VERSION ""

NS_ :

BS_:

BU_: MCU IPU MCU_B BMS ECC VCU EVCC MCU_F HDCU LBMS VCU5_0 VCU_BMS GW EOP Tester IDC

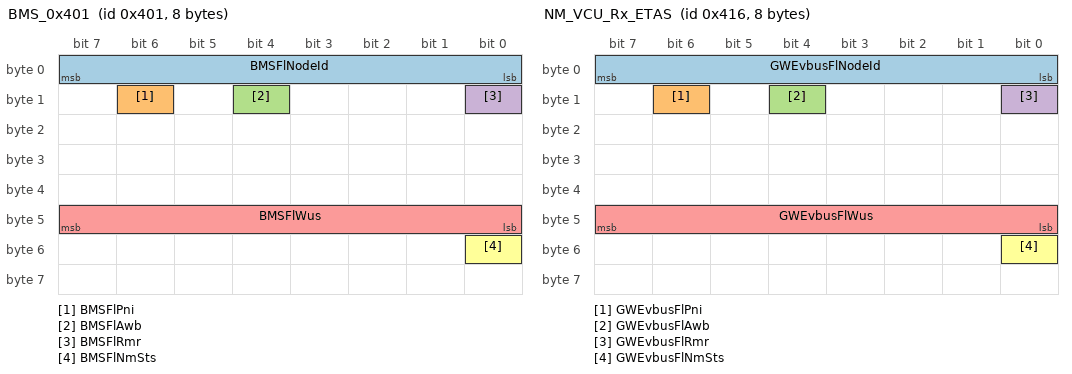
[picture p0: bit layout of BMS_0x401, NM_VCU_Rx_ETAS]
BO_ 1025 BMS_0x401: 8 BMS
 SG_ BMSFlNodeId : 7|8@0+ (1,0) [0|127] ""  IPU,MCU_B,ECC,VCU,EVCC,MCU_F,HDCU,LBMS,VCU5_0,GW,MCU
 SG_ BMSFlPni : 14|1@0+ (1,0) [0|1] ""  IPU,MCU_B,ECC,VCU,EVCC,MCU_F,HDCU,LBMS,VCU5_0,GW,MCU
 SG_ BMSFlAwb : 12|1@0+ (1,0) [0|1] ""  IPU,MCU_B,ECC,VCU,EVCC,MCU_F,HDCU,LBMS,VCU5_0,GW,MCU
 SG_ BMSFlRmr : 8|1@0+ (1,0) [0|1] ""  IPU,MCU_B,ECC,VCU,EVCC,MCU_F,HDCU,LBMS,VCU5_0,GW,MCU
 SG_ BMSFlWus : 47|8@0+ (1,0) [0|255] ""  IPU,MCU_B,ECC,VCU,EVCC,MCU_F,HDCU,LBMS,VCU5_0,GW,MCU
 SG_ BMSFlNmSts : 48|1@0+ (1,0) [0|1] ""  IPU,MCU_B,ECC,VCU,EVCC,MCU_F,HDCU,LBMS,VCU5_0,GW,MCU

BO_ 1046 NM_VCU_Rx_ETAS: 8 GW
 SG_ GWEvbusFlNodeId : 7|8@0+ (1,0) [0|127] ""  IPU,MCU_B,BMS,ECC,VCU,EVCC,MCU_F,HDCU,LBMS,VCU5_0,VCU_BMS,MCU
 SG_ GWEvbusFlPni : 14|1@0+ (1,0) [0|1] ""  IPU,MCU_B,BMS,ECC,VCU,EVCC,MCU_F,HDCU,LBMS,VCU5_0,VCU_BMS,MCU
 SG_ GWEvbusFlAwb : 12|1@0+ (1,0) [0|1] ""  IPU,MCU_B,BMS,ECC,VCU,EVCC,MCU_F,HDCU,LBMS,VCU5_0,VCU_BMS,MCU
 SG_ GWEvbusFlRmr : 8|1@0+ (1,0) [0|1] ""  IPU,MCU_B,BMS,ECC,VCU,EVCC,MCU_F,HDCU,LBMS,VCU5_0,VCU_BMS,MCU
 SG_ GWEvbusFlWus : 47|8@0+ (1,0) [0|255] ""  IPU,MCU_B,BMS,ECC,VCU,EVCC,MCU_F,HDCU,LBMS,VCU5_0,VCU_BMS,MCU
 SG_ GWEvbusFlNmSts : 48|1@0+ (1,0) [0|1] ""  IPU,MCU_B,BMS,ECC,VCU,EVCC,MCU_F,HDCU,LBMS,VCU5_0,VCU_BMS,MCU

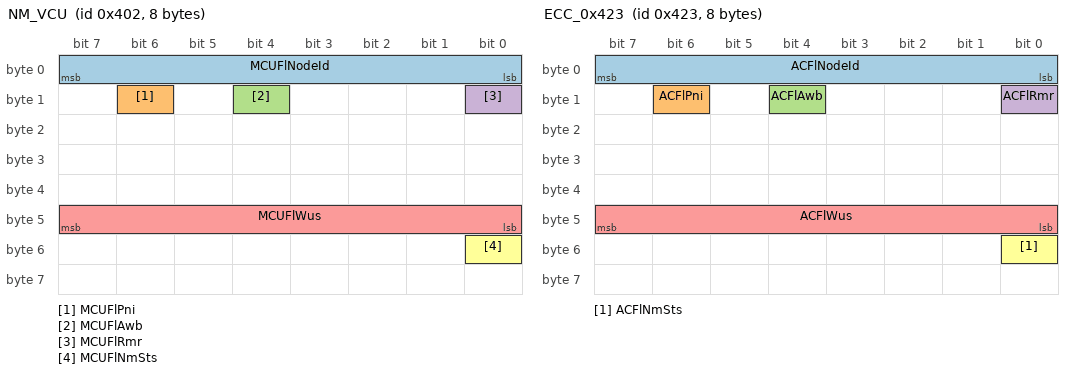
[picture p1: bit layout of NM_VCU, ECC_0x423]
BO_ 1026 NM_VCU: 8 MCU
 SG_ MCUFlNodeId : 7|8@0+ (1,0) [0|127] ""  IPU,BMS,ECC,VCU,EVCC,HDCU,LBMS,VCU5_0,VCU_BMS,GW
 SG_ MCUFlPni : 14|1@0+ (1,0) [0|1] ""  IPU,BMS,ECC,VCU,EVCC,HDCU,LBMS,VCU5_0,VCU_BMS,GW
 SG_ MCUFlAwb : 12|1@0+ (1,0) [0|1] ""  IPU,BMS,ECC,VCU,EVCC,HDCU,LBMS,VCU5_0,VCU_BMS,GW
 SG_ MCUFlRmr : 8|1@0+ (1,0) [0|1] ""  IPU,BMS,ECC,VCU,EVCC,HDCU,LBMS,VCU5_0,VCU_BMS,GW
 SG_ MCUFlWus : 47|8@0+ (1,0) [0|255] ""  IPU,BMS,ECC,VCU,EVCC,HDCU,LBMS,VCU5_0,VCU_BMS,GW
 SG_ MCUFlNmSts : 48|1@0+ (1,0) [0|1] ""  IPU,BMS,ECC,VCU,EVCC,HDCU,LBMS,VCU5_0,VCU_BMS,GW

BO_ 1059 ECC_0x423: 8 ECC
 SG_ ACFlNodeId : 7|8@0+ (1,0) [0|127] ""  IPU,MCU_B,BMS,VCU,LBMS,VCU_BMS,GW,MCU
 SG_ ACFlPni : 14|1@0+ (1,0) [0|1] ""  IPU,MCU_B,BMS,VCU,LBMS,VCU_BMS,GW,MCU
 SG_ ACFlAwb : 12|1@0+ (1,0) [0|1] ""  IPU,MCU_B,BMS,VCU,LBMS,VCU_BMS,GW,MCU
 SG_ ACFlRmr : 8|1@0+ (1,0) [0|1] ""  IPU,MCU_B,BMS,VCU,LBMS,VCU_BMS,GW,MCU
 SG_ ACFlWus : 47|8@0+ (1,0) [0|255] ""  IPU,MCU_B,BMS,VCU,LBMS,VCU_BMS,GW,MCU
 SG_ ACFlNmSts : 48|1@0+ (1,0) [0|1] ""  IPU,MCU_B,BMS,VCU,LBMS,VCU_BMS,GW,MCU

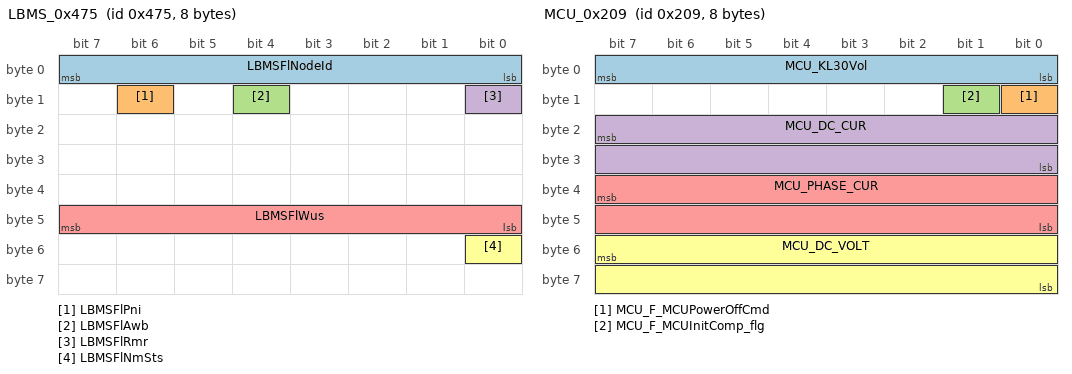
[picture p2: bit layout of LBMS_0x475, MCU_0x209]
BO_ 1141 LBMS_0x475: 8 LBMS
 SG_ LBMSFlNodeId : 7|8@0+ (1,0) [0|127] ""  IPU,MCU_B,BMS,ECC,VCU,EVCC,MCU_F,HDCU,VCU5_0,VCU_BMS,GW,MCU
 SG_ LBMSFlPni : 14|1@0+ (1,0) [0|1] ""  IPU,MCU_B,BMS,ECC,VCU,EVCC,MCU_F,HDCU,VCU5_0,VCU_BMS,GW,MCU
 SG_ LBMSFlAwb : 12|1@0+ (1,0) [0|1] ""  IPU,MCU_B,BMS,ECC,VCU,EVCC,MCU_F,HDCU,VCU5_0,VCU_BMS,GW,MCU
 SG_ LBMSFlRmr : 8|1@0+ (1,0) [0|1] ""  IPU,MCU_B,BMS,ECC,VCU,EVCC,MCU_F,HDCU,VCU5_0,VCU_BMS,GW,MCU
 SG_ LBMSFlWus : 47|8@0+ (1,0) [0|255] ""  IPU,MCU_B,BMS,ECC,VCU,EVCC,MCU_F,HDCU,VCU5_0,VCU_BMS,GW,MCU
 SG_ LBMSFlNmSts : 48|1@0+ (1,0) [0|1] ""  IPU,MCU_B,BMS,ECC,VCU,EVCC,MCU_F,HDCU,VCU5_0,VCU_BMS,GW,MCU

BO_ 521 MCU_0x209: 8 MCU_B
 SG_ MCU_KL30Vol : 7|8@0+ (0.1,0) [0|25.5] ""  GW
 SG_ MCU_F_MCUPowerOffCmd : 8|1@0+ (1,0) [0|1] ""  GW
 SG_ MCU_F_MCUInitComp_flg : 9|1@0+ (1,0) [0|1] ""  GW
 SG_ MCU_DC_CUR : 23|16@0+ (0.1,-3276.8) [-3276.8|3276.7] "A"  BMS,VCU,VCU5_0,VCU_BMS,GW
 SG_ MCU_PHASE_CUR : 39|16@0+ (0.1,-3276.8) [-3276.8|3276.7] "A"  VCU,VCU5_0,VCU_BMS,GW
 SG_ MCU_DC_VOLT : 55|16@0+ (0.02,0) [0|1310.68] "V"  BMS,VCU,VCU5_0,VCU_BMS,GW

BO_ 296 MCU_0x128: 24 MCU
 SG_ dmc_dTcsDbgSignal1_M1 : 7|8@0+ (1,0) [0|255] ""  GW
 SG_ dmc_TcsDbgSiqnal2_M1 : 14|15@0+ (1,0) [0|32767] ""  GW
 SG_ dmc_dTcsDbgSignal3_M1 : 30|15@0+ (1,0) [0|32767] "rpm"  GW
 SG_ dmc_dTcsDbgSignal4_M1 : 47|8@0+ (1,0) [0|255] ""  GW
 SG_ dmc_dTcsDbgSignal5_M1 : 55|8@0+ (1,0) [0|255] ""  GW
 SG_ DmcFrtDTCSOperaMode : 58|3@0+ (1,0) [0|7] ""  GW
 SG_ dmc_dTcsDbgSignal6_M1 : 71|16@0+ (1,-32767) [-32767|32767] "N.m"  GW
 SG_ dmc_dTcsDbgSignal7_M1 : 87|16@0+ (1,-32767) [-32767|32767] "N.m"  GW
 SG_ dmc_dTcsDbgSignal8_M1 : 103|16@0+ (1,-32767) [-32767|32767] "N.m"  GW
 SG_ dmc_dTcsDbgSignal9_M1 : 119|16@0+ (1,-32767) [-32767|32767] "N.m"  GW
 SG_ dmc_drcsDbgSignal10_M1 : 134|15@0+ (1,0) [0|32767] ""  GW
 SG_ dmc_drcsDbgSignal11_M1 : 151|16@0+ (1,-32767) [-32767|32767] "N.m"  GW
 SG_ dmc_drcsDbgSignal12_M1 : 167|16@0+ (1,-32767) [-32767|32767] "N.m"  GW
 SG_ DmcFrtDTCSTargTorq : 183|16@0+ (1,-32767) [-32767|32767] "N.m"  GW

BO_ 1152 OBC_0x480: 16 IPU
 SG_ IPUCPAmp : 23|8@0+ (0.1,0) [0|25.5] "V"  HDCU,VCU5_0,GW
 SG_ OBC_DCCrt : 31|16@0+ (0.02,0) [0|1310.68] "A"  BMS,VCU,HDCU,VCU5_0,VCU_BMS,GW
 SG_ OBC_DCVolt : 47|16@0+ (0.02,0) [0|1310.68] "V"  BMS,VCU,HDCU,VCU5_0,VCU_BMS,GW
 SG_ IPUCPDutyRat : 63|8@0+ (1,0) [0|100] "%"  HDCU,VCU5_0,GW
 SG_ IPUWakupsou : 87|8@0+ (1,0) [0|255] ""  HDCU,VCU5_0,GW
 SG_ IPUCPDir : 89|2@0+ (1,0) [0|3] ""  HDCU,VCU5_0,GW
 SG_ IPUHeatReqFlg : 91|2@0+ (1,0) [0|3] ""  BMS,ECC,VCU,VCU5_0,VCU_BMS,GW
 SG_ IPUCCR : 103|16@0+ (1,0) [0|4095] "Ω"  HDCU,VCU5_0,GW
 SG_ IPUCPFrq : 119|16@0+ (1,0) [0|2000] "Hz"  HDCU,VCU5_0,GW

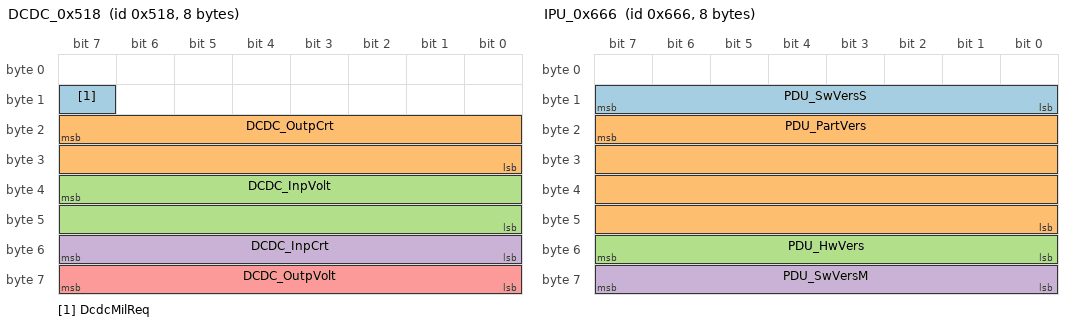
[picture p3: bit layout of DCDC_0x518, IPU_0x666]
BO_ 1304 DCDC_0x518: 8 IPU
 SG_ DcdcMilReq : 15|1@0+ (1,0) [0|1] ""  HDCU,GW
 SG_ DCDC_OutpCrt : 23|16@0+ (0.01,0) [0|300] "A"  VCU,HDCU,LBMS,VCU5_0,VCU_BMS,GW
 SG_ DCDC_InpVolt : 39|16@0+ (0.02,0) [0|1310.68] "V"  BMS,VCU,HDCU,VCU5_0,VCU_BMS,GW
 SG_ DCDC_InpCrt : 55|8@0+ (0.1,0) [0|25.4] "A"  BMS,VCU,HDCU,VCU5_0,VCU_BMS,GW
 SG_ DCDC_OutpVolt : 63|8@0+ (0.1,0) [0|25.5] "V"  VCU,HDCU,LBMS,VCU5_0,VCU_BMS,GW

BO_ 1313 DCDC_0x521: 8 IPU
 SG_ DCDC_InpOverVoltSwFlt : 16|1@0+ (1,0) [0|1] ""  VCU,HDCU,VCU5_0,VCU_BMS,GW
 SG_ DCDC_InpUnderVoltFlt : 17|1@0+ (1,0) [0|1] ""  VCU,HDCU,VCU5_0,VCU_BMS,GW
 SG_ DCDC_LVOutpOverVoltFlt : 18|1@0+ (1,0) [0|1] ""  VCU,HDCU,VCU5_0,VCU_BMS,GW
 SG_ DCDC_LVOutpUnderVoltFlt : 19|1@0+ (1,0) [0|1] ""  VCU,HDCU,VCU5_0,VCU_BMS,GW
 SG_ PDU_BusoffFlt : 20|1@0+ (1,0) [0|1] ""  VCU,HDCU,VCU5_0,VCU_BMS,GW
 SG_ DCDC_OverTTurnDwnLoadFlt : 21|1@0+ (1,0) [0|1] ""  VCU,HDCU,VCU5_0,VCU_BMS,GW
 SG_ IPU_ComCheckErr : 22|1@0+ (1,0) [0|1] ""  VCU,HDCU,VCU5_0,VCU_BMS,GW
 SG_ DCDC_InpCurOverSwFlt : 23|1@0+ (1,0) [0|1] ""  VCU,HDCU,VCU5_0,VCU_BMS,GW
 SG_ DCDC_OverTShutDwnFlt : 24|1@0+ (1,0) [0|1] ""  VCU,HDCU,VCU5_0,VCU_BMS,GW
 SG_ DCDC_StsAlrmFlt : 25|1@0+ (1,0) [0|1] ""  VCU,HDCU,VCU5_0,VCU_BMS,GW
 SG_ DCDC_CrtStsGB : 27|2@0+ (1,0) [0|2] ""  HDCU,GW
 SG_ DCDC_LVOutpOverCurrFlt : 28|1@0+ (1,0) [0|1] ""  VCU,HDCU,VCU5_0,VCU_BMS,GW
 SG_ IPU_KL30Vol : 39|8@0+ (0.1,0) [0|25.5] "V"  VCU,HDCU,VCU5_0,VCU_BMS,GW
 SG_ DCDC_St_TMP : 47|8@0+ (1,-48) [-48|206] "℃"  VCU,HDCU,VCU5_0,VCU_BMS,GW
 SG_ DCDC_INPUT_VOLT_CHECK_FLT : 48|1@0+ (1,0) [0|1] ""  VCU,HDCU,VCU5_0,VCU_BMS,GW
 SG_ DCDC_OUTPUT_VOLT_CHECK_FLT : 49|1@0+ (1,0) [0|1] ""  VCU,HDCU,VCU5_0,VCU_BMS,GW
 SG_ DCDC_IntFlt : 50|1@0+ (1,0) [0|1] ""  VCU,HDCU,VCU5_0,VCU_BMS,GW
 SG_ DCDC_ComLostFlt_PDCU : 51|1@0+ (1,0) [0|1] ""  VCU,HDCU,VCU5_0,VCU_BMS,GW
 SG_ DCDC_OutpShoCircFlt : 52|1@0+ (1,0) [0|1] ""  VCU,HDCU,VCU5_0,VCU_BMS,GW
 SG_ DCDC_CrtSts : 54|2@0+ (1,0) [0|3] ""  BMS,ECC,VCU,HDCU,LBMS,VCU5_0,VCU_BMS,GW
 SG_ BoostCurOverFlt : 55|1@0+ (1,0) [0|1] ""  VCU,HDCU,VCU5_0,VCU_BMS,GW
 SG_ DCDC_T : 63|8@0+ (1,-40) [-40|215] "℃"  BMS,VCU,HDCU,VCU5_0,VCU_BMS,GW

BO_ 1638 IPU_0x666: 8 IPU
 SG_ PDU_SwVersS : 15|8@0+ (1,0) [0|255] ""  VCU,HDCU,VCU5_0,VCU_BMS,GW
 SG_ PDU_PartVers : 23|32@0+ (1,0) [0|4294967295] ""  VCU,HDCU,VCU5_0,VCU_BMS,GW
 SG_ PDU_HwVers : 55|8@0+ (1,0) [0|255] ""  VCU,HDCU,VCU5_0,VCU_BMS,GW
 SG_ PDU_SwVersM : 63|8@0+ (1,0) [0|255] ""  VCU,HDCU,VCU5_0,VCU_BMS,GW

BO_ 1746 OBC_0x6D2: 8 IPU
 SG_ OBC_HVDCOutpOverCrtHwFlt : 16|1@0+ (1,0) [0|1] ""  VCU,HDCU,VCU5_0,VCU_BMS,GW
 SG_ OBC_HVDCOutpShortFlt : 17|1@0+ (1,0) [0|1] ""  VCU,HDCU,VCU5_0,VCU_BMS,GW
 SG_ PFC_PowFreMOSOverTFlt : 18|1@0+ (1,0) [0|1] ""  VCU,HDCU,VCU5_0,VCU_BMS,GW
 SG_ OBC_ACVoltOverVoltFlt : 19|1@0+ (1,0) [0|1] ""  VCU,HDCU,VCU5_0,VCU_BMS,GW
 SG_ OBC_ACVoltUnderVoltFlt : 20|1@0+ (1,0) [0|1] ""  VCU,HDCU,VCU5_0,VCU_BMS,GW
 SG_ OBC_HVDCOutpOverVoltSwFlt : 21|1@0+ (1,0) [0|1] ""  VCU,HDCU,VCU5_0,VCU_BMS,GW
 SG_ OBC_HVDCOutpUnderVoltFlt : 22|1@0+ (1,0) [0|1] ""  VCU,HDCU,VCU5_0,VCU_BMS,GW
 SG_ OBC_InpCrtOverCrtHwSwFlt : 23|1@0+ (1,0) [0|1] ""  VCU,HDCU,VCU5_0,VCU_BMS,GW
 SG_ PFC_MOSOverTFlt : 24|1@0+ (1,0) [0|1] ""  VCU,HDCU,VCU5_0,VCU_BMS,GW
 SG_ LLC_OriSideMOSOverTFlt : 25|1@0+ (1,0) [0|1] ""  VCU,HDCU,VCU5_0,VCU_BMS,GW
 SG_ OBC_ACPoweroff : 26|1@0+ (1,0) [0|1] ""  GW
 SG_ DiscCPSIGErr : 27|1@0+ (1,0) [0|1] ""  HDCU,GW
 SG_ OBC_LVOutpOverVoltFlt : 28|1@0+ (1,0) [0|1] ""  VCU,HDCU,VCU5_0,VCU_BMS,GW
 SG_ OBC_LiquidOverTShutDwnFlt : 29|1@0+ (1,0) [0|1] ""  VCU,HDCU,VCU5_0,VCU_BMS,GW
 SG_ OBC_LiquidOverTDwnPwrFlt : 30|1@0+ (1,0) [0|1] ""  VCU,HDCU,VCU5_0,VCU_BMS,GW
 SG_ LLC_SenSideMOSOverTFlt : 31|1@0+ (1,0) [0|1] ""  VCU,HDCU,VCU5_0,VCU_BMS,GW
 SG_ OBC_HVDCOutpOverVoltHwFlt : 32|1@0+ (1,0) [0|1] ""  HDCU,GW
 SG_ OBC_INVOutpShortFlt : 33|1@0+ (1,0) [0|1] ""  HDCU,GW
 SG_ OBC_INVOutpOverLoadFlt : 34|1@0+ (1,0) [0|1] ""  HDCU,GW
 SG_ OBC_PfcCllcSciLost : 35|1@0+ (1,0) [0|1] ""  HDCU,GW
 SG_ OBC_IntOverTFlt : 36|1@0+ (1,0) [0|1] ""  VCU,HDCU,VCU5_0,VCU_BMS,GW
 SG_ OBC_IntFlt : 37|1@0+ (1,0) [0|1] ""  VCU,HDCU,VCU5_0,VCU_BMS,GW
 SG_ BOBC_OverTFlt : 38|1@0+ (1,0) [0|1] ""  VCU,HDCU,VCU5_0,VCU_BMS,GW
 SG_ PFCBusOverVoltFlt : 39|1@0+ (1,0) [0|1] ""  VCU,HDCU,VCU5_0,VCU_BMS,GW
 SG_ OBC_HVDCOutpOverCrtSwFlt : 40|1@0+ (1,0) [0|1] ""  VCU,HDCU,VCU5_0,VCU_BMS,GW
 SG_ OBC_ACCrtChkCircFlt : 41|1@0+ (1,0) [0|1] ""  VCU,HDCU,VCU5_0,VCU_BMS,GW
 SG_ PFCBusUnderVoltFlt : 42|1@0+ (1,0) [0|1] ""  VCU,HDCU,VCU5_0,VCU_BMS,GW
 SG_ OBC_INVOutpOverVoltFlt : 43|1@0+ (1,0) [0|1] ""  VCU,HDCU,VCU5_0,VCU_BMS,GW
 SG_ OBC_INVOutpUnderVoltFlt : 44|1@0+ (1,0) [0|1] ""  VCU,HDCU,VCU5_0,VCU_BMS,GW
 SG_ OBC_INVInpOverVoltFlt : 45|1@0+ (1,0) [0|1] ""  VCU,HDCU,VCU5_0,VCU_BMS,GW
 SG_ OBC_INVInpUnderVoltFlt : 46|1@0+ (1,0) [0|1] ""  VCU,HDCU,VCU5_0,VCU_BMS,GW
 SG_ OBC_INVOutpOverCurrSlowFlt : 47|1@0+ (1,0) [0|1] ""  VCU,HDCU,VCU5_0,VCU_BMS,GW
 SG_ ACInputPhaTypeFlt : 48|1@0+ (1,0) [0|1] ""  VCU,HDCU,VCU5_0,VCU_BMS,GW
 SG_ CLLCChaStsInpUnderVoltFlt : 49|1@0+ (1,0) [0|1] ""  VCU,HDCU,VCU5_0,VCU_BMS,GW
 SG_ BOBC_CCSIG_ERR : 50|1@0+ (1,0) [0|1] ""  VCU,HDCU,VCU5_0,VCU_BMS,GW
 SG_ BOBC_CPSIG_ERR : 51|1@0+ (1,0) [0|1] ""  VCU,HDCU,VCU5_0,VCU_BMS,GW
 SG_ OBC_LVOutpUnderVoltFlt : 52|1@0+ (1,0) [0|1] ""  VCU,HDCU,VCU5_0,VCU_BMS,GW
 SG_ BOBC_PowOverVoltHwFlt : 53|1@0+ (1,0) [0|1] ""  VCU,HDCU,VCU5_0,VCU_BMS,GW
 SG_ ACFreLowFlt : 54|1@0+ (1,0) [0|1] ""  VCU,HDCU,VCU5_0,VCU_BMS,GW
 SG_ ACFreHighFlt : 55|1@0+ (1,0) [0|1] ""  VCU,HDCU,VCU5_0,VCU_BMS,GW
 SG_ BOBC_BatOverCurrHwFlt : 56|1@0+ (1,0) [0|1] ""  VCU,HDCU,VCU5_0,VCU_BMS,GW
 SG_ OBC_InpCrtOverCrtHwFlt : 57|1@0+ (1,0) [0|1] ""  VCU,HDCU,VCU5_0,VCU_BMS,GW
 SG_ OBC_ACVoltFreqFlt : 58|1@0+ (1,0) [0|1] ""  VCU,HDCU,VCU5_0,VCU_BMS,GW
 SG_ BUSMidVoltFlt : 59|1@0+ (1,0) [0|1] ""  VCU,HDCU,VCU5_0,VCU_BMS,GW
 SG_ OBC_ACSCIntlkSigChkCircFlt : 60|1@0+ (1,0) [0|1] ""  VCU,HDCU,VCU5_0,VCU_BMS,GW
 SG_ OBC_PTCIntlkSigChkCircFlt : 61|1@0+ (1,0) [0|1] ""  VCU,HDCU,VCU5_0,VCU_BMS,GW
 SG_ OBC_PwrBattIntlkSigChkCircFlt : 62|1@0+ (1,0) [0|1] ""  VCU,HDCU,VCU5_0,VCU_BMS,GW
 SG_ OBC_INVCllcBusOverVoltFlt : 63|1@0+ (1,0) [0|1] ""  VCU,HDCU,VCU5_0,VCU_BMS,GW

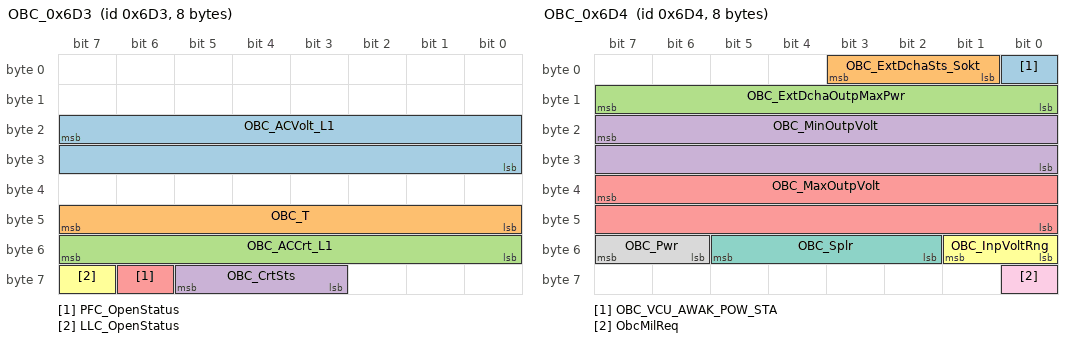
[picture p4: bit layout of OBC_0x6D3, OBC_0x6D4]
BO_ 1747 OBC_0x6D3: 8 IPU
 SG_ OBC_ACVolt_L1 : 23|16@0+ (0.02,0) [0|1310.68] "V"  BMS,VCU,EVCC,HDCU,VCU5_0,VCU_BMS,GW
 SG_ OBC_T : 47|8@0+ (1,-48) [-48|206] "℃"  ECC,VCU,HDCU,VCU5_0,VCU_BMS,GW
 SG_ OBC_ACCrt_L1 : 55|8@0+ (0.5,0) [0|127] "A"  BMS,VCU,EVCC,HDCU,VCU5_0,VCU_BMS,GW
 SG_ OBC_CrtSts : 61|3@0+ (1,0) [0|7] ""  BMS,ECC,VCU,HDCU,VCU5_0,VCU_BMS,GW
 SG_ PFC_OpenStatus : 62|1@0+ (1,0) [0|1] ""  VCU,HDCU,VCU5_0,VCU_BMS,GW
 SG_ LLC_OpenStatus : 63|1@0+ (1,0) [0|1] ""  VCU,HDCU,VCU5_0,VCU_BMS,GW

BO_ 1748 OBC_0x6D4: 8 IPU
 SG_ OBC_VCU_AWAK_POW_STA : 0|1@0+ (1,0) [0|1] ""  BMS,VCU,HDCU,VCU5_0,VCU_BMS,GW
 SG_ OBC_ExtDchaSts_Sokt : 3|3@0+ (1,0) [0|7] ""  VCU,HDCU,VCU5_0,VCU_BMS,GW
 SG_ OBC_ExtDchaOutpMaxPwr : 15|8@0+ (0.1,0) [0|25.5] "kW"  VCU,HDCU,VCU5_0,VCU_BMS,GW
 SG_ OBC_MinOutpVolt : 23|16@0+ (0.02,0) [0|1310.68] "V"  VCU,HDCU,VCU5_0,VCU_BMS,GW
 SG_ OBC_MaxOutpVolt : 39|16@0+ (0.02,0) [0|1310.68] "V"  VCU,HDCU,VCU5_0,VCU_BMS,GW
 SG_ OBC_InpVoltRng : 49|2@0+ (1,0) [0|3] ""  VCU,HDCU,VCU5_0,VCU_BMS,GW
 SG_ OBC_Splr : 53|4@0+ (1,0) [0|15] ""  VCU,HDCU,VCU5_0,VCU_BMS,GW
 SG_ OBC_Pwr : 55|2@0+ (1,0) [0|3] ""  BMS,VCU,HDCU,VCU5_0,VCU_BMS,GW
 SG_ ObcMilReq : 56|1@0+ (1,0) [0|1] ""  HDCU,GW

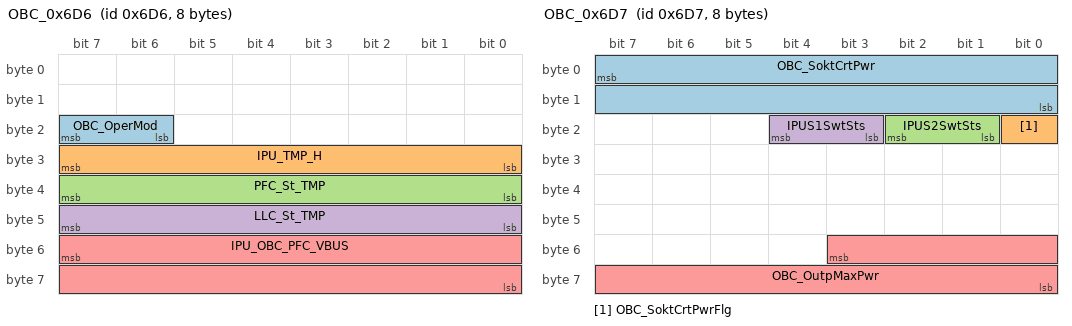
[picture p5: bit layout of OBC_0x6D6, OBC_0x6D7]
BO_ 1750 OBC_0x6D6: 8 IPU
 SG_ OBC_OperMod : 23|2@0+ (1,0) [0|3] ""  BMS,VCU,HDCU,VCU5_0,VCU_BMS,GW
 SG_ IPU_TMP_H : 31|8@0+ (1,-48) [-48|206] "℃"  BMS,VCU,HDCU,VCU5_0,VCU_BMS,GW
 SG_ PFC_St_TMP : 39|8@0+ (1,-48) [-48|206] "℃"  BMS,VCU,HDCU,VCU5_0,VCU_BMS,GW
 SG_ LLC_St_TMP : 47|8@0+ (1,-48) [-48|206] "℃"  BMS,VCU,HDCU,VCU5_0,VCU_BMS,GW
 SG_ IPU_OBC_PFC_VBUS : 55|16@0+ (0.02,0) [0|1310.68] "V"  BMS,VCU,HDCU,VCU5_0,VCU_BMS,GW

BO_ 1751 OBC_0x6D7: 8 IPU
 SG_ OBC_SoktCrtPwr : 7|16@0+ (0.1,0) [0|6553.5] "W"  VCU,HDCU,VCU5_0,VCU_BMS,GW
 SG_ OBC_SoktCrtPwrFlg : 16|1@0+ (1,0) [0|1] ""  VCU,HDCU,VCU5_0,VCU_BMS,GW
 SG_ IPUS2SwtSts : 18|2@0+ (1,0) [0|3] ""  HDCU,VCU5_0,GW
 SG_ IPUS1SwtSts : 20|2@0+ (1,0) [0|3] ""  HDCU,VCU5_0,GW
 SG_ OBC_OutpMaxPwr : 51|12@0+ (0.01,0) [0|20] "kW"  BMS,VCU,HDCU,VCU5_0,VCU_BMS,GW

BO_ 1324 ECC_VCU_0x52C: 64 ECC
 SG_ EWP_FD_Sts : 31|2@0+ (1,0) [0|3] ""  MCU_B,VCU,VCU_BMS,GW,MCU

BO_ 1010 ECC_AAC_VCU_0x3F2: 8 ECC
 SG_ OutdT : 23|8@0+ (0.5,-40) [-40|85] "deg. C"  IPU,BMS,VCU,MCU_F,HDCU,LBMS,VCU_BMS,MCU
 SG_ OutdTVld : 50|3@0+ (1,0) [0|7] ""  IPU,BMS,VCU,HDCU,LBMS,VCU_BMS,MCU

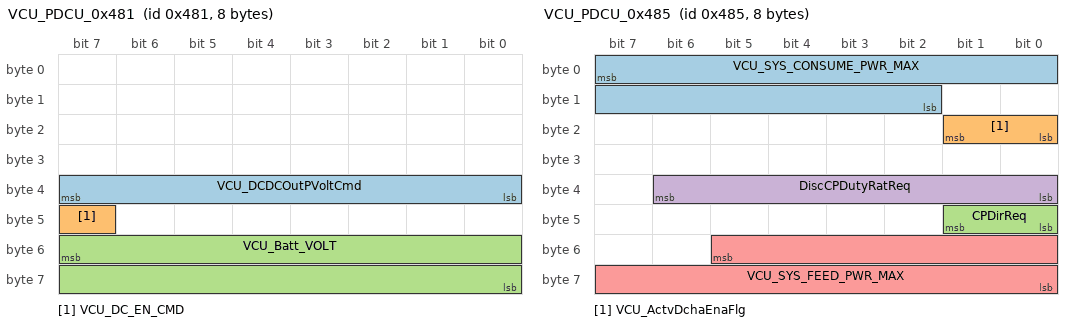
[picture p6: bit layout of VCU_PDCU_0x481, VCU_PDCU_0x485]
BO_ 1153 VCU_PDCU_0x481: 8 VCU
 SG_ VCU_DCDCOutPVoltCmd : 39|8@0+ (0.1,0) [0|25.5] "v"  IPU,GW,MCU
 SG_ VCU_DC_EN_CMD : 47|1@0+ (1,0) [0|1] ""  IPU,GW,MCU
 SG_ VCU_Batt_VOLT : 55|16@0+ (0.001,0) [0|65.535] ""  MCU_B,GW,MCU

BO_ 1156 VCU_PDCU_0x484: 16 VCU
 SG_ VCU_SOCKET_PERM_POW_MAX : 39|8@0+ (0.1,0) [0|25.5] "kW"  IPU,GW,MCU
 SG_ VCU_OBC_CHG_POW_MAX : 47|8@0+ (0.1,0) [0|25.5] "kW"  IPU,GW,MCU
 SG_ VCU_SOCKET_ENA_CMD : 53|1@0+ (1,0) [0|1] ""  IPU,BMS,GW,MCU

BO_ 1157 VCU_PDCU_0x485: 8 VCU
 SG_ VCU_SYS_CONSUME_PWR_MAX : 7|14@0+ (0.1,0) [0|1310.7] "kW"  MCU_B,GW,MCU
 SG_ VCU_ActvDchaEnaFlg : 17|2@0+ (1,0) [0|3] ""  MCU_B,ECC,MCU_F,GW,MCU
 SG_ CPDirReq : 41|2@0+ (1,0) [0|3] ""  IPU,GW,MCU
 SG_ DiscCPDutyRatReq : 38|7@0+ (1,0) [0|100] ""  IPU,GW,MCU
 SG_ VCU_SYS_FEED_PWR_MAX : 53|14@0+ (0.1,0) [0|1310.7] "kW"  MCU_B,GW,MCU

BO_ 1161 MCU_0x489: 16 MCU_B
 SG_ MCU_F_DrvrMot1CrtSts : 2|3@0+ (1,0) [0|7] ""  GW
 SG_ FroMcuWorkSta : 7|5@0+ (1,0) [0|31] ""  GW
 SG_ MCU_F_UIGBTTemp0 : 15|8@0+ (1,-48) [-48|207] ""  GW
 SG_ MCU_EEPROM_STS : 23|8@0+ (1,0) [0|255] ""  GW
 SG_ MCU_F_UIGBTTemp1 : 31|8@0+ (1,-48) [-48|207] ""  GW
 SG_ MCU_F_VIGBTTemp0 : 39|8@0+ (1,-48) [-48|207] ""  GW
 SG_ MCU_F_VIGBTTemp1 : 47|8@0+ (1,-48) [-48|207] ""  GW
 SG_ MCU_F_WIGBTTemp0 : 55|8@0+ (1,-48) [-48|207] ""  GW
 SG_ MCU_F_WIGBTTemp1 : 63|8@0+ (1,-48) [-48|207] ""  GW
 SG_ MCU_I2TEnable : 126|1@0+ (1,0) [0|1] ""  GW

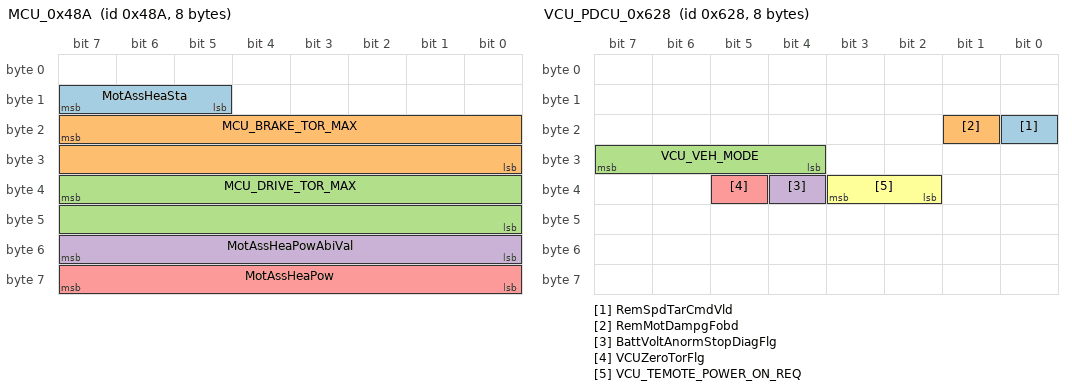
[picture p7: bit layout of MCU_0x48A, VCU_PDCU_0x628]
BO_ 1162 MCU_0x48A: 8 MCU_B
 SG_ MotAssHeaSta : 15|3@0+ (1,0) [0|7] ""  BMS,VCU,VCU5_0,VCU_BMS,GW
 SG_ MCU_BRAKE_TOR_MAX : 23|16@0+ (0.1,-3276.8) [-3276.8|3276.7] "Nm"  VCU,VCU5_0,VCU_BMS,GW
 SG_ MCU_DRIVE_TOR_MAX : 39|16@0+ (0.02,0) [0|1310.7] "Nm"  VCU,VCU5_0,VCU_BMS,GW
 SG_ MotAssHeaPowAbiVal : 55|8@0+ (0.1,0) [0|25.5] "Kw"  VCU,VCU5_0,VCU_BMS,GW
 SG_ MotAssHeaPow : 63|8@0+ (0.1,0) [0|25.5] "Kw"  ECC,VCU,VCU5_0,VCU_BMS,GW

BO_ 1163 VCU_PDCU_0x48B: 8 VCU
 SG_ VCU_BRAKE_ENGERY_RECOV_STA : 16|1@0+ (1,0) [0|1] ""  MCU_B,GW,MCU

BO_ 1297 VCU_PDCU_0x511: 8 VCU
 SG_ VCU_VehRemRefrshModReq : 62|2@0+ (1,0) [0|3] ""  IPU,MCU_B,BMS,ECC,GW,MCU

BO_ 1397 VCU_PDCU_0x575: 8 VCU
 SG_ VCU_ExhibitionMode : 41|2@0+ (1,0) [0|3] ""  MCU_B,GW,MCU

BO_ 1558 VCU_PDCU_0x616: 8 VCU
 SG_ VCU_DRIVE_RANGE : 55|16@0+ (0.1,0) [0|6553.5] "km"  MCU_B,BMS,GW,MCU

BO_ 1559 VCU_PDCU_0x617: 8 VCU
 SG_ VCU_VEH_SPD : 23|16@0+ (0.01,0) [0|655.35] "km/h"  MCU_B,BMS,GW,MCU

BO_ 1574 VCU_PDCU_0x626: 8 VCU
 SG_ VCU_ComLostFlt_ESP : 35|1@0+ (1,0) [0|1] ""  MCU_B,GW,MCU

BO_ 1576 VCU_PDCU_0x628: 8 VCU
 SG_ RemSpdTarCmdVld : 16|1@0+ (1,0) [0|1] ""  MCU_B,GW,MCU
 SG_ RemMotDampgFobd : 17|1@0+ (1,0) [0|1] ""  MCU_B,GW,MCU
 SG_ VCU_VEH_MODE : 31|4@0+ (1,0) [0|13] ""  MCU_B,BMS,GW,MCU
 SG_ BattVoltAnormStopDiagFlg : 36|1@0+ (1,0) [0|1] ""  MCU_B,GW,MCU
 SG_ VCUZeroTorFlg : 37|1@0+ (1,0) [0|1] ""  MCU_B,GW,MCU
 SG_ VCU_TEMOTE_POWER_ON_REQ : 35|2@0+ (1,0) [0|3] ""  MCU_B,GW,MCU

BO_ 1585 VCU_PDCU_0x631: 8 VCU
 SG_ VCU_Socket_SWH_REQ_CMD : 47|2@0+ (1,0) [0|3] ""  IPU,BMS,GW,MCU

BO_ 1588 VCU_PDCU_0x634: 8 VCU
 SG_ VCU_ACChrgCrtUpprLmt : 30|7@0+ (1,0) [0|100] ""  IPU,GW,MCU

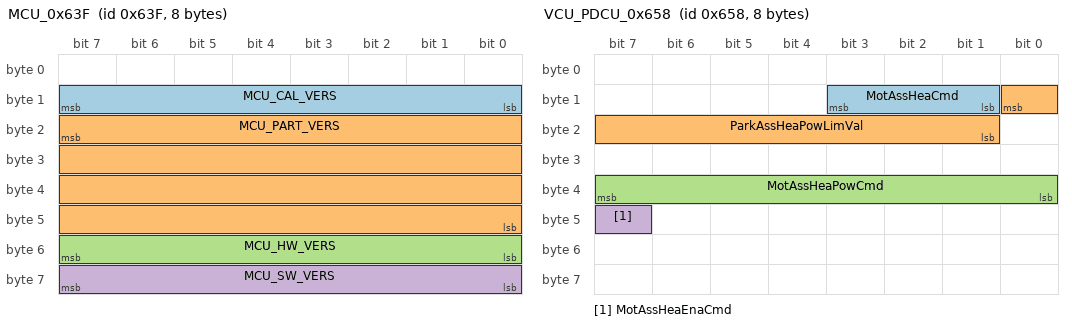
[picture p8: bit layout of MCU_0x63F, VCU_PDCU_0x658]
BO_ 1599 MCU_0x63F: 8 MCU_B
 SG_ MCU_CAL_VERS : 15|8@0+ (1,0) [0|255] ""  VCU,VCU5_0,VCU_BMS,GW
 SG_ MCU_PART_VERS : 23|32@0+ (1,0) [0|4294967295] ""  VCU,VCU5_0,VCU_BMS,GW
 SG_ MCU_HW_VERS : 55|8@0+ (1,0) [0|255] ""  VCU,VCU5_0,VCU_BMS,GW
 SG_ MCU_SW_VERS : 63|8@0+ (1,0) [0|255] ""  VCU,VCU5_0,VCU_BMS,GW

BO_ 1614 VCU_PDCU_0x64E: 8 VCU
 SG_ VCU_COLL_SIG_STA : 19|1@0+ (1,0) [0|1] ""  IPU,ECC,GW,MCU

BO_ 1624 VCU_PDCU_0x658: 8 VCU
 SG_ MotAssHeaCmd : 11|3@0+ (1,0) [0|7] ""  MCU_B,GW,MCU
 SG_ ParkAssHeaPowLimVal : 8|8@0+ (0.1,0) [0|25.5] "Kw"  MCU_B,GW,MCU
 SG_ MotAssHeaPowCmd : 39|8@0+ (0.1,0) [0|25.5] "Kw"  MCU_B,GW,MCU
 SG_ MotAssHeaEnaCmd : 47|1@0+ (1,0) [0|1] ""  MCU_B,GW,MCU

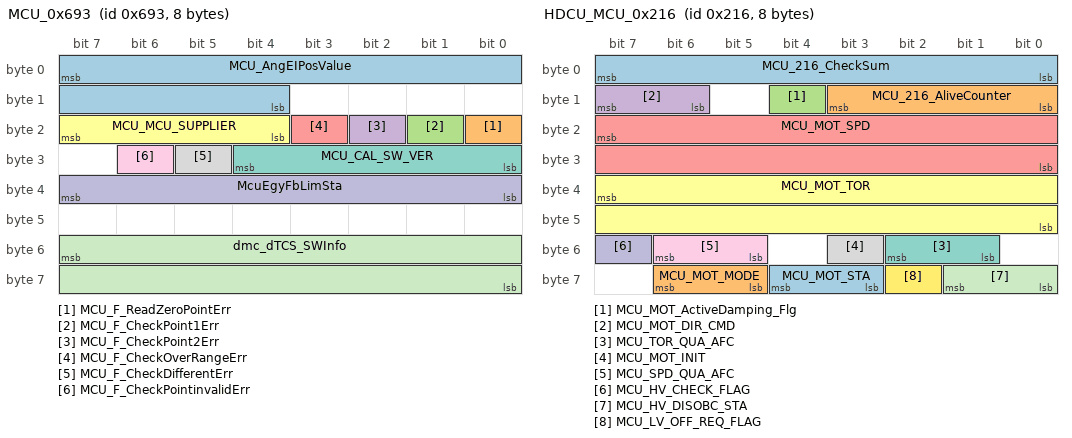
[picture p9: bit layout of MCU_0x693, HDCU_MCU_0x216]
BO_ 1683 MCU_0x693: 8 MCU_B
 SG_ MCU_AngEIPosValue : 7|12@0+ (1,0) [0|4095] ""  GW
 SG_ MCU_F_ReadZeroPointErr : 16|1@0+ (1,0) [0|1] ""  GW
 SG_ MCU_F_CheckPoint1Err : 17|1@0+ (1,0) [0|1] ""  GW
 SG_ MCU_F_CheckPoint2Err : 18|1@0+ (1,0) [0|1] ""  GW
 SG_ MCU_F_CheckOverRangeErr : 19|1@0+ (1,0) [0|1] ""  GW
 SG_ MCU_MCU_SUPPLIER : 23|4@0+ (1,0) [0|15] ""  BMS,VCU,VCU5_0,VCU_BMS,GW
 SG_ MCU_CAL_SW_VER : 28|5@0+ (1,0) [0|31] ""  VCU,VCU5_0,VCU_BMS,GW
 SG_ MCU_F_CheckDifferentErr : 29|1@0+ (1,0) [0|1] ""  GW
 SG_ MCU_F_CheckPointinvalidErr : 30|1@0+ (1,0) [0|1] ""  GW
 SG_ McuEgyFbLimSta : 39|8@0+ (1,0) [0|255] ""  GW
 SG_ dmc_dTCS_SWInfo : 55|16@0+ (1,0) [0|65535] ""  GW

BO_ 1728 VCU_PDCU_0x6C0: 16 VCU
 SG_ VCU_READY_LAMP : 31|1@0+ (1,0) [0|1] ""  MCU_B,BMS,MCU_F,GW,MCU
 SG_ VCU_MEN_CHGR_MILG_THD : 47|8@0+ (1,0) [0|255] "Km"  MCU_B,GW,MCU

BO_ 1739 MCU_MCUF_0x6CB: 16 MCU_B
 SG_ MCU_Motor_SUM : 7|8@0+ (1,0) [0|255] ""  VCU,VCU5_0,VCU_BMS,GW
 SG_ McuMotorNum : 15|8@0+ (1,0) [1|253] ""  GW
 SG_ MCU_MCU_F_SUM : 23|8@0+ (1,0) [0|252] ""  VCU,VCU5_0,VCU_BMS,GW
 SG_ McuIgbtTemp : 31|8@0+ (1,-40) [-40|210] "℃"  GW
 SG_ McuMotSpd : 39|16@0+ (1,-20000) [-20000|45531] "rpm"  BMS,GW
 SG_ McuMotTemp : 55|8@0+ (1,-40) [-40|210] "℃"  GW
 SG_ MCU_F_DrvrMot1CrtSts_GB : 58|3@0+ (1,0) [1|4] ""  GW
 SG_ MCU_F_MCUTempAlarmLv1 : 59|1@0+ (1,0) [0|1] ""  GW
 SG_ MCU_F_MCUTempAlarmLv2 : 60|1@0+ (1,0) [0|1] ""  GW
 SG_ MCU_F_MotTempAlarmLv1 : 61|1@0+ (1,0) [0|1] ""  GW
 SG_ MCU_F_MotTempAlarmLv2 : 62|1@0+ (1,0) [0|1] ""  GW
 SG_ MCU_F_OverSpdAlarmLv1 : 63|1@0+ (1,0) [0|1] ""  GW
 SG_ MCU_F_OverSpdAlarmLv2 : 64|1@0+ (1,0) [0|1] ""  GW
 SG_ MCU_F_OverCurAlarmLv1 : 65|1@0+ (1,0) [0|1] ""  GW
 SG_ MCU_F_OverCurAlarmLv2 : 66|1@0+ (1,0) [0|1] ""  GW
 SG_ MCU_F_OverCurAlarmLv3 : 67|1@0+ (1,0) [0|1] ""  GW
 SG_ McuMotTor : 79|16@0+ (0.1,-2000) [-2000|4553.1] "Nm"  GW
 SG_ McuDcCur : 95|16@0+ (0.1,-1000) [-1000|1000] "A"  BMS,GW
 SG_ McuDcVolt : 111|16@0+ (0.1,0) [0|6000] "V"  BMS,GW

BO_ 1740 MCU_0x6CC: 8 MCU_B
 SG_ MCU_MotCode1 : 7|64@0+ (1,0) [0|16777215] ""  VCU,VCU5_0,VCU_BMS,GW

BO_ 1741 MCU_0x6CD: 8 MCU_B
 SG_ MCU_MotCode2 : 7|64@0+ (1,0) [0|16777215] ""  VCU,VCU5_0,VCU_BMS,GW

BO_ 1742 MCU_0x6CE: 8 MCU_B
 SG_ MCU_MotCode3 : 7|64@0+ (1,0) [0|16777215] ""  VCU,VCU5_0,VCU_BMS,GW

BO_ 1743 MCU_0x6CF: 8 MCU_B
 SG_ MCU_MotCode4 : 7|64@0+ (1,0) [0|16777215] ""  VCU,VCU5_0,VCU_BMS,GW

BO_ 512 VCU_0x200: 8 VCU
 SG_ VCUSpeedLimTypRq : 21|4@0+ (1,0) [0|15] ""  MCU_B,GW,MCU

BO_ 534 HDCU_MCU_0x216: 8 MCU_B
 SG_ MCU_216_CheckSum : 7|8@0+ (1,0) [0|255] ""  GW
 SG_ MCU_216_AliveCounter : 11|4@0+ (1,0) [0|14] ""  GW
 SG_ MCU_MOT_ActiveDamping_Flg : 12|1@0+ (1,0) [0|1] ""  VCU,VCU5_0,VCU_BMS,GW
 SG_ MCU_MOT_DIR_CMD : 15|2@0+ (1,0) [0|3] ""  VCU,VCU5_0,VCU_BMS,GW
 SG_ MCU_MOT_SPD : 23|16@0+ (1,-32768) [-32768|32767] "rpm"  BMS,VCU,VCU5_0,VCU_BMS,GW
 SG_ MCU_MOT_TOR : 39|16@0+ (0.1,-3276.8) [-3276.8|3276.7] "Nm"  BMS,VCU,VCU5_0,VCU_BMS,GW
 SG_ MCU_TOR_QUA_AFC : 50|2@0+ (1,0) [0|3] ""  VCU,VCU5_0,VCU_BMS,GW
 SG_ MCU_MOT_INIT : 51|1@0+ (1,0) [0|1] ""  BMS,VCU,VCU5_0,VCU_BMS,GW
 SG_ MCU_SPD_QUA_AFC : 54|2@0+ (1,0) [0|3] ""  BMS,VCU,VCU5_0,VCU_BMS,GW
 SG_ MCU_HV_CHECK_FLAG : 55|1@0+ (1,0) [0|1] ""  BMS,VCU,VCU5_0,VCU_BMS,GW
 SG_ MCU_HV_DISOBC_STA : 57|2@0+ (1,0) [0|3] ""  VCU,VCU5_0,VCU_BMS,GW
 SG_ MCU_LV_OFF_REQ_FLAG : 58|1@0+ (1,0) [0|1] ""  BMS,VCU,VCU5_0,VCU_BMS,GW
 SG_ MCU_MOT_STA : 60|2@0+ (1,0) [0|3] ""  BMS,VCU,VCU5_0,VCU_BMS,GW
 SG_ MCU_MOT_MODE : 62|2@0+ (1,0) [0|3] ""  VCU,VCU5_0,VCU_BMS,GW

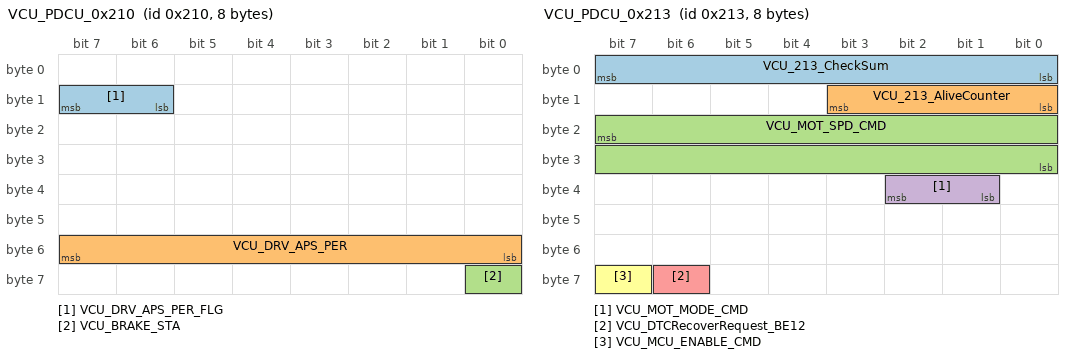
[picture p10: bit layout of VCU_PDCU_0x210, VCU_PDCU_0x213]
BO_ 528 VCU_PDCU_0x210: 8 VCU
 SG_ VCU_DRV_APS_PER_FLG : 15|2@0+ (1,0) [0|3] ""  GW,MCU
 SG_ VCU_DRV_APS_PER : 55|8@0+ (0.4,0) [0|100] "%"  GW,MCU
 SG_ VCU_BRAKE_STA : 56|1@0+ (1,0) [0|1] ""  MCU_B,BMS,LBMS,GW,MCU

BO_ 531 VCU_PDCU_0x213: 8 VCU
 SG_ VCU_213_CheckSum : 7|8@0+ (1,0) [0|255] ""  MCU_B,GW,MCU
 SG_ VCU_213_AliveCounter : 11|4@0+ (1,0) [0|14] ""  MCU_B,GW,MCU
 SG_ VCU_MOT_SPD_CMD : 23|16@0+ (1,-32768) [-32768|32767] "rpm"  MCU_B,GW,MCU
 SG_ VCU_MOT_MODE_CMD : 34|2@0+ (1,0) [0|3] ""  MCU_B,GW,MCU
 SG_ VCU_DTCRecoverRequest_BE12 : 62|1@0+ (1,0) [0|1] ""  MCU_B,BMS,GW,MCU
 SG_ VCU_MCU_ENABLE_CMD : 63|1@0+ (1,0) [0|1] ""  MCU_B,GW,MCU

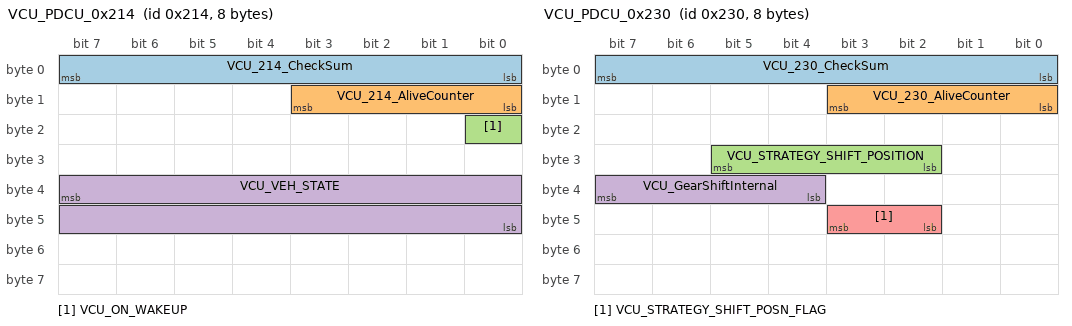
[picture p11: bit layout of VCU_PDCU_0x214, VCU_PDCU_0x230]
BO_ 532 VCU_PDCU_0x214: 8 VCU
 SG_ VCU_214_CheckSum : 7|8@0+ (1,0) [0|255] ""  MCU_B,GW,MCU
 SG_ VCU_214_AliveCounter : 11|4@0+ (1,0) [0|14] ""  MCU_B,GW,MCU
 SG_ VCU_ON_WAKEUP : 16|1@0+ (1,0) [0|1] ""  MCU_B,BMS,GW,MCU
 SG_ VCU_VEH_STATE : 39|16@0+ (1,0) [0|65535] ""  IPU,MCU_B,BMS,ECC,MCU_F,GW,MCU

BO_ 560 VCU_PDCU_0x230: 8 VCU
 SG_ VCU_230_CheckSum : 7|8@0+ (1,0) [0|255] ""  MCU_B,GW,MCU
 SG_ VCU_230_AliveCounter : 11|4@0+ (1,0) [0|14] ""  MCU_B,GW,MCU
 SG_ VCU_STRATEGY_SHIFT_POSITION : 29|4@0+ (1,0) [0|15] ""  MCU_B,BMS,GW,MCU
 SG_ VCU_GearShiftInternal : 39|4@0+ (1,0) [0|15] ""  MCU_B,GW,MCU
 SG_ VCU_STRATEGY_SHIFT_POSN_FLAG : 43|2@0+ (1,0) [0|3] ""  MCU_B,GW,MCU

BO_ 566 VCU_PDCU_0x236: 8 VCU
 SG_ VCU_ChrgDchaGunCnctnSts : 20|3@0+ (1,0) [0|7] ""  IPU,BMS,EVCC,GW,MCU
 SG_ VCU_S2SwtSts : 63|2@0+ (1,0) [0|3] ""  IPU,BMS,GW,MCU

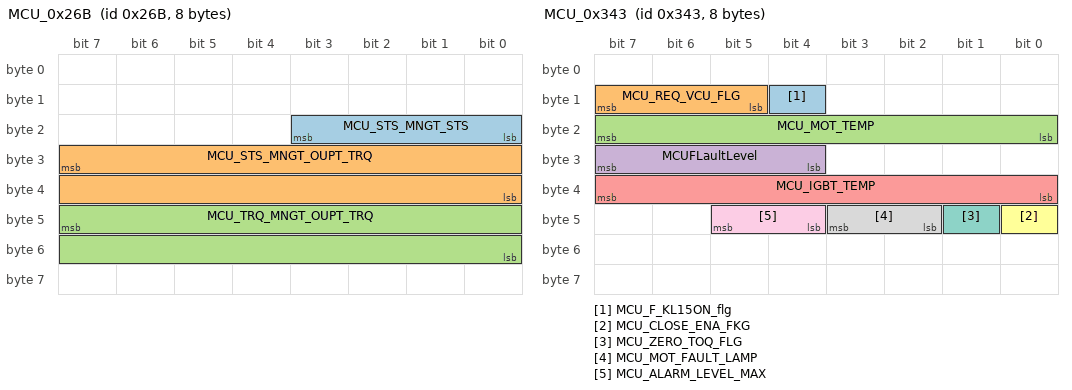
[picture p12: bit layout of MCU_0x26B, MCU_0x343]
BO_ 619 MCU_0x26B: 8 MCU_B
 SG_ MCU_STS_MNGT_STS : 19|4@0+ (1,0) [0|15] ""  VCU,VCU5_0,VCU_BMS,GW
 SG_ MCU_STS_MNGT_OUPT_TRQ : 31|16@0+ (0.1,-3276.8) [-3276.8|3276.7] "Nm"  VCU,VCU5_0,VCU_BMS,GW
 SG_ MCU_TRQ_MNGT_OUPT_TRQ : 47|16@0+ (0.1,-3276.8) [-3276.8|3276.7] "Nm"  VCU,VCU5_0,VCU_BMS,GW

BO_ 834 VCU_0x342: 8 VCU
 SG_ VCU_ADA_SLIDE_REQ_FLG : 14|1@0+ (1,0) [0|1] ""  GW,MCU
 SG_ VCU_ENERY_CONSUM_AVE : 55|16@0+ (0.0001,0) [0|6.5535] ""  GW,MCU

BO_ 835 MCU_0x343: 8 MCU_B
 SG_ MCU_F_KL15ON_flg : 12|1@0+ (1,0) [0|1] ""  GW
 SG_ MCU_REQ_VCU_FLG : 15|3@0+ (1,0) [0|7] ""  VCU,VCU5_0,VCU_BMS,GW
 SG_ MCU_MOT_TEMP : 23|8@0+ (1,-48) [-48|206] "℃"  ECC,VCU,VCU5_0,VCU_BMS,GW
 SG_ MCUFLaultLevel : 31|4@0+ (1,0) [0|15] ""  VCU,VCU5_0,VCU_BMS,GW
 SG_ MCU_IGBT_TEMP : 39|8@0+ (1,-48) [-48|206] "℃"  ECC,VCU,VCU5_0,VCU_BMS,GW
 SG_ MCU_CLOSE_ENA_FKG : 40|1@0+ (1,0) [0|1] ""  VCU,VCU5_0,VCU_BMS,GW
 SG_ MCU_ZERO_TOQ_FLG : 41|1@0+ (1,0) [0|1] ""  VCU,VCU5_0,VCU_BMS,GW
 SG_ MCU_MOT_FAULT_LAMP : 43|2@0+ (1,0) [0|3] ""  VCU,VCU5_0,VCU_BMS,GW
 SG_ MCU_ALARM_LEVEL_MAX : 45|2@0+ (1,0) [0|3] ""  VCU,VCU5_0,VCU_BMS,GW

BO_ 837 MCU_0x345: 8 MCU_B
 SG_ MCU_DC_SEN_DRIFT : 18|1@0+ (1,0) [0|1] ""  VCU,VCU5_0,VCU_BMS,GW
 SG_ MCU_CUR_SAMP_CIR_U : 19|1@0+ (1,0) [0|1] ""  VCU,VCU5_0,VCU_BMS,GW
 SG_ MCU_CUR_SAMP_CIR_V : 20|1@0+ (1,0) [0|1] ""  VCU,VCU5_0,VCU_BMS,GW
 SG_ MCU_CUR_SAMP_CIR_W : 21|1@0+ (1,0) [0|1] ""  VCU,VCU5_0,VCU_BMS,GW
 SG_ MCU_DC_SAMP_CUR : 22|1@0+ (1,0) [0|1] ""  VCU,VCU5_0,VCU_BMS,GW
 SG_ MCU_3PHASE_CUR_CHE_FAULT : 23|1@0+ (1,0) [0|1] ""  VCU,VCU5_0,VCU_BMS,GW
 SG_ MCU_BUSBAR_VOLT_LOW : 24|1@0+ (1,0) [0|1] ""  VCU,VCU5_0,VCU_BMS,GW
 SG_ MCU_BUSBAR_VOLT_HIGH : 25|1@0+ (1,0) [0|1] ""  VCU,VCU5_0,VCU_BMS,GW
 SG_ MCU_BUS_VOLIT_SAMP_FAULT : 27|1@0+ (1,0) [0|1] ""  VCU,VCU5_0,VCU_BMS,GW
 SG_ MCU_OVER_SPD_FAULT : 28|1@0+ (1,0) [0|1] ""  BMS,VCU,VCU5_0,VCU_BMS,GW
 SG_ MCU_IGBT_TEMP_OVER_U : 29|1@0+ (1,0) [0|1] ""  BMS,VCU,VCU5_0,VCU_BMS,GW
 SG_ MCU_IGBT_TEMP_OVER_V : 30|1@0+ (1,0) [0|1] ""  BMS,VCU,VCU5_0,VCU_BMS,GW
 SG_ MCU_IGBT_TEMP_OVER_W : 31|1@0+ (1,0) [0|1] ""  BMS,VCU,VCU5_0,VCU_BMS,GW
 SG_ MCU_IGBT_TEMP_CHECK_CUR_U : 32|1@0+ (1,0) [0|1] ""  VCU,VCU5_0,VCU_BMS,GW
 SG_ MCU_IGBT_TEMP_CHECK_CUR_V : 33|1@0+ (1,0) [0|1] ""  VCU,VCU5_0,VCU_BMS,GW
 SG_ MCU_IGBT_TEMP_CHECK_CUR_W : 34|1@0+ (1,0) [0|1] ""  VCU,VCU5_0,VCU_BMS,GW
 SG_ MCU_MOTOR_TEMP_OVER : 35|1@0+ (1,0) [0|1] ""  BMS,VCU,VCU5_0,VCU_BMS,GW
 SG_ MCU_MOT_TEMP_CHECK_CUR : 36|1@0+ (1,0) [0|1] ""  VCU,VCU5_0,VCU_BMS,GW
 SG_ MCU_MCU_TEMP_OVER : 37|1@0+ (1,0) [0|1] ""  BMS,VCU,VCU5_0,VCU_BMS,GW
 SG_ MCUPowOnIniFlt : 38|1@0+ (1,0) [0|1] ""  VCU,VCU5_0,VCU_BMS,GW
 SG_ MCU_BATT_VOLT_LOW : 39|1@0+ (1,0) [0|1] ""  VCU,VCU5_0,VCU_BMS,GW
 SG_ MCU_BATT_VOLT_HIGH : 40|1@0+ (1,0) [0|1] ""  VCU,VCU5_0,VCU_BMS,GW
 SG_ MCU_F_PosZeroErr : 41|1@0+ (1,0) [0|1] ""  GW
 SG_ MCU_HW_CUR_HIGH_W : 44|1@0+ (1,0) [0|1] ""  VCU,VCU5_0,VCU_BMS,GW
 SG_ MCU_FEED_TOR_ORDER_CHE_FAULT : 46|1@0+ (1,0) [0|1] ""  VCU,VCU5_0,VCU_BMS,GW
 SG_ MCU_HL_VOLT_INTERLOCK_FAULT : 50|1@0+ (1,0) [0|1] ""  VCU,VCU5_0,VCU_BMS,GW
 SG_ MCU_SW_CUR_HIGH : 51|1@0+ (1,0) [0|1] ""  VCU,VCU5_0,VCU_BMS,GW
 SG_ MCU_HW_CUR_HIGH_U : 53|1@0+ (1,0) [0|1] ""  VCU,VCU5_0,VCU_BMS,GW
 SG_ MCU_HW_CUR_HIGH_V : 55|1@0+ (1,0) [0|1] ""  VCU,VCU5_0,VCU_BMS,GW
 SG_ MCU_EAS_HL_INTERLOCK_FAULT : 56|1@0+ (1,0) [0|1] ""  VCU,VCU5_0,VCU_BMS,GW
 SG_ MCU_PTC_HL_INTERLOCK_FAULT : 57|1@0+ (1,0) [0|1] ""  VCU,VCU5_0,VCU_BMS,GW
 SG_ MCU_BATT_HL_INTERLOCK_FAULT : 58|1@0+ (1,0) [0|1] ""  VCU,VCU5_0,VCU_BMS,GW
 SG_ MCU_MC_HL_INTERLOCK_FAULT : 59|1@0+ (1,0) [0|1] ""  VCU,VCU5_0,VCU_BMS,GW
 SG_ MCU_QC_HL_INTERLOCK_FAULT : 60|1@0+ (1,0) [0|1] ""  VCU,VCU5_0,VCU_BMS,GW

BO_ 838 MCU_0x346: 8 MCU_B
 SG_ MCU_COM_VCU_LOSE : 4|1@0+ (1,0) [0|1] ""  VCU,VCU5_0,VCU_BMS,GW
 SG_ McuActDchFlt : 7|1@0+ (1,0) [0|1] ""  VCU,VCU5_0,VCU_BMS,GW
 SG_ McuSafStaCheFlt : 8|1@0+ (1,0) [0|1] ""  VCU,VCU5_0,VCU_BMS,GW
 SG_ McuDcCurHighFlt : 9|1@0+ (1,0) [0|1] ""  VCU,VCU5_0,VCU_BMS,GW
 SG_ Mot3PhaLoseFlt : 10|1@0+ (1,0) [0|1] ""  VCU,VCU5_0,VCU_BMS,GW
 SG_ McuMstChipFlt : 11|1@0+ (1,0) [0|1] ""  VCU,VCU5_0,VCU_BMS,GW
 SG_ IGBT3PhaseTChecFlt : 12|1@0+ (1,0) [0|1] ""  VCU,VCU5_0,VCU_BMS,GW
 SG_ McuIntComFlt : 13|1@0+ (1,0) [0|1] ""  VCU,VCU5_0,VCU_BMS,GW
 SG_ IntTorChecFlt : 14|1@0+ (1,0) [0|1] ""  VCU,VCU5_0,VCU_BMS,GW
 SG_ RunModFlt : 15|1@0+ (1,0) [0|1] ""  VCU,VCU5_0,VCU_BMS,GW
 SG_ MCU_IGBI_UPPR_BRDG_FLT_U : 16|1@0+ (1,0) [0|1] ""  VCU,VCU5_0,VCU_BMS,GW
 SG_ MCU_IGBI_LOWR_BRDG_FLT_U : 17|1@0+ (1,0) [0|1] ""  VCU,VCU5_0,VCU_BMS,GW
 SG_ MCU_IGBI_UPPR_BRDG_FLT_V : 18|1@0+ (1,0) [0|1] ""  VCU,VCU5_0,VCU_BMS,GW
 SG_ MCU_IGBI_LOWR_BRDG_FLT_V : 19|1@0+ (1,0) [0|1] ""  VCU,VCU5_0,VCU_BMS,GW
 SG_ MCU_IGBI_UPPR_BRDG_FLT_W : 20|1@0+ (1,0) [0|1] ""  VCU,VCU5_0,VCU_BMS,GW
 SG_ MCU_IGBI_LOWR_BRDG_FLT_W : 21|1@0+ (1,0) [0|1] ""  VCU,VCU5_0,VCU_BMS,GW
 SG_ MCU_WAKE_SIG_FLT : 23|1@0+ (1,0) [0|1] ""  VCU,VCU5_0,VCU_BMS,GW
 SG_ McuSwCurHighU : 27|1@0+ (1,0) [0|1] ""  VCU,VCU5_0,VCU_BMS,GW
 SG_ McuSwCurHighV : 28|1@0+ (1,0) [0|1] ""  VCU,VCU5_0,VCU_BMS,GW
 SG_ McuSwCurHighW : 29|1@0+ (1,0) [0|1] ""  VCU,VCU5_0,VCU_BMS,GW
 SG_ McuBattModFlt : 30|1@0+ (1,0) [0|1] ""  VCU,VCU5_0,VCU_BMS,GW
 SG_ McuConTempCheckCurFlt : 31|1@0+ (1,0) [0|1] ""  VCU,VCU5_0,VCU_BMS,GW
 SG_ McuPosCheckCurFlt : 32|1@0+ (1,0) [0|1] ""  VCU,VCU5_0,VCU_BMS,GW
 SG_ MCU_E2E_ERR : 45|1@0+ (1,0) [0|1] ""  VCU,VCU5_0,VCU_BMS,GW

BO_ 855 VCU_PDCU_0x357: 8 VCU
 SG_ VCU_OTAClsChrgCmd : 15|1@0+ (1,0) [0|1] ""  MCU_B,BMS,GW,MCU

BO_ 295 VCU_PDCU_0x127: 64 VCU
 SG_ McuApsPer : 31|8@0+ (0.4,0) [0|100] "%"  MCU_B,GW,MCU
 SG_ McuApsPerFlag : 47|2@0+ (1,0) [0|3] ""  MCU_B,GW,MCU
 SG_ McuMotDampgFobdFlg : 41|1@0+ (1,0) [0|1] ""  MCU_B,GW,MCU
 SG_ McuMotTorCmd : 40|17@0+ (0.02,-1310.7) [-1310.7|1310.7] "Nm"  MCU_B,GW,MCU
 SG_ DrvTorReq : 87|20@0+ (0.02,-10000) [-10000|10000] "Nm"  MCU_B,GW,MCU
 SG_ DrvTorReqFlg : 97|2@0+ (1,0) [0|3] ""  MCU_B,GW,MCU

BO_ 1387 BMS_0x56B: 64 BMS
 SG_ BMS_CELL_TEMP_MIN : 87|8@0+ (1,-48) [-48|207] "℃"  MCU_B,ECC,VCU,HDCU,VCU5_0,GW,MCU

BO_ 513 BMS_0x201: 64 BMS
 SG_ BMS_OBC_VOLT_OUT_CMD : 23|16@0+ (0.02,0) [0|1310.7] "V"  IPU,VCU,HDCU,VCU5_0,GW,MCU
 SG_ BMS_OBC_CUR_RQ : 39|16@0+ (0.02,0) [0|1310.7] "A"  IPU,VCU,HDCU,VCU5_0,GW,MCU
 SG_ BMS_OBC_CMD : 117|3@0+ (1,0) [0|7] ""  IPU,VCU,EVCC,HDCU,VCU5_0,GW,MCU
 SG_ BMS_S2_SW_CMD : 119|2@0+ (1,0) [0|3] ""  IPU,VCU,HDCU,VCU5_0,GW,MCU
 SG_ BMS_S1_SWT_CMD : 211|2@0+ (1,0) [0|3] ""  IPU,VCU,HDCU,VCU5_0,GW,MCU
 SG_ BMS_VEH_MODE : 223|3@0+ (1,0) [0|7] ""  IPU,VCU,EVCC,HDCU,VCU5_0,GW,MCU

BO_ 535 BMS_0x217: 64 BMS
 SG_ BMS_DISOBC_MAX_PWR : 39|16@0+ (0.01,0) [0|655.35] "kW"  IPU,VCU,MCU_F,HDCU,VCU5_0,GW,MCU
 SG_ BMS_BATT_SOC : 55|7@0+ (1,0) [0|100] "%"  MCU_B,VCU,MCU_F,HDCU,VCU5_0,GW,MCU
 SG_ BMS_SELF_CHECK_COUNTER : 63|2@0+ (1,0) [0|3] ""  MCU_B,VCU,HDCU,VCU5_0,GW,MCU
 SG_ BMS_BATTSocReal : 71|14@0+ (0.01,0) [0|100] "%"  MCU_B,VCU,MCU_F,HDCU,VCU5_0,GW,MCU
 SG_ BMS_PwrBattRmngCpSOCHiAccuracy : 183|16@0+ (0.01,0) [0|100] "%"  MCU_B,ECC,VCU,MCU_F,HDCU,VCU5_0,GW,MCU

BO_ 536 BMS_0x218: 32 BMS
 SG_ BMS_BATT_CUR : 87|16@0+ (0.04,-1000) [-1000|1621.4] "A"  MCU_B,ECC,VCU,HDCU,VCU5_0,GW,MCU

BO_ 276 VCU_0x114: 32 VCU
 SG_ VCUVehFaultLevel : 11|4@0+ (1,0) [0|15] ""  MCU_B,BMS,GW,MCU
 SG_ AccelModCoeDex : 30|7@0+ (1,0) [0|100] ""  MCU_B,GW,MCU
 SG_ WheelPreTor : 23|9@0+ (1,-200) [-200|200] "Nm"  MCU_B,GW,MCU
 SG_ BrakTorDex : 39|14@0+ (0.1,0) [0|1000] ""  MCU_B,GW,MCU
 SG_ WormEnaFlg : 56|1@0+ (1,0) [0|1] ""  MCU_B,GW,MCU
 SG_ DrivSysActFlg : 57|1@0+ (1,0) [0|1] ""  MCU_B,GW,MCU
 SG_ ABSActFlg : 58|1@0+ (1,0) [0|1] ""  MCU_B,GW,MCU
 SG_ CRBSActFlg : 59|1@0+ (1,0) [0|1] ""  MCU_B,GW,MCU
 SG_ WormTorDex : 41|14@0+ (0.1,0) [0|1000] ""  MCU_B,GW,MCU
 SG_ TorFilSta : 84|5@0+ (1,0) [0|30] ""  MCU_B,GW,MCU
 SG_ ACCActFlg : 85|1@0+ (1,0) [0|1] ""  MCU_B,GW,MCU
 SG_ TorEnaFlg : 86|1@0+ (1,0) [0|1] ""  MCU_B,GW,MCU
 SG_ BmsEngRecForbFlg : 87|1@0+ (1,0) [0|1] ""  MCU_B,GW,MCU
 SG_ WheelHubMod : 88|1@0+ (1,0) [0|1] ""  MCU_B,GW,MCU
 SG_ EneRecGraDex : 95|7@0+ (1,0) [0|100] ""  MCU_B,GW,MCU
 SG_ FronWheTorRq : 103|16@0+ (1,-32768) [-32768|32767] ""  MCU_B,GW,MCU
 SG_ TransRat : 119|15@0+ (0.001,0) [0|20] ""  MCU_B,GW,MCU
 SG_ TransEffic : 151|11@0+ (0.001,0) [0|2] ""  MCU_B,GW,MCU
 SG_ BrakPedTra : 167|15@0+ (0.01,-20) [-20|200] "mm"  MCU_B,GW,MCU
 SG_ SpeedLimFlg : 179|4@0+ (1,0) [0|10] ""  MCU_B,GW,MCU
 SG_ DrivAntiSliSwt : 186|1@0+ (1,0) [0|1] ""  MCU_B,GW,MCU
 SG_ RecAntiSliSwt : 187|1@0+ (1,0) [0|1] ""  MCU_B,GW,MCU
 SG_ AbsArbSwt : 188|1@0+ (1,0) [0|1] ""  MCU_B,GW,MCU
 SG_ TcsArbSwt : 189|1@0+ (1,0) [0|1] ""  MCU_B,GW,MCU
 SG_ DtcArbSwt : 190|1@0+ (1,0) [0|1] ""  MCU_B,GW,MCU

BO_ 277 MCU_PDCU_0x115: 16 MCU_B
 SG_ FroMotTorRisGrad : 23|17@0+ (1,-50000) [-50000|50000] ""  VCU,VCU5_0,VCU_BMS,GW
 SG_ McuAlrmLampFS : 49|1@0+ (1,0) [0|1] ""  GW
 SG_ McuMotArbTor : 38|17@0+ (0.02,-1310.7) [-1310.7|1310.7] ""  GW
 SG_ FrOnEspTorArbSta : 63|4@0+ (1,0) [0|10] ""  VCU,VCU5_0,VCU_BMS,GW
 SG_ McuMotWheelTor : 111|14@0+ (1,-6000) [-6000|10000] ""  GW
 SG_ McuMotWheelTorValid : 113|2@0+ (1,0) [0|3] ""  GW
 SG_ RatRedDex : 123|4@0+ (0.1,0) [0|1] ""  GW

BO_ 533 MCU_0x215: 16 MCU_B
 SG_ MCU_F_DCurrent_Cmd : 7|16@0+ (0.1,-3276.8) [-3276.8|3276.7] ""  GW
 SG_ MCU_F_DCurrent_Fb : 23|16@0+ (0.1,-3276.8) [-3276.8|3276.7] ""  GW
 SG_ MCU_F_QCurrent_Cmd : 39|16@0+ (0.1,-3276.8) [-3276.8|3276.7] ""  GW
 SG_ MCU_F_QCurrent_Fb : 55|16@0+ (0.1,-3276.8) [-3276.8|3276.7] ""  GW
 SG_ MCU_F_Volt_Percent : 79|10@0+ (0.01,0) [0|10] ""  GW
 SG_ MCU_F_Ang_Delta : 84|13@0+ (1,-4095) [-4095|4095] ""  GW
 SG_ MCU_F_MotSpdFilteredLow : 103|16@0+ (1,-20000) [-20000|20000] ""  GW
 SG_ MCU_F_F_CrtTq_act : 119|16@0+ (0.1,-3276.8) [-3276.8|3276.7] ""  GW

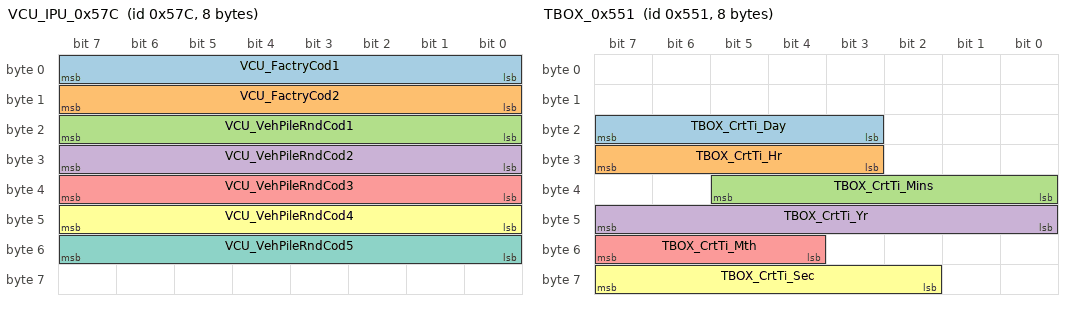
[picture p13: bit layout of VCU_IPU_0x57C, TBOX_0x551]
BO_ 1404 VCU_IPU_0x57C: 8 IPU
 SG_ VCU_FactryCod1 : 7|8@0+ (1,0) [0|255] ""  HDCU,GW
 SG_ VCU_FactryCod2 : 15|8@0+ (1,0) [0|255] ""  HDCU,GW
 SG_ VCU_VehPileRndCod1 : 23|8@0+ (1,0) [0|255] ""  HDCU,GW
 SG_ VCU_VehPileRndCod2 : 31|8@0+ (1,0) [0|255] ""  HDCU,GW
 SG_ VCU_VehPileRndCod3 : 39|8@0+ (1,0) [0|255] ""  HDCU,GW
 SG_ VCU_VehPileRndCod4 : 47|8@0+ (1,0) [0|255] ""  HDCU,GW
 SG_ VCU_VehPileRndCod5 : 55|8@0+ (1,0) [0|255] ""  HDCU,GW

BO_ 1268 TBOX_0x4F4: 32 GW
 SG_ OTAHVPwrMod : 92|3@0+ (1,0) [0|7] ""  IPU,MCU_B,BMS,VCU,MCU_F,HDCU,VCU5_0,VCU_BMS,MCU

BO_ 753 BCM_0x2F1: 64 GW
 SG_ TrOpenStsSwt : 14|3@0+ (1,0) [0|7] ""  MCU_B,BMS,ECC,VCU,HDCU,VCU5_0,VCU_BMS,MCU
 SG_ DrvrDoorOpenStsSwt : 35|2@0+ (1,0) [0|3] ""  MCU_B,BMS,ECC,VCU,HDCU,VCU5_0,VCU_BMS,MCU
 SG_ PassDoorOpenStsSwt : 37|2@0+ (1,0) [0|3] ""  MCU_B,BMS,ECC,VCU,HDCU,VCU5_0,VCU_BMS,MCU
 SG_ ReLeDoorOpenStsSwt : 39|2@0+ (1,0) [0|3] ""  MCU_B,BMS,ECC,VCU,HDCU,VCU5_0,VCU_BMS,MCU
 SG_ ReRiDoorOpenStsSwt : 41|2@0+ (1,0) [0|3] ""  MCU_B,BMS,ECC,VCU,HDCU,VCU5_0,VCU_BMS,MCU
 SG_ HoodLidOpenStsSwt : 43|2@0+ (1,0) [0|3] ""  MCU_B,BMS,VCU,HDCU,VCU5_0,VCU_BMS,MCU
 SG_ BdcVehMod : 362|3@0+ (1,0) [0|7] ""  MCU_B,ECC,VCU,HDCU,VCU5_0,VCU_BMS,MCU

BO_ 1361 TBOX_0x551: 8 GW
 SG_ TBOX_CrtTi_Day : 23|5@0+ (1,1) [1|31] "day"  IPU,MCU_B,BMS,ECC,VCU,EVCC,MCU_F,HDCU,LBMS,VCU5_0,VCU_BMS,MCU
 SG_ TBOX_CrtTi_Hr : 31|5@0+ (1,0) [0|23] "hour"  IPU,MCU_B,BMS,ECC,VCU,EVCC,MCU_F,HDCU,LBMS,VCU5_0,VCU_BMS,MCU
 SG_ TBOX_CrtTi_Mins : 37|6@0+ (1,0) [0|59] "mintue"  IPU,MCU_B,BMS,ECC,VCU,EVCC,MCU_F,HDCU,LBMS,VCU5_0,VCU_BMS,MCU
 SG_ TBOX_CrtTi_Yr : 47|8@0+ (1,2015) [2015|2270] "year"  IPU,MCU_B,BMS,ECC,VCU,EVCC,MCU_F,HDCU,LBMS,VCU5_0,VCU_BMS,MCU
 SG_ TBOX_CrtTi_Mth : 55|4@0+ (1,1) [1|12] "month"  IPU,MCU_B,BMS,ECC,VCU,EVCC,MCU_F,HDCU,LBMS,VCU5_0,VCU_BMS,MCU
 SG_ TBOX_CrtTi_Sec : 63|6@0+ (1,0) [0|59] "second"  IPU,MCU_B,BMS,ECC,VCU,EVCC,MCU_F,HDCU,LBMS,VCU5_0,VCU_BMS,MCU

BO_ 389 PBM_0x185: 48 GW
 SG_ FrntRiWhlSpd : 22|15@0+ (0.0625,0) [0|300] "km/h"  MCU_F,HDCU,MCU
 SG_ FrntRiWhlSpdVld : 33|2@0+ (1,0) [0|3] ""  MCU_F,HDCU,MCU
 SG_ FrntLeWhlSpd : 46|15@0+ (0.0625,0) [0|300] "km/h"  MCU_F,HDCU,MCU
 SG_ FrntLeWhlSpdVld : 57|2@0+ (1,0) [0|3] ""  MCU_F,HDCU,MCU
 SG_ ReRiWhlSpd : 86|15@0+ (0.0625,0) [0|300] "km/h"  MCU_F,HDCU,MCU
 SG_ ReRiWhlSpdVld : 97|2@0+ (1,0) [0|3] ""  MCU_F,HDCU,MCU
 SG_ ReLeWhlSpd : 110|15@0+ (0.0625,0) [0|300] "km/h"  MCU_F,HDCU,MCU
 SG_ ReLeWhlSpdVld : 121|2@0+ (1,0) [0|3] ""  MCU_F,HDCU,MCU
 SG_ VehStop : 213|2@0+ (1,0) [0|3] ""  ECC,MCU_F,VCU5_0,MCU
 SG_ VehSpdVld : 215|2@0+ (1,0) [0|3] ""  IPU,MCU_B,BMS,ECC,MCU_F,HDCU,LBMS,VCU5_0,VCU_BMS,MCU
 SG_ VehSpd : 223|16@0+ (0.1,0) [0|300] "km/h"  IPU,MCU_B,BMS,ECC,VCU,MCU_F,HDCU,LBMS,VCU5_0,VCU_BMS,MCU

BO_ 433 PEPS_0x1B1: 64 GW
 SG_ PwrMod : 81|2@0+ (1,0) [0|3] ""  MCU_B,ECC,VCU,MCU_F,HDCU,LBMS,VCU5_0,VCU_BMS,MCU
 SG_ PwrModVld : 83|2@0+ (1,0) [0|3] ""  MCU_B,ECC,MCU_F,HDCU,LBMS,VCU5_0,MCU

BO_ 281 EGSM_0x119: 8 GW
 SG_ EGSMFltSts : 39|4@0+ (1,0) [0|15] ""  MCU_B,VCU,HDCU,VCU5_0,VCU_BMS,MCU
 SG_ EGSMGearLvrCrtPosnInfo : 50|3@0+ (1,0) [0|7] ""  MCU_B,VCU,HDCU,VCU5_0,VCU_BMS,MCU

BO_ 304 EMS_0x130: 48 HDCU
 SG_ ActTqVld : 25|2@0+ (1,0) [0|3] ""  IPU,BMS,MCU_F,MCU
 SG_ EmsCalcdLoadVal : 119|8@0+ (0.39215686,0) [0|99.9999993] "%"  IPU,BMS,MCU_F,MCU
 SG_ ActEngSpdUnfil : 151|16@0+ (1,0) [0|7000] "rpm"  IPU,BMS,MCU_F,MCU
 SG_ EmsAbsltAccrPedlPosn : 271|8@0+ (0.39215686,0) [0|99.9999993] "%"  IPU,MCU

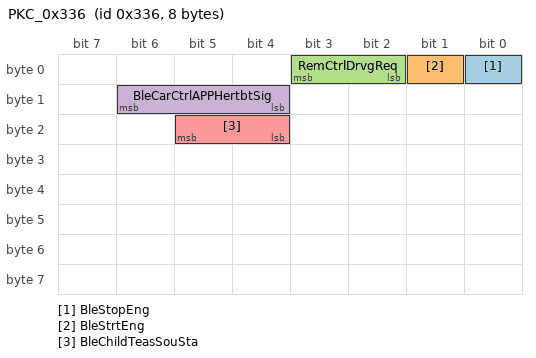
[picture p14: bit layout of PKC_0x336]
BO_ 822 PKC_0x336: 8 GW
 SG_ BleStopEng : 0|1@0+ (1,0) [0|1] ""  MCU_B,VCU,MCU_F,HDCU,VCU5_0,VCU_BMS,MCU
 SG_ BleStrtEng : 1|1@0+ (1,0) [0|1] ""  MCU_B,VCU,MCU_F,HDCU,VCU5_0,VCU_BMS,MCU
 SG_ RemCtrlDrvgReq : 3|2@0+ (1,0) [0|3] ""  MCU_B,VCU,HDCU,VCU5_0,VCU_BMS,MCU
 SG_ BleCarCtrlAPPHertbtSig : 14|3@0+ (1,0) [0|7] ""  MCU_B,VCU,HDCU,VCU5_0,VCU_BMS,MCU
 SG_ BleChildTeasSouSta : 21|2@0+ (1,0) [0|3] ""  MCU_B,VCU,HDCU,VCU5_0,VCU_BMS,MCU

BO_ 305 EMS_0x131: 24 HDCU
 SG_ EmsEngWrmUpAch : 84|1@0+ (1,0) [0|1] ""  IPU,BMS,MCU_F,MCU
 SG_ EmsCooltT : 151|8@0+ (1,-40) [-40|215] "deg.C"  IPU,MCU_F,MCU

BO_ 998 EMS_0x3E6: 48 HDCU
 SG_ EmsDrvgCyc : 140|1@0+ (1,0) [0|1] ""  IPU,BMS,MCU_F,MCU

CM_ BO_ 1025 "NMsignal";
CM_ SG_ 1025 BMSFlNodeId "Node Id=01";
CM_ SG_ 1025 BMSFlPni "Partial Network Information Bit";
CM_ SG_ 1025 BMSFlAwb "Active Wakeup Bit";
CM_ SG_ 1025 BMSFlRmr "Repeat Message Request Bit";
CM_ SG_ 1025 BMSFlWus "Wake Up Source of BMS";
CM_ SG_ 1025 BMSFlNmSts "BMS Nework Management State";
CM_ BO_ 1046 "NMsignal";
CM_ SG_ 1046 GWEvbusFlNodeId "Node Id=16";
CM_ SG_ 1046 GWEvbusFlPni "Partial Network Information Bit";
CM_ SG_ 1046 GWEvbusFlAwb "Active Wakeup Bit";
CM_ SG_ 1046 GWEvbusFlRmr "Repeat Message Request Bit";
CM_ SG_ 1046 GWEvbusFlWus "Wake Up Source of GWEvbus";
CM_ SG_ 1046 GWEvbusFlNmSts "GWEvbus Nework Management State";
CM_ BO_ 1026 "NMsignal";
CM_ SG_ 1026 MCUFlNodeId "Node Id=02";
CM_ SG_ 1026 MCUFlPni "Partial Network Information Bit";
CM_ SG_ 1026 MCUFlAwb "Active Wakeup Bit";
CM_ SG_ 1026 MCUFlRmr "Repeat Message Request Bit";
CM_ SG_ 1026 MCUFlWus "Wake Up Source of MCU";
CM_ SG_ 1026 MCUFlNmSts "MCU Nework Management State";
CM_ BO_ 1059 "NMsignal";
CM_ SG_ 1059 ACFlNodeId "Node Id=23";
CM_ SG_ 1059 ACFlPni "Partial Network Information Bit";
CM_ SG_ 1059 ACFlAwb "Active Wakeup Bit";
CM_ SG_ 1059 ACFlRmr "Repeat Message Request Bit";
CM_ SG_ 1059 ACFlWus "Wake Up Source of AC";
CM_ SG_ 1059 ACFlNmSts "AC Nework Management State";
CM_ BO_ 1141 "NMsignal";
CM_ SG_ 1141 LBMSFlNodeId "Node Id=75";
CM_ SG_ 1141 LBMSFlPni "Partial Network Information Bit";
CM_ SG_ 1141 LBMSFlAwb "Active Wakeup Bit";
CM_ SG_ 1141 LBMSFlRmr "Repeat Message Request Bit";
CM_ SG_ 1141 LBMSFlWus "Wake Up Source of LBMS";
CM_ SG_ 1141 LBMSFlNmSts "LBMS Nework Management State";
CM_ SG_ 521 MCU_KL30Vol "MCU_Kl30电压值";
CM_ SG_ 521 MCU_F_MCUPowerOffCmd "前MCU功能请求标志位";
CM_ SG_ 521 MCU_F_MCUInitComp_flg "前MCU底层初始化完成标志位";
CM_ SG_ 521 MCU_DC_CUR "直流母线电流";
CM_ SG_ 521 MCU_PHASE_CUR "驱动电机相电流（有效值）";
CM_ SG_ 521 MCU_DC_VOLT "直流母线电压";
CM_ SG_ 296 dmc_dTcsDbgSignal1_M1 "dTCS激活状态";
CM_ SG_ 296 dmc_TcsDbgSiqnal2_M1 "dtcs激活的时间";
CM_ SG_ 296 dmc_dTcsDbgSignal3_M1 "dtcs激活的目标转速门槛";
CM_ SG_ 296 dmc_dTcsDbgSignal4_M1 "dtcs请求模式";
CM_ SG_ 296 dmc_dTcsDbgSignal5_M1 "dtcs滑移状态";
CM_ SG_ 296 DmcFrtDTCSOperaMode "dTCS控制状态";
CM_ SG_ 296 dmc_dTcsDbgSignal6_M1 "dtcs的P_term";
CM_ SG_ 296 dmc_dTcsDbgSignal7_M1 "dtcs的I_term";
CM_ SG_ 296 dmc_dTcsDbgSignal8_M1 "dtcs的D_term";
CM_ SG_ 296 dmc_dTcsDbgSignal9_M1 "dtcs的delta_I_term";
CM_ SG_ 296 dmc_drcsDbgSignal10_M1 "dtcs的noslip_time";
CM_ SG_ 296 dmc_drcsDbgSignal11_M1 "dtcs的制动补偿力矩";
CM_ SG_ 296 dmc_drcsDbgSignal12_M1 "dtcs的驾驶员需求力矩";
CM_ SG_ 296 DmcFrtDTCSTargTorq "dTCS控制的目标扭矩";
CM_ SG_ 1152 IPUCPAmp "CP幅值IPU";
CM_ SG_ 1152 OBC_DCCrt "充电机DC端电流";
CM_ SG_ 1152 OBC_DCVolt "充电机DC端电压";
CM_ SG_ 1152 IPUCPDutyRat "CP占空比IPU";
CM_ SG_ 1152 IPUWakupsou "IPU唤醒源";
CM_ SG_ 1152 IPUCPDir "CP方向IPU";
CM_ SG_ 1152 IPUHeatReqFlg "IPU请求加热标志位";
CM_ SG_ 1152 IPUCCR "CC电阻阻值IPU";
CM_ SG_ 1152 IPUCPFrq "CP频率IPU";
CM_ SG_ 1304 DcdcMilReq "DCDC的MIL灯请求";
CM_ SG_ 1304 DCDC_OutpCrt "DCDC输出端电流";
CM_ SG_ 1304 DCDC_InpVolt "DCDC输入端电压";
CM_ SG_ 1304 DCDC_InpCrt "DCDC输入端电流";
CM_ SG_ 1304 DCDC_OutpVolt "DCDC输出端电压";
CM_ SG_ 1313 DCDC_InpOverVoltSwFlt "DCDC输入软件过压_P197717_E00";
CM_ SG_ 1313 DCDC_InpUnderVoltFlt "DCDC输入欠压_P199F16_E00";
CM_ SG_ 1313 DCDC_LVOutpOverVoltFlt "DCDC低压输出过压_P19A017_E00";
CM_ SG_ 1313 DCDC_LVOutpUnderVoltFlt "DCDC低压输出欠压_P19A016_E00";
CM_ SG_ 1313 PDU_BusoffFlt "busoff整车CAN总线断开_U313487_E00";
CM_ SG_ 1313 DCDC_OverTTurnDwnLoadFlt "温度高DCDC降载_P197598_E00";
CM_ SG_ 1313 IPU_ComCheckErr "PDU通信校验故障_P19B808_E00";
CM_ SG_ 1313 DCDC_InpCurOverSwFlt "DCDC输入软件过流_P197719_E00";
CM_ SG_ 1313 DCDC_OverTShutDwnFlt "温度高DCDC关机_P199E98_E00";
CM_ SG_ 1313 DCDC_StsAlrmFlt "DCDC状态报警故障_P19AC01_E00";
CM_ SG_ 1313 DCDC_CrtStsGB "DCDC当前状态（国标）";
CM_ SG_ 1313 DCDC_LVOutpOverCurrFlt "DCDC输出过流故障_P19A119_E00";
CM_ SG_ 1313 IPU_KL30Vol "IPU KL30电压值";
CM_ SG_ 1313 DCDC_St_TMP "DCDC开关管温度";
CM_ SG_ 1313 DCDC_INPUT_VOLT_CHECK_FLT "DCDC输入电压检测回路故障_P197101_E00";
CM_ SG_ 1313 DCDC_OUTPUT_VOLT_CHECK_FLT "DCDC输出电压检测回路故障_P19A229_E00";
CM_ SG_ 1313 DCDC_IntFlt "PDU DCDC内部故障_P19B996_E00";
CM_ SG_ 1313 DCDC_ComLostFlt_PDCU "PDU与PDCU通讯丢失故障_U314987_E00";
CM_ SG_ 1313 DCDC_OutpShoCircFlt "DCDC输出短路故障_P19A111_E00";
CM_ SG_ 1313 DCDC_CrtSts "DCDC当前状态";
CM_ SG_ 1313 BoostCurOverFlt "Boost电流过流故障（软件）_P19AF19_E00";
CM_ SG_ 1313 DCDC_T "DCDC变换器温度";
CM_ SG_ 1638 PDU_SwVersS "IPU次软件版本号";
CM_ SG_ 1638 PDU_PartVers "IPU零部件总成号";
CM_ SG_ 1638 PDU_HwVers "IPU硬件版本号";
CM_ SG_ 1638 PDU_SwVersM "IPU主软件版本号";
CM_ SG_ 1746 OBC_HVDCOutpOverCrtHwFlt "高压直流输出过流硬件故障_P19A619_E00";
CM_ SG_ 1746 OBC_HVDCOutpShortFlt "高压直流输出短路故障_P19A514_E00";
CM_ SG_ 1746 PFC_PowFreMOSOverTFlt "PFC工频MOS管过温_P19854B_E00";
CM_ SG_ 1746 OBC_ACVoltOverVoltFlt "交流电压软件过压故障_P198917_E00";
CM_ SG_ 1746 OBC_ACVoltUnderVoltFlt "交流电压欠压故障_P19A716_E00";
CM_ SG_ 1746 OBC_HVDCOutpOverVoltSwFlt "高压直流输出过压软件故障_P198817_E00";
CM_ SG_ 1746 OBC_HVDCOutpUnderVoltFlt "高压直流输出欠压故障_P19A416_E00";
CM_ SG_ 1746 OBC_InpCrtOverCrtHwSwFlt "交流软件过流故障_P198B19_E00";
CM_ SG_ 1746 PFC_MOSOverTFlt "PFC MOS管过温_P198598_E00";
CM_ SG_ 1746 LLC_OriSideMOSOverTFlt "LLC原边MOS管过温_P198698_E00";
CM_ SG_ 1746 OBC_ACPoweroff "AC掉电故障_P197100_E00";
CM_ SG_ 1746 DiscCPSIGErr "放电CP信号异常故障_P197102_E00";
CM_ SG_ 1746 OBC_LVOutpOverVoltFlt "12V供电电压过压_P198F17_E00";
CM_ SG_ 1746 OBC_LiquidOverTShutDwnFlt "OBC入水口过温保护故障_P19C598_E00";
CM_ SG_ 1746 OBC_LiquidOverTDwnPwrFlt "OBC入水口过温降功率故障_P19C54B_E00";
CM_ SG_ 1746 LLC_SenSideMOSOverTFlt "LLC副边MOS管过温_P19864B_E00";
CM_ SG_ 1746 OBC_HVDCOutpOverVoltHwFlt "高压直流输出过压硬件故障_P198717_E00";
CM_ SG_ 1746 OBC_INVOutpShortFlt "逆变输出短路保护_P19B449_E00";
CM_ SG_ 1746 OBC_INVOutpOverLoadFlt "逆变输出过载_P19B41D_E00";
CM_ SG_ 1746 OBC_PfcCllcSciLost "PFC-CLLC内部SCI通讯故障_P19C696_E00";
CM_ SG_ 1746 OBC_IntOverTFlt "OBC内部过温停机_P19BA98_E00";
CM_ SG_ 1746 OBC_IntFlt "PDU OBC内部故障_P19D200_E00";
CM_ SG_ 1746 BOBC_OverTFlt "BOBC过温关机_P19D298_E00";
CM_ SG_ 1746 PFCBusOverVoltFlt "PFC母线过压_P198517_E00";
CM_ SG_ 1746 OBC_HVDCOutpOverCrtSwFlt "BOBC电池侧过流故障_P19D119_E00";
CM_ SG_ 1746 OBC_ACCrtChkCircFlt "BOBC交流侧电流检测回路故障_P19D002_E00";
CM_ SG_ 1746 PFCBusUnderVoltFlt "PFC母线欠压_P198516_E00";
CM_ SG_ 1746 OBC_INVOutpOverVoltFlt "逆变输出过压_P19B417_E00";
CM_ SG_ 1746 OBC_INVOutpUnderVoltFlt "逆变输出欠压_P19B416_E00";
CM_ SG_ 1746 OBC_INVInpOverVoltFlt "高压直流输入过压保护_P19B217_E00";
CM_ SG_ 1746 OBC_INVInpUnderVoltFlt "高压直流输入欠压保护_P19B216_E00";
CM_ SG_ 1746 OBC_INVOutpOverCurrSlowFlt "逆变输出过流保护_P19B419_E00";
CM_ SG_ 1746 ACInputPhaTypeFlt "交流输入(相数)类型异常故障_P19C400_E00";
CM_ SG_ 1746 CLLCChaStsInpUnderVoltFlt "充电态CLLC输入欠压故障_P19C816_E00";
CM_ SG_ 1746 BOBC_CCSIG_ERR "BOBC检CC信号异常故障_P197202_E00";
CM_ SG_ 1746 BOBC_CPSIG_ERR "BOBC检CP信号异常故障_P197002_E00";
CM_ SG_ 1746 OBC_LVOutpUnderVoltFlt "12V供电电压欠压_P198F16_E00";
CM_ SG_ 1746 BOBC_PowOverVoltHwFlt "BOBC电池侧硬件过压故障_P19D123_E00";
CM_ SG_ 1746 ACFreLowFlt "交流频率过低故障_P198D26_E00";
CM_ SG_ 1746 ACFreHighFlt "交流频率过高故障_P198D27_E00";
CM_ SG_ 1746 BOBC_BatOverCurrHwFlt "BOBC电池侧硬件过流故障_P19D129_E00";
CM_ SG_ 1746 OBC_InpCrtOverCrtHwFlt "BOBC交流侧硬件过流故障_P19D029_E00";
CM_ SG_ 1746 OBC_ACVoltFreqFlt "交流电压频率故障_P19C338_E00";
CM_ SG_ 1746 BUSMidVoltFlt "母线中点电压故障_P19C11C_E00";
CM_ SG_ 1746 OBC_ACSCIntlkSigChkCircFlt "交流慢充互锁信号检测回路开路_P197913_E00";
CM_ SG_ 1746 OBC_PTCIntlkSigChkCircFlt "PTC互锁信号检测回路开路_P19CA13_E00";
CM_ SG_ 1746 OBC_PwrBattIntlkSigChkCircFlt "动力电源互锁信号检测回路开路_P197C13_E00";
CM_ SG_ 1746 OBC_INVCllcBusOverVoltFlt "逆变母线过压_P19B717_E00";
CM_ SG_ 1747 OBC_ACVolt_L1 "车载充电机AC端电压L1";
CM_ SG_ 1747 OBC_T "车载充电机温度";
CM_ SG_ 1747 OBC_ACCrt_L1 "车载充电机AC端电流L1";
CM_ SG_ 1747 OBC_CrtSts "车载充电机当前状态";
CM_ SG_ 1747 PFC_OpenStatus "PFC开启状态";
CM_ SG_ 1747 LLC_OpenStatus "LLC开启状态";
CM_ SG_ 1748 OBC_VCU_AWAK_POW_STA "VCU唤醒OBC电源状态";
CM_ SG_ 1748 OBC_ExtDchaSts_Sokt "对外放电状态_车载插座";
CM_ SG_ 1748 OBC_ExtDchaOutpMaxPwr "OBC对外放电可输出最大功率";
CM_ SG_ 1748 OBC_MinOutpVolt "车载充电机最低输出电压";
CM_ SG_ 1748 OBC_MaxOutpVolt "车载充电机最高输出电压";
CM_ SG_ 1748 OBC_InpVoltRng "车载充电机交流侧输入电压范围";
CM_ SG_ 1748 OBC_Splr "车载充电机供应商";
CM_ SG_ 1748 OBC_Pwr "车载充电机额定功率";
CM_ SG_ 1748 ObcMilReq "OBC的MIL灯请求";
CM_ SG_ 1750 OBC_OperMod "车载充电机工作模式";
CM_ SG_ 1750 IPU_TMP_H "PDU内部最高温度";
CM_ SG_ 1750 PFC_St_TMP "PFC开关管温度";
CM_ SG_ 1750 LLC_St_TMP "LLC开关管温度";
CM_ SG_ 1750 IPU_OBC_PFC_VBUS "PDU内部OBC母线电压";
CM_ SG_ 1751 OBC_SoktCrtPwr "车载插座当前功率_OBC";
CM_ SG_ 1751 OBC_SoktCrtPwrFlg "车载插座当前功率有效位_OBC";
CM_ SG_ 1751 IPUS2SwtSts "S2开关状态IPU";
CM_ SG_ 1751 IPUS1SwtSts "S1开关状态IPU";
CM_ SG_ 1751 OBC_OutpMaxPwr "OBC可输出最大功率";
CM_ SG_ 1324 EWP_FD_Sts "EWP_FD工作状态";
CM_ SG_ 1010 OutdT "车外温度";
CM_ SG_ 1010 OutdTVld "车外温度有效位";
CM_ SG_ 1153 VCU_DCDCOutPVoltCmd "DCDC输出电压指令";
CM_ SG_ 1153 VCU_DC_EN_CMD "DC/DC使能指令";
CM_ SG_ 1153 VCU_Batt_VOLT "VCU蓄电池电压";
CM_ SG_ 1156 VCU_SOCKET_PERM_POW_MAX "车载充电机允许最大耗电功率";
CM_ SG_ 1156 VCU_OBC_CHG_POW_MAX "车载充电机允许最大充电功率";
CM_ SG_ 1156 VCU_SOCKET_ENA_CMD "车载插座系统使能指令";
CM_ SG_ 1157 VCU_SYS_CONSUME_PWR_MAX "电机系统允许最大耗电功率";
CM_ SG_ 1157 VCU_ActvDchaEnaFlg "主动放电使能标志位";
CM_ SG_ 1157 CPDirReq "CP方向请求";
CM_ SG_ 1157 DiscCPDutyRatReq "放电CP占空比请求";
CM_ SG_ 1157 VCU_SYS_FEED_PWR_MAX "电机系统允许最大回馈功率";
CM_ SG_ 1161 MCU_F_DrvrMot1CrtSts "驱动电机1当前状态";
CM_ SG_ 1161 FroMcuWorkSta "前MCU工作状态";
CM_ SG_ 1161 MCU_F_UIGBTTemp0 "U相IGBT上桥臂温度";
CM_ SG_ 1161 MCU_EEPROM_STS "MCU控制器EEPROM状态";
CM_ SG_ 1161 MCU_F_UIGBTTemp1 "U相IGBT下桥臂温度";
CM_ SG_ 1161 MCU_F_VIGBTTemp0 "V相IGBT上桥臂温度";
CM_ SG_ 1161 MCU_F_VIGBTTemp1 "V相IGBT下桥臂温度";
CM_ SG_ 1161 MCU_F_WIGBTTemp0 "W相IGBT上桥臂温度";
CM_ SG_ 1161 MCU_F_WIGBTTemp1 "W相IGBT下桥臂温度";
CM_ SG_ 1161 MCU_I2TEnable "I2T降额使能";
CM_ SG_ 1162 MotAssHeaSta "驱动电机辅助加热状态";
CM_ SG_ 1162 MCU_BRAKE_TOR_MAX "驱动电机最大发电转矩";
CM_ SG_ 1162 MCU_DRIVE_TOR_MAX "驱动电机最大电动转矩";
CM_ SG_ 1162 MotAssHeaPowAbiVal "驱动电机系统辅助加热功率能力值";
CM_ SG_ 1162 MotAssHeaPow "驱动电机系统辅助加热当前功率";
CM_ SG_ 1163 VCU_BRAKE_ENGERY_RECOV_STA "制动能量回收功能禁止标志位";
CM_ SG_ 1297 VCU_VehRemRefrshModReq "整车远程刷写模式需求";
CM_ SG_ 1397 VCU_ExhibitionMode "展车模式信号";
CM_ SG_ 1558 VCU_DRIVE_RANGE "续驶里程";
CM_ BO_ 1559 "EV和C都发，GW收EVBUS,不收CBUS";
CM_ SG_ 1559 VCU_VEH_SPD "VCU车速";
CM_ SG_ 1574 VCU_ComLostFlt_ESP "VCU与ESP通讯相关故障_U100387_E00";
CM_ SG_ 1576 RemSpdTarCmdVld "遥控驾驶目标转速有效位";
CM_ SG_ 1576 RemMotDampgFobd "遥控驾驶主动阻尼禁止标志位";
CM_ SG_ 1576 VCU_VEH_MODE "整车模式";
CM_ SG_ 1576 BattVoltAnormStopDiagFlg "蓄电池电压异常停诊断标志位";
CM_ SG_ 1576 VCUZeroTorFlg "VCU请求瞬时零扭矩标志位";
CM_ SG_ 1576 VCU_TEMOTE_POWER_ON_REQ "遥控驾驶上电需求";
CM_ SG_ 1585 VCU_Socket_SWH_REQ_CMD "车载插座开启关闭需求指令";
CM_ SG_ 1588 VCU_ACChrgCrtUpprLmt "交流充电电流上限";
CM_ SG_ 1599 MCU_CAL_VERS "MCU次软件版本号";
CM_ SG_ 1599 MCU_PART_VERS "MCU零部件总成号";
CM_ SG_ 1599 MCU_HW_VERS "MCU硬件版本号";
CM_ SG_ 1599 MCU_SW_VERS "MCU主软件版本号";
CM_ SG_ 1614 VCU_COLL_SIG_STA "碰撞信号状态_P103C00_E03";
CM_ SG_ 1624 MotAssHeaCmd "驱动电机辅助加热指令";
CM_ SG_ 1624 ParkAssHeaPowLimVal "驻车工况辅助加热功率限值";
CM_ SG_ 1624 MotAssHeaPowCmd "驱动电机辅助加热功率指令";
CM_ SG_ 1624 MotAssHeaEnaCmd "驱动电机辅助加热使能指令";
CM_ SG_ 1683 MCU_AngEIPosValue "驱动电机零点值";
CM_ SG_ 1683 MCU_F_ReadZeroPointErr "零位值读取失败故障";
CM_ SG_ 1683 MCU_F_CheckPoint1Err "零点值1读取校验故障";
CM_ SG_ 1683 MCU_F_CheckPoint2Err "零点值2读取校验故障";
CM_ SG_ 1683 MCU_F_CheckOverRangeErr "零点值超范围故障";
CM_ SG_ 1683 MCU_MCU_SUPPLIER "驱动电机控制器供应商";
CM_ SG_ 1683 MCU_CAL_SW_VER "标定软件版本号";
CM_ SG_ 1683 MCU_F_CheckDifferentErr "零点值校验故障";
CM_ SG_ 1683 MCU_F_CheckPointinvalidErr "零点值无效故障";
CM_ SG_ 1683 McuEgyFbLimSta "禁止能量回收限制状态MCU";
CM_ SG_ 1683 dmc_dTCS_SWInfo "dTCS的软件版本号";
CM_ BO_ 1728 "EV和C都发，GW收EVBUS,不收CBUS";
CM_ SG_ 1728 VCU_READY_LAMP "READY灯";
CM_ SG_ 1728 VCU_MEN_CHGR_MILG_THD "记忆充电提醒里程阈值";
CM_ SG_ 1739 MCU_Motor_SUM "驱动电机总数";
CM_ SG_ 1739 McuMotorNum "驱动电机序号";
CM_ SG_ 1739 MCU_MCU_F_SUM "驱动电机故障总数";
CM_ SG_ 1739 McuIgbtTemp "驱动电机控制器IGBT温度(国标)";
CM_ SG_ 1739 McuMotSpd "驱动电机当前转速(国标)";
CM_ SG_ 1739 McuMotTemp "驱动电机温度(国标)";
CM_ SG_ 1739 MCU_F_DrvrMot1CrtSts_GB "驱动电机1当前状态(国标)";
CM_ SG_ 1739 MCU_F_MCUTempAlarmLv1 "前驱动电机控制器温度报警（1级）_P11B04B_E00";
CM_ SG_ 1739 MCU_F_MCUTempAlarmLv2 "前驱动电机控制器温度报警（2级）_P11B04C_E00";
CM_ SG_ 1739 MCU_F_MotTempAlarmLv1 "前驱动电机温度报警（1级）_P11B098_E00";
CM_ SG_ 1739 MCU_F_MotTempAlarmLv2 "前驱动电机温度报警（2级）_P11B099_E00";
CM_ SG_ 1739 MCU_F_OverSpdAlarmLv1 "前驱动电机超速报警（1级）_P11B027_E00";
CM_ SG_ 1739 MCU_F_OverSpdAlarmLv2 "前驱动电机超速报警（2级）_P11B02A_E00";
CM_ SG_ 1739 MCU_F_OverCurAlarmLv1 "前驱动电机过流报警（1级）_P11B019_E00";
CM_ SG_ 1739 MCU_F_OverCurAlarmLv2 "前驱动电机过流报警（2级）_P11B02C_E00";
CM_ SG_ 1739 MCU_F_OverCurAlarmLv3 "前驱动电机过流报警（3级）_P11B02D_E00";
CM_ SG_ 1739 McuMotTor "驱动电机当前转矩(国标)";
CM_ SG_ 1739 McuDcCur "直流母线电流(国标)";
CM_ SG_ 1739 McuDcVolt "直流母线电压(国标)";
CM_ SG_ 1740 MCU_MotCode1 "驱动电机编号1(表示编号中1到8个ASC码值)";
CM_ SG_ 1741 MCU_MotCode2 "驱动电机编号2(表示编号中9到16个ASC码值)";
CM_ SG_ 1742 MCU_MotCode3 "驱动电机编号3(表示编号中17到24个ASC码值)";
CM_ SG_ 1743 MCU_MotCode4 "驱动电机编号4(表示编号中25到32个ASC码值)";
CM_ SG_ 512 VCUSpeedLimTypRq "VCU请求限速类型";
CM_ BO_ 534 "EV和C都发，GW收EVBUS,不收CBUS";
CM_ SG_ 534 MCU_216_CheckSum "MCU报文校验和（Profile：1A；DataID：0x0079）";
CM_ SG_ 534 MCU_216_AliveCounter "MCU报文计数器";
CM_ SG_ 534 MCU_MOT_ActiveDamping_Flg "主动阻尼使能标志位";
CM_ SG_ 534 MCU_MOT_DIR_CMD "驱动电机当前旋转方向";
CM_ SG_ 534 MCU_MOT_SPD "驱动电机当前转速";
CM_ SG_ 534 MCU_MOT_TOR "驱动电机当前转矩";
CM_ SG_ 534 MCU_TOR_QUA_AFC "驱动电机当前转矩有效位";
CM_ SG_ 534 MCU_MOT_INIT "MCU初始化状态";
CM_ SG_ 534 MCU_SPD_QUA_AFC "驱动电机当前转速信号有效位";
CM_ SG_ 534 MCU_HV_CHECK_FLAG "驱动电机控制器高压检测完成标志位";
CM_ SG_ 534 MCU_HV_DISOBC_STA "高压主动放电状态";
CM_ SG_ 534 MCU_LV_OFF_REQ_FLAG "驱动电机控制器低压下电请求标志位";
CM_ SG_ 534 MCU_MOT_STA "驱动电机当前状态";
CM_ SG_ 534 MCU_MOT_MODE "驱动电机当前工作模式";
CM_ BO_ 528 "EV和C都发，GW收EVBUS,不收CBUS";
CM_ SG_ 528 VCU_DRV_APS_PER_FLG "驾驶员加速踏板开度有效位";
CM_ SG_ 528 VCU_DRV_APS_PER "驾驶员加速踏板开度";
CM_ SG_ 528 VCU_BRAKE_STA "制动信号";
CM_ BO_ 531 "EV和C都发，GW收EVBUS,不收CBUS";
CM_ SG_ 531 VCU_213_CheckSum "VCU报文校验和（Profile：1A；DataID：0x00D3）";
CM_ SG_ 531 VCU_213_AliveCounter "VCU报文计数器";
CM_ SG_ 531 VCU_MOT_SPD_CMD "驱动电机目标转速指令";
CM_ SG_ 531 VCU_MOT_MODE_CMD "驱动电机工作模式命令";
CM_ SG_ 531 VCU_DTCRecoverRequest_BE12 "VCU请求BMS\MCU故障恢复标志位";
CM_ SG_ 531 VCU_MCU_ENABLE_CMD "MCU使能命令";
CM_ BO_ 532 "EV和C都发，GW收EVBUS,不收CBUS";
CM_ SG_ 532 VCU_214_CheckSum "VCU报文校验和（Profile：1A；DataID：0x00D4）";
CM_ SG_ 532 VCU_214_AliveCounter "VCU报文计数器";
CM_ SG_ 532 VCU_ON_WAKEUP "ON挡唤醒信号";
CM_ SG_ 532 VCU_VEH_STATE "整车State状态（状态机编码）";
CM_ BO_ 560 "EV和C都发，GW收EVBUS,不收CBUS";
CM_ SG_ 560 VCU_230_CheckSum "VCU报文校验和（Profile：1A；DataID：0x0055）";
CM_ SG_ 560 VCU_230_AliveCounter "VCU报文计数器";
CM_ SG_ 560 VCU_STRATEGY_SHIFT_POSITION "挡位信号";
CM_ SG_ 560 VCU_GearShiftInternal "策略挡位信号";
CM_ SG_ 560 VCU_STRATEGY_SHIFT_POSN_FLAG "挡位信号有效位";
CM_ SG_ 566 VCU_ChrgDchaGunCnctnSts "充放电枪连接状态";
CM_ SG_ 566 VCU_S2SwtSts "S2开关状态";
CM_ SG_ 619 MCU_STS_MNGT_STS "电机控制器状态管理状态";
CM_ SG_ 619 MCU_STS_MNGT_OUPT_TRQ "电机控制器状态管理输出扭矩";
CM_ SG_ 619 MCU_TRQ_MNGT_OUPT_TRQ "电机控制器扭矩管理输出扭矩";
CM_ BO_ 834 "EV和C都发，GW收EVBUS,不收CBUS";
CM_ SG_ 834 VCU_ADA_SLIDE_REQ_FLG "自适应滑行扭矩请求标志位";
CM_ SG_ 834 VCU_ENERY_CONSUM_AVE "用户工况平均电耗信号";
CM_ SG_ 835 MCU_F_KL15ON_flg "前驱动电机唤醒信号";
CM_ SG_ 835 MCU_REQ_VCU_FLG "驱动电机请求整车控制器处理标志位";
CM_ SG_ 835 MCU_MOT_TEMP "驱动电机温度";
CM_ SG_ 835 MCUFLaultLevel "前MCU故障处理等级";
CM_ SG_ 835 MCU_IGBT_TEMP "驱动电机控制器IGBT温度";
CM_ SG_ 835 MCU_CLOSE_ENA_FKG "MCU请求关闭使能标志位";
CM_ SG_ 835 MCU_ZERO_TOQ_FLG "MCU请求零扭矩标志位";
CM_ SG_ 835 MCU_MOT_FAULT_LAMP "驱动电机系统故障显示";
CM_ SG_ 835 MCU_ALARM_LEVEL_MAX "MCU最高报警等级";
CM_ SG_ 837 MCU_DC_SEN_DRIFT "MCU直流母线电流传感器零漂故障_P118D28_E00";
CM_ SG_ 837 MCU_CUR_SAMP_CIR_U "MCU相电流采样回路故障(U相)_P118A12_E03";
CM_ SG_ 837 MCU_CUR_SAMP_CIR_V "MCU相电流采样回路故障(V相)_P118B12_E03";
CM_ SG_ 837 MCU_CUR_SAMP_CIR_W "MCU相电流采样回路故障(W相)_P118C12_E03";
CM_ SG_ 837 MCU_DC_SAMP_CUR "MCU直流母线电流采样回路故障_P0A5101_E00";
CM_ SG_ 837 MCU_3PHASE_CUR_CHE_FAULT "驱动电机三相电流校验故障_P112164_E03";
CM_ SG_ 837 MCU_BUSBAR_VOLT_LOW "MCU直流母线欠压故障_P114016_E03";
CM_ SG_ 837 MCU_BUSBAR_VOLT_HIGH "MCU直流母线过压故障_P114017_E03";
CM_ SG_ 837 MCU_BUS_VOLIT_SAMP_FAULT "直流母线电压采样回路故障_P11841C_E03";
CM_ SG_ 837 MCU_OVER_SPD_FAULT "驱动电机超速故障_P0A4400_E03";
CM_ SG_ 837 MCU_IGBT_TEMP_OVER_U "MCU内部IGBT过温故障(U相)_P117098_E03";
CM_ SG_ 837 MCU_IGBT_TEMP_OVER_V "MCU内部IGBT过温故障(V相)_P117198_E03";
CM_ SG_ 837 MCU_IGBT_TEMP_OVER_W "MCU内部IGBT过温故障(W相)_P117298_E00";
CM_ SG_ 837 MCU_IGBT_TEMP_CHECK_CUR_U "MCU内部IGBT温度检测回路故障(U相)_P11801C_E00";
CM_ SG_ 837 MCU_IGBT_TEMP_CHECK_CUR_V "MCU内部IGBT温度检测回路故障(V相)_P11811C_E00";
CM_ SG_ 837 MCU_IGBT_TEMP_CHECK_CUR_W "MCU内部IGBT温度检测回路故障(W相)_P11821C_E00";
CM_ SG_ 837 MCU_MOTOR_TEMP_OVER "驱动电机过温故障_P0A2F98_E00";
CM_ SG_ 837 MCU_MOT_TEMP_CHECK_CUR "驱动电机温度检测回路故障_P0A001C_E00";
CM_ SG_ 837 MCU_MCU_TEMP_OVER "MCU过温故障_P117F98_E00";
CM_ SG_ 837 MCUPowOnIniFlt "MCU上电初始化故障_P110052_E00";
CM_ SG_ 837 MCU_BATT_VOLT_LOW "MCU低压电源欠压故障_U300316C_E03";
CM_ SG_ 837 MCU_BATT_VOLT_HIGH "MCU低压电源过压故障_U300317C_E03";
CM_ SG_ 837 MCU_F_PosZeroErr "MCU位置信号零点故障_P11B028_E00";
CM_ SG_ 837 MCU_HW_CUR_HIGH_W "MCU相电流硬件过流故障(W相)_P116216_E03";
CM_ SG_ 837 MCU_FEED_TOR_ORDER_CHE_FAULT "MCU反馈转矩与转矩指令校验错误_P113064_E03";
CM_ SG_ 837 MCU_HL_VOLT_INTERLOCK_FAULT "MCU检驱动电机高压互锁故障_P116B94_E00";
CM_ SG_ 837 MCU_SW_CUR_HIGH "MCU相电流软件过流故障_P113519_E03";
CM_ SG_ 837 MCU_HW_CUR_HIGH_U "MCU相电流硬件过流故障(U相)_P116016_E03";
CM_ SG_ 837 MCU_HW_CUR_HIGH_V "MCU相电流硬件过流故障(V相)_P116116_E03";
CM_ SG_ 837 MCU_EAS_HL_INTERLOCK_FAULT "MCU检空调EAS高压互锁故障_P116694_E00";
CM_ SG_ 837 MCU_PTC_HL_INTERLOCK_FAULT "MCU检空调PTC/WTC高压互锁故障_P116794_E00";
CM_ SG_ 837 MCU_BATT_HL_INTERLOCK_FAULT "MCU检动力电源高压互锁故障_P116894_E00";
CM_ SG_ 837 MCU_MC_HL_INTERLOCK_FAULT "MCU检慢充高压互锁故障_P116994_E00";
CM_ SG_ 837 MCU_QC_HL_INTERLOCK_FAULT "MCU检快充高压互锁故障_P116A94_E00";
CM_ SG_ 838 MCU_COM_VCU_LOSE "MCU与VCU通讯丢失故障_U010087C_E00";
CM_ SG_ 838 McuActDchFlt "主动放电故障_P116D04_E00";
CM_ SG_ 838 McuSafStaCheFlt "安全状态检测故障_P116C41_E00";
CM_ SG_ 838 McuDcCurHighFlt "MCU直流母线电流过流故障_P111119_E00";
CM_ SG_ 838 Mot3PhaLoseFlt "电机三相缺相故障_P110164_E00";
CM_ SG_ 838 McuMstChipFlt "MCU主控芯片故障_P110796_E00";
CM_ SG_ 838 IGBT3PhaseTChecFlt "IGBT三相温度校验故障_P116E41_E00";
CM_ SG_ 838 McuIntComFlt "MCU内部通讯故障_U110C87_E00";
CM_ SG_ 838 IntTorChecFlt "内部扭矩校验故障_P116096_E00";
CM_ SG_ 838 RunModFlt "运行模式异常故障_P11AE62_E00";
CM_ SG_ 838 MCU_IGBI_UPPR_BRDG_FLT_U "MCU IGBT驱动电路故障(U相上桥臂)_P11A101_E00";
CM_ SG_ 838 MCU_IGBI_LOWR_BRDG_FLT_U "MCU IGBT驱动电路故障(U相下桥臂)_P11A201_E00";
CM_ SG_ 838 MCU_IGBI_UPPR_BRDG_FLT_V "MCU IGBT驱动电路故障(V相上桥臂)_P11A301_E00";
CM_ SG_ 838 MCU_IGBI_LOWR_BRDG_FLT_V "MCU IGBT驱动电路故障(V相下桥臂)_P11A401_E00";
CM_ SG_ 838 MCU_IGBI_UPPR_BRDG_FLT_W "MCU IGBT驱动电路故障(W相上桥臂)_P11A501_E00";
CM_ SG_ 838 MCU_IGBI_LOWR_BRDG_FLT_W "MCU IGBT驱动电路故障(W相下桥臂)_P11A601_E00";
CM_ SG_ 838 MCU_WAKE_SIG_FLT "MCU唤醒信号故障_P11A902_E00";
CM_ SG_ 838 McuSwCurHighU "MCU相电流软件过流故障（U相）_P110419_E00";
CM_ SG_ 838 McuSwCurHighV "MCU相电流软件过流故障（V相）_P110519_E00";
CM_ SG_ 838 McuSwCurHighW "MCU相电流软件过流故障（W相）_P110619_E00";
CM_ SG_ 838 McuBattModFlt "MCU电源模块故障_P11A01C_E03";
CM_ SG_ 838 McuConTempCheckCurFlt "MCU控制板温度检测回路故障_P116F1C_E00";
CM_ SG_ 838 McuPosCheckCurFlt "MCU位置信号检测回路故障_P0A3F00_E00";
CM_ SG_ 838 MCU_E2E_ERR "MCU E2E故障_U010185_E00";
CM_ SG_ 855 VCU_OTAClsChrgCmd "OTA关闭交流充电指令";
CM_ BO_ 295 "EV和C都发，GW收EVBUS,不收CBUS";
CM_ SG_ 295 McuApsPer "加速踏板开度";
CM_ SG_ 295 McuApsPerFlag "加速踏板开度有效位";
CM_ SG_ 295 McuMotDampgFobdFlg "电机主动阻尼禁止标志位";
CM_ SG_ 295 McuMotTorCmd "驱动电机目标转矩指令";
CM_ SG_ 295 DrvTorReq "驾驶员转矩请求(轮端)";
CM_ SG_ 295 DrvTorReqFlg "驾驶员转矩请求有效位";
CM_ SG_ 1387 BMS_CELL_TEMP_MIN "最低温度值";
CM_ SG_ 513 BMS_OBC_VOLT_OUT_CMD "车载充电机输出电压指令";
CM_ SG_ 513 BMS_OBC_CUR_RQ "车载充电机输出电流指令";
CM_ SG_ 513 BMS_OBC_CMD "车载充电机工作指令";
CM_ SG_ 513 BMS_S2_SW_CMD "S2开关控制命令";
CM_ SG_ 513 BMS_S1_SWT_CMD "S1开关指令";
CM_ SG_ 513 BMS_VEH_MODE "车辆充放电模式";
CM_ SG_ 535 BMS_DISOBC_MAX_PWR "当前状态允许最大放电功率";
CM_ SG_ 535 BMS_BATT_SOC "动力电池剩余电量SOC";
CM_ SG_ 535 BMS_SELF_CHECK_COUNTER "BMS自检计数器";
CM_ SG_ 535 BMS_BATTSocReal "动力电池标准荷电状态";
CM_ SG_ 535 BMS_PwrBattRmngCpSOCHiAccuracy "动力电池剩余电量SOC(高精度)";
CM_ SG_ 536 BMS_BATT_CUR "动力电池充/放电电流";
CM_ SG_ 276 VCUVehFaultLevel "整车故障处理等级";
CM_ SG_ 276 AccelModCoeDex "加速模式系数";
CM_ SG_ 276 WheelPreTor "轮端预紧扭矩";
CM_ SG_ 276 BrakTorDex "刹停扭矩系数";
CM_ SG_ 276 WormEnaFlg "蠕行使能标志位";
CM_ SG_ 276 DrivSysActFlg "传动系激活标志位";
CM_ SG_ 276 ABSActFlg "ABS激活标志位";
CM_ SG_ 276 CRBSActFlg "CRBS激活标志位";
CM_ SG_ 276 WormTorDex "蠕行扭矩系数";
CM_ SG_ 276 TorFilSta "扭矩滤波状态";
CM_ SG_ 276 ACCActFlg "ACC激活标志位";
CM_ SG_ 276 TorEnaFlg "扭矩使能标志位";
CM_ SG_ 276 BmsEngRecForbFlg "BMS禁止能量回收标志位";
CM_ SG_ 276 WheelHubMod "转毂模式";
CM_ SG_ 276 EneRecGraDex "能量回收强度系数";
CM_ SG_ 276 FronWheTorRq "前轴轮端扭矩需求";
CM_ SG_ 276 TransRat "传动比";
CM_ SG_ 276 TransEffic "传动效率";
CM_ SG_ 276 BrakPedTra "制动踏板行程";
CM_ SG_ 276 SpeedLimFlg "限速标志位";
CM_ SG_ 276 DrivAntiSliSwt "驱动防滑开关";
CM_ SG_ 276 RecAntiSliSwt "回收防滑开关";
CM_ SG_ 276 AbsArbSwt "ABS仲裁开关";
CM_ SG_ 276 TcsArbSwt "TCS仲裁开关";
CM_ SG_ 276 DtcArbSwt "DTC仲裁开关";
CM_ BO_ 277 "EV和C都发，GW收EVBUS,不收CBUS";
CM_ SG_ 277 FroMotTorRisGrad "前电机扭矩上升梯度";
CM_ SG_ 277 McuAlrmLampFS "报警灯_前驱动电机（功能安全）";
CM_ SG_ 277 McuMotArbTor "驱动电机仲裁扭矩";
CM_ SG_ 277 FrOnEspTorArbSta "前ESP扭矩仲裁状态";
CM_ SG_ 277 McuMotWheelTor "驱动电机当前转矩（轮端）";
CM_ SG_ 277 McuMotWheelTorValid "驱动电机当前转矩（轮端）有效位";
CM_ SG_ 277 RatRedDex "前驱电机扭矩降额系数";
CM_ SG_ 533 MCU_F_DCurrent_Cmd "前驱动电机id指令电流";
CM_ SG_ 533 MCU_F_DCurrent_Fb "前驱动电机id反馈电流";
CM_ SG_ 533 MCU_F_QCurrent_Cmd "前驱动电机iq指令电流";
CM_ SG_ 533 MCU_F_QCurrent_Fb "前驱动电机iq反馈电流";
CM_ SG_ 533 MCU_F_Volt_Percent "前驱动电机母线电压利用率";
CM_ SG_ 533 MCU_F_Ang_Delta "前驱动电机旋变增量";
CM_ SG_ 533 MCU_F_MotSpdFilteredLow "前驱动电机电机转速(低延时)";
CM_ SG_ 533 MCU_F_F_CrtTq_act "前驱动电机当前转矩（act）";
CM_ SG_ 1404 VCU_FactryCod1 "厂家编码1";
CM_ SG_ 1404 VCU_FactryCod2 "厂家编码2";
CM_ SG_ 1404 VCU_VehPileRndCod1 "车桩校验随机码1";
CM_ SG_ 1404 VCU_VehPileRndCod2 "车桩校验随机码2";
CM_ SG_ 1404 VCU_VehPileRndCod3 "车桩校验随机码3";
CM_ SG_ 1404 VCU_VehPileRndCod4 "车桩校验随机码4";
CM_ SG_ 1404 VCU_VehPileRndCod5 "车桩校验随机码5";
CM_ SG_ 1268 OTAHVPwrMod "OTA高低压模式";
CM_ SG_ 753 TrOpenStsSwt "尾门开关状态";
CM_ SG_ 753 DrvrDoorOpenStsSwt "主驾车门开关状态";
CM_ SG_ 753 PassDoorOpenStsSwt "副驾车门开关状态";
CM_ SG_ 753 ReLeDoorOpenStsSwt "左后车门开关状态";
CM_ SG_ 753 ReRiDoorOpenStsSwt "右后车门开关状态";
CM_ SG_ 753 HoodLidOpenStsSwt "前舱盖开关状态";
CM_ SG_ 753 BdcVehMod "车辆模式";
CM_ SG_ 1361 TBOX_CrtTi_Day "当前时间_日";
CM_ SG_ 1361 TBOX_CrtTi_Hr "当前时间_小时";
CM_ SG_ 1361 TBOX_CrtTi_Mins "当前时间_分钟";
CM_ SG_ 1361 TBOX_CrtTi_Yr "当前时间_年";
CM_ SG_ 1361 TBOX_CrtTi_Mth "当前时间_月";
CM_ SG_ 1361 TBOX_CrtTi_Sec "当前时间_秒";
CM_ BO_ 389 "轮速相关";
CM_ SG_ 389 FrntRiWhlSpd "右前轮速";
CM_ SG_ 389 FrntRiWhlSpdVld "右前轮速有效位。";
CM_ SG_ 389 FrntLeWhlSpd "左前轮速";
CM_ SG_ 389 FrntLeWhlSpdVld "左前轮速有效位。";
CM_ SG_ 389 ReRiWhlSpd "右后轮速";
CM_ SG_ 389 ReRiWhlSpdVld "右后轮速有效位。";
CM_ SG_ 389 ReLeWhlSpd "左后轮速";
CM_ SG_ 389 ReLeWhlSpdVld "左后轮速有效位。";
CM_ SG_ 389 VehStop "车辆停止状态位";
CM_ SG_ 389 VehSpdVld "车速信号有效位.";
CM_ SG_ 389 VehSpd "车速信号";
CM_ SG_ 433 PwrMod "低压电源状态";
CM_ SG_ 433 PwrModVld "低压电源状态有效位";
CM_ SG_ 281 EGSMFltSts "电子档把故障状态";
CM_ SG_ 281 EGSMGearLvrCrtPosnInfo "怀挡手柄当前位置信息";
CM_ SG_ 304 ActTqVld "Actual torque validity.Describes the condition of  'ActTq‘, 'ActMaxTq' and ’ActMinTq‘.";
CM_ SG_ 304 EmsCalcdLoadVal "EMS calculated load value.This signal Indicates EMS calculated load value. (OBD signal,refer to the definition of OBD regulation)";
CM_ SG_ 304 ActEngSpdUnfil "发动机转速";
CM_ SG_ 304 EmsAbsltAccrPedlPosn "用于OBD的绝对油门踏板位置（数据流冻结帧PID49）";
CM_ BO_ 822 "蓝牙控制及远程启动";
CM_ SG_ 822 RemCtrlDrvgReq "遥控驾驶进入请求";
CM_ SG_ 822 BleCarCtrlAPPHertbtSig "蓝牙控车APP心跳信号";
CM_ SG_ 822 BleChildTeasSouSta "逗娃灯光音效开关状态";
CM_ BO_ 305 "EV和C都发，GW收CBUS,不收EVBUS";
CM_ SG_ 305 EmsEngWrmUpAch "Engine Warm up achieved.Engine Warm up cycle has been achieved";
CM_ SG_ 305 EmsCooltT "发动机水温";
CM_ BO_ 998 "EV和C都发，GW收CBUS,不收EVBUS";
CM_ SG_ 998 EmsDrvgCyc "Driving cycle.Indicates whether the engine is in driving cycle.";
BA_DEF_ BO_  "GenMsgSendType" ENUM  "cyclic","Event","IfActive","POE","PA","FixedPeriodic","Event","EnabledPeriodic","NotUsed","NotUsed","EventPeriodic","NotUsed","NotUsed","NoMsgSendType";
BA_DEF_ SG_  "EventCommandSignal" ENUM  "No","Yes";
BA_DEF_ SG_  "GatewayedSignals" ENUM  "No","Yes";
BA_DEF_ SG_  "GenSigInactiveValue" HEX 0 0;
BA_DEF_ SG_  "GenSigInvalidValue" HEX 0 0;
BA_DEF_ SG_  "GenSigSendType" ENUM  "Trigger","Passive","Cyclic","OnWrite","OnWriteWithRepetition","OnChange","OnChangeWithRepetition","IfActive","IfActiveWithRepetition","NoSigSendType";
BA_DEF_ SG_  "GenSigTimeoutValue" HEX 0 0;
BA_DEF_ SG_  "Remark" STRING ;
BA_DEF_ BO_  "NmMessage" ENUM  "No","Yes";
BA_DEF_ BO_  "DiagState" ENUM  "No","Yes";
BA_DEF_ BO_  "DiagResponse" ENUM  "No","Yes";
BA_DEF_ BO_  "GenMsgCycleTime" INT 0 0;
BA_DEF_ SG_  "GenSigStartValue" INT 0 0;
BA_DEF_ BO_  "GenMsgCycleTimeFast" INT 0 0;
BA_DEF_ BO_  "GenMsgNrOfRepetition" INT 0 0;
BA_DEF_ BO_  "CANFD_BRS" ENUM  "0","1";
BA_DEF_ BO_  "VFrameFormat" ENUM  "StandardCAN","ExtendedCAN","reserved","reserved","reserved","reserved","reserved","reserved","reserved","reserved","reserved","reserved","reserved","reserved","StandardCAN_FD","ExtendedCAN_FD";
BA_DEF_ BO_  "GenMsgILSupport" ENUM  "No","Yes";
BA_DEF_ SG_  "sigDespEng" STRING ;
BA_DEF_ SG_  "sigSecLevel" STRING ;
BA_DEF_ SG_  "sigConfig" STRING ;
BA_DEF_ SG_  "sigExplanation" STRING ;
BA_DEF_ SG_  "SystemSignalLongSymbol" STRING ;
BA_DEF_DEF_  "GenMsgSendType" "cyclic";
BA_DEF_DEF_  "EventCommandSignal" "";
BA_DEF_DEF_  "GatewayedSignals" "";
BA_DEF_DEF_  "GenSigInactiveValue" 0;
BA_DEF_DEF_  "GenSigInvalidValue" 0;
BA_DEF_DEF_  "GenSigSendType" "";
BA_DEF_DEF_  "GenSigTimeoutValue" 0;
BA_DEF_DEF_  "Remark" "";
BA_DEF_DEF_  "NmMessage" "No";
BA_DEF_DEF_  "DiagState" "No";
BA_DEF_DEF_  "DiagResponse" "No";
BA_DEF_DEF_  "GenMsgCycleTime" 0;
BA_DEF_DEF_  "GenSigStartValue" 0;
BA_DEF_DEF_  "GenMsgCycleTimeFast" 0;
BA_DEF_DEF_  "GenMsgNrOfRepetition" 0;
BA_DEF_DEF_  "CANFD_BRS" "1";
BA_DEF_DEF_  "VFrameFormat" "StandardCAN";
BA_DEF_DEF_  "GenMsgILSupport" "Yes";
BA_DEF_DEF_  "sigDespEng" "";
BA_DEF_DEF_  "sigSecLevel" "QM";
BA_DEF_DEF_  "sigConfig" "";
BA_DEF_DEF_  "sigExplanation" "";
BA_DEF_DEF_  "SystemSignalLongSymbol" "";
BA_ "CANFD_BRS" BO_ 1025 0;
BA_ "GenMsgCycleTime" BO_ 1025 500;
BA_ "NmMessage" BO_ 1025 1;
BA_ "CANFD_BRS" BO_ 1046 0;
BA_ "GenMsgCycleTime" BO_ 1046 500;
BA_ "NmMessage" BO_ 1046 1;
BA_ "CANFD_BRS" BO_ 1026 0;
BA_ "GenMsgCycleTime" BO_ 1026 500;
BA_ "NmMessage" BO_ 1026 1;
BA_ "CANFD_BRS" BO_ 1059 0;
BA_ "GenMsgCycleTime" BO_ 1059 500;
BA_ "NmMessage" BO_ 1059 1;
BA_ "CANFD_BRS" BO_ 1141 0;
BA_ "GenMsgCycleTime" BO_ 1141 500;
BA_ "NmMessage" BO_ 1141 1;
BA_ "GenMsgCycleTime" BO_ 521 20;
BA_ "VFrameFormat" BO_ 521 14;
BA_ "GenMsgCycleTime" BO_ 296 10;
BA_ "VFrameFormat" BO_ 296 14;
BA_ "GenMsgCycleTime" BO_ 1152 20;
BA_ "VFrameFormat" BO_ 1152 14;
BA_ "GenMsgCycleTime" BO_ 1304 100;
BA_ "VFrameFormat" BO_ 1304 14;
BA_ "GenMsgCycleTime" BO_ 1313 100;
BA_ "VFrameFormat" BO_ 1313 14;
BA_ "GenMsgCycleTime" BO_ 1638 1000;
BA_ "VFrameFormat" BO_ 1638 14;
BA_ "GenMsgCycleTime" BO_ 1746 1000;
BA_ "VFrameFormat" BO_ 1746 14;
BA_ "GenMsgCycleTime" BO_ 1747 1000;
BA_ "VFrameFormat" BO_ 1747 14;
BA_ "GenMsgCycleTime" BO_ 1748 100;
BA_ "VFrameFormat" BO_ 1748 14;
BA_ "GenMsgCycleTime" BO_ 1750 1000;
BA_ "VFrameFormat" BO_ 1750 14;
BA_ "GenMsgCycleTime" BO_ 1751 100;
BA_ "VFrameFormat" BO_ 1751 14;
BA_ "GenMsgCycleTime" BO_ 1324 1000;
BA_ "VFrameFormat" BO_ 1324 14;
BA_ "GenMsgCycleTime" BO_ 1010 100;
BA_ "VFrameFormat" BO_ 1010 14;
BA_ "GenMsgCycleTime" BO_ 1153 100;
BA_ "VFrameFormat" BO_ 1153 14;
BA_ "GenMsgCycleTime" BO_ 1156 100;
BA_ "VFrameFormat" BO_ 1156 14;
BA_ "GenMsgCycleTime" BO_ 1157 100;
BA_ "VFrameFormat" BO_ 1157 14;
BA_ "GenMsgCycleTime" BO_ 1161 100;
BA_ "VFrameFormat" BO_ 1161 14;
BA_ "GenMsgCycleTime" BO_ 1162 100;
BA_ "VFrameFormat" BO_ 1162 14;
BA_ "GenMsgCycleTime" BO_ 1163 100;
BA_ "VFrameFormat" BO_ 1163 14;
BA_ "GenMsgCycleTime" BO_ 1297 100;
BA_ "VFrameFormat" BO_ 1297 14;
BA_ "GenMsgCycleTime" BO_ 1397 100;
BA_ "VFrameFormat" BO_ 1397 14;
BA_ "GenMsgCycleTime" BO_ 1558 100;
BA_ "VFrameFormat" BO_ 1558 14;
BA_ "GenMsgCycleTime" BO_ 1559 100;
BA_ "VFrameFormat" BO_ 1559 14;
BA_ "GenMsgCycleTime" BO_ 1574 100;
BA_ "VFrameFormat" BO_ 1574 14;
BA_ "GenMsgCycleTime" BO_ 1576 100;
BA_ "VFrameFormat" BO_ 1576 14;
BA_ "GenMsgCycleTime" BO_ 1585 100;
BA_ "VFrameFormat" BO_ 1585 14;
BA_ "GenMsgCycleTime" BO_ 1588 1000;
BA_ "VFrameFormat" BO_ 1588 14;
BA_ "GenMsgCycleTime" BO_ 1599 1000;
BA_ "VFrameFormat" BO_ 1599 14;
BA_ "GenMsgCycleTime" BO_ 1614 1000;
BA_ "VFrameFormat" BO_ 1614 14;
BA_ "GenMsgCycleTime" BO_ 1624 100;
BA_ "VFrameFormat" BO_ 1624 14;
BA_ "GenMsgCycleTime" BO_ 1683 1000;
BA_ "VFrameFormat" BO_ 1683 14;
BA_ "GenMsgCycleTime" BO_ 1728 50;
BA_ "VFrameFormat" BO_ 1728 14;
BA_ "GenMsgCycleTime" BO_ 1739 100;
BA_ "VFrameFormat" BO_ 1739 14;
BA_ "GenMsgCycleTime" BO_ 1740 5000;
BA_ "VFrameFormat" BO_ 1740 14;
BA_ "GenMsgCycleTime" BO_ 1741 5000;
BA_ "VFrameFormat" BO_ 1741 14;
BA_ "GenMsgCycleTime" BO_ 1742 5000;
BA_ "VFrameFormat" BO_ 1742 14;
BA_ "GenMsgCycleTime" BO_ 1743 5000;
BA_ "VFrameFormat" BO_ 1743 14;
BA_ "GenMsgCycleTime" BO_ 512 20;
BA_ "VFrameFormat" BO_ 512 14;
BA_ "GenMsgCycleTime" BO_ 534 20;
BA_ "VFrameFormat" BO_ 534 14;
BA_ "GenMsgCycleTime" BO_ 528 10;
BA_ "VFrameFormat" BO_ 528 14;
BA_ "GenMsgCycleTime" BO_ 531 10;
BA_ "VFrameFormat" BO_ 531 14;
BA_ "GenMsgCycleTime" BO_ 532 10;
BA_ "VFrameFormat" BO_ 532 14;
BA_ "GenMsgCycleTime" BO_ 560 10;
BA_ "VFrameFormat" BO_ 560 14;
BA_ "GenMsgCycleTime" BO_ 566 20;
BA_ "VFrameFormat" BO_ 566 14;
BA_ "GenMsgCycleTime" BO_ 619 50;
BA_ "VFrameFormat" BO_ 619 14;
BA_ "GenMsgCycleTime" BO_ 834 100;
BA_ "VFrameFormat" BO_ 834 14;
BA_ "GenMsgCycleTime" BO_ 835 100;
BA_ "VFrameFormat" BO_ 835 14;
BA_ "GenMsgCycleTime" BO_ 837 100;
BA_ "VFrameFormat" BO_ 837 14;
BA_ "GenMsgCycleTime" BO_ 838 100;
BA_ "VFrameFormat" BO_ 838 14;
BA_ "GenMsgCycleTime" BO_ 855 100;
BA_ "VFrameFormat" BO_ 855 14;
BA_ "GenMsgCycleTime" BO_ 295 10;
BA_ "VFrameFormat" BO_ 295 14;
BA_ "GenMsgCycleTime" BO_ 1387 100;
BA_ "VFrameFormat" BO_ 1387 14;
BA_ "GenMsgCycleTime" BO_ 513 20;
BA_ "VFrameFormat" BO_ 513 14;
BA_ "GenMsgCycleTime" BO_ 535 20;
BA_ "VFrameFormat" BO_ 535 14;
BA_ "GenMsgCycleTime" BO_ 536 10;
BA_ "VFrameFormat" BO_ 536 14;
BA_ "GenMsgCycleTime" BO_ 276 10;
BA_ "VFrameFormat" BO_ 276 14;
BA_ "GenMsgCycleTime" BO_ 277 10;
BA_ "VFrameFormat" BO_ 277 14;
BA_ "GenMsgCycleTime" BO_ 533 20;
BA_ "VFrameFormat" BO_ 533 14;
BA_ "GenMsgNrOfRepetition" BO_ 1404 40;
BA_ "GenMsgCycleTimeFast" BO_ 1404 100;
BA_ "GenMsgSendType" BO_ 1404 1;
BA_ "VFrameFormat" BO_ 1404 14;
BA_ "GenMsgCycleTime" BO_ 1268 100;
BA_ "VFrameFormat" BO_ 1268 14;
BA_ "GenMsgCycleTime" BO_ 753 50;
BA_ "VFrameFormat" BO_ 753 14;
BA_ "GenMsgCycleTime" BO_ 1361 100;
BA_ "VFrameFormat" BO_ 1361 14;
BA_ "GenMsgCycleTime" BO_ 389 20;
BA_ "VFrameFormat" BO_ 389 14;
BA_ "GenMsgCycleTime" BO_ 433 20;
BA_ "VFrameFormat" BO_ 433 14;
BA_ "GenMsgCycleTime" BO_ 281 10;
BA_ "VFrameFormat" BO_ 281 14;
BA_ "GenMsgCycleTime" BO_ 304 20;
BA_ "VFrameFormat" BO_ 304 14;
BA_ "GenMsgCycleTime" BO_ 822 100;
BA_ "VFrameFormat" BO_ 822 14;
BA_ "GenMsgCycleTime" BO_ 305 100;
BA_ "VFrameFormat" BO_ 305 14;
BA_ "GenMsgCycleTime" BO_ 998 50;
BA_ "VFrameFormat" BO_ 998 14;
BA_ "sigSecLevel" SG_ 1025 BMSFlNodeId "";
BA_ "sigSecLevel" SG_ 1025 BMSFlPni "";
BA_ "GenSigStartValue" SG_ 1025 BMSFlPni 1;
BA_ "sigSecLevel" SG_ 1025 BMSFlAwb "";
BA_ "sigSecLevel" SG_ 1025 BMSFlRmr "";
BA_ "sigSecLevel" SG_ 1025 BMSFlWus "";
BA_ "sigSecLevel" SG_ 1025 BMSFlNmSts "";
BA_ "sigSecLevel" SG_ 1046 GWEvbusFlNodeId "";
BA_ "sigSecLevel" SG_ 1046 GWEvbusFlPni "";
BA_ "GenSigStartValue" SG_ 1046 GWEvbusFlPni 1;
BA_ "sigSecLevel" SG_ 1046 GWEvbusFlAwb "";
BA_ "sigSecLevel" SG_ 1046 GWEvbusFlRmr "";
BA_ "sigSecLevel" SG_ 1046 GWEvbusFlWus "";
BA_ "sigSecLevel" SG_ 1046 GWEvbusFlNmSts "";
BA_ "sigSecLevel" SG_ 1026 MCUFlNodeId "";
BA_ "sigSecLevel" SG_ 1026 MCUFlPni "";
BA_ "GenSigStartValue" SG_ 1026 MCUFlPni 1;
BA_ "sigSecLevel" SG_ 1026 MCUFlAwb "";
BA_ "sigSecLevel" SG_ 1026 MCUFlRmr "";
BA_ "sigSecLevel" SG_ 1026 MCUFlWus "";
BA_ "sigSecLevel" SG_ 1026 MCUFlNmSts "";
BA_ "sigSecLevel" SG_ 1059 ACFlNodeId "";
BA_ "sigSecLevel" SG_ 1059 ACFlPni "";
BA_ "GenSigStartValue" SG_ 1059 ACFlPni 1;
BA_ "sigSecLevel" SG_ 1059 ACFlAwb "";
BA_ "sigSecLevel" SG_ 1059 ACFlRmr "";
BA_ "sigSecLevel" SG_ 1059 ACFlWus "";
BA_ "sigSecLevel" SG_ 1059 ACFlNmSts "";
BA_ "sigSecLevel" SG_ 1141 LBMSFlNodeId "";
BA_ "sigSecLevel" SG_ 1141 LBMSFlPni "";
BA_ "GenSigStartValue" SG_ 1141 LBMSFlPni 1;
BA_ "sigSecLevel" SG_ 1141 LBMSFlAwb "";
BA_ "sigSecLevel" SG_ 1141 LBMSFlRmr "";
BA_ "sigSecLevel" SG_ 1141 LBMSFlWus "";
BA_ "sigSecLevel" SG_ 1141 LBMSFlNmSts "";
BA_ "sigSecLevel" SG_ 521 MCU_KL30Vol "";
BA_ "sigSecLevel" SG_ 521 MCU_F_MCUPowerOffCmd "";
BA_ "sigSecLevel" SG_ 521 MCU_F_MCUInitComp_flg "";
BA_ "sigSecLevel" SG_ 521 MCU_DC_CUR "";
BA_ "sigSecLevel" SG_ 521 MCU_PHASE_CUR "";
BA_ "sigSecLevel" SG_ 521 MCU_DC_VOLT "";
BA_ "sigSecLevel" SG_ 296 dmc_dTcsDbgSignal1_M1 "";
BA_ "sigSecLevel" SG_ 296 dmc_TcsDbgSiqnal2_M1 "";
BA_ "sigSecLevel" SG_ 296 dmc_dTcsDbgSignal3_M1 "";
BA_ "sigSecLevel" SG_ 296 dmc_dTcsDbgSignal4_M1 "";
BA_ "sigSecLevel" SG_ 296 dmc_dTcsDbgSignal5_M1 "";
BA_ "sigSecLevel" SG_ 296 DmcFrtDTCSOperaMode "";
BA_ "sigSecLevel" SG_ 296 dmc_dTcsDbgSignal6_M1 "";
BA_ "sigSecLevel" SG_ 296 dmc_dTcsDbgSignal7_M1 "";
BA_ "sigSecLevel" SG_ 296 dmc_dTcsDbgSignal8_M1 "";
BA_ "sigSecLevel" SG_ 296 dmc_dTcsDbgSignal9_M1 "";
BA_ "sigSecLevel" SG_ 296 dmc_drcsDbgSignal10_M1 "";
BA_ "sigSecLevel" SG_ 296 dmc_drcsDbgSignal11_M1 "";
BA_ "sigSecLevel" SG_ 296 dmc_drcsDbgSignal12_M1 "";
BA_ "sigSecLevel" SG_ 296 DmcFrtDTCSTargTorq "";
BA_ "sigSecLevel" SG_ 1152 IPUCPAmp "";
BA_ "sigSecLevel" SG_ 1152 OBC_DCCrt "";
BA_ "sigSecLevel" SG_ 1152 OBC_DCVolt "";
BA_ "sigSecLevel" SG_ 1152 IPUCPDutyRat "";
BA_ "sigExplanation" SG_ 1152 IPUWakupsou "Bitmap,0表示无该唤醒信号，1表示IPU被该唤醒源唤醒Bit0: ReservedBit1: PDCU硬线唤醒Bit2: 网络唤醒Bit3: CP信号唤醒Bit4: CC信号唤醒Bit5~Bit7: 预留";
BA_ "sigSecLevel" SG_ 1152 IPUWakupsou "";
BA_ "sigSecLevel" SG_ 1152 IPUCPDir "";
BA_ "sigSecLevel" SG_ 1152 IPUHeatReqFlg "";
BA_ "sigSecLevel" SG_ 1152 IPUCCR "";
BA_ "sigSecLevel" SG_ 1152 IPUCPFrq "";
BA_ "sigSecLevel" SG_ 1304 DcdcMilReq "";
BA_ "sigSecLevel" SG_ 1304 DCDC_OutpCrt "";
BA_ "sigSecLevel" SG_ 1304 DCDC_InpVolt "";
BA_ "sigSecLevel" SG_ 1304 DCDC_InpCrt "";
BA_ "sigSecLevel" SG_ 1304 DCDC_OutpVolt "";
BA_ "sigSecLevel" SG_ 1313 DCDC_InpOverVoltSwFlt "";
BA_ "sigSecLevel" SG_ 1313 DCDC_InpUnderVoltFlt "";
BA_ "sigSecLevel" SG_ 1313 DCDC_LVOutpOverVoltFlt "";
BA_ "sigSecLevel" SG_ 1313 DCDC_LVOutpUnderVoltFlt "";
BA_ "sigSecLevel" SG_ 1313 PDU_BusoffFlt "";
BA_ "sigSecLevel" SG_ 1313 DCDC_OverTTurnDwnLoadFlt "";
BA_ "sigSecLevel" SG_ 1313 IPU_ComCheckErr "";
BA_ "sigSecLevel" SG_ 1313 DCDC_InpCurOverSwFlt "";
BA_ "sigSecLevel" SG_ 1313 DCDC_OverTShutDwnFlt "";
BA_ "sigSecLevel" SG_ 1313 DCDC_StsAlrmFlt "";
BA_ "sigSecLevel" SG_ 1313 DCDC_CrtStsGB "";
BA_ "GenSigStartValue" SG_ 1313 DCDC_CrtStsGB 2;
BA_ "sigSecLevel" SG_ 1313 DCDC_LVOutpOverCurrFlt "";
BA_ "sigSecLevel" SG_ 1313 IPU_KL30Vol "";
BA_ "sigSecLevel" SG_ 1313 DCDC_St_TMP "";
BA_ "GenSigStartValue" SG_ 1313 DCDC_St_TMP 48;
BA_ "sigSecLevel" SG_ 1313 DCDC_INPUT_VOLT_CHECK_FLT "";
BA_ "sigSecLevel" SG_ 1313 DCDC_OUTPUT_VOLT_CHECK_FLT "";
BA_ "sigSecLevel" SG_ 1313 DCDC_IntFlt "";
BA_ "sigSecLevel" SG_ 1313 DCDC_ComLostFlt_PDCU "";
BA_ "sigSecLevel" SG_ 1313 DCDC_OutpShoCircFlt "";
BA_ "sigSecLevel" SG_ 1313 DCDC_CrtSts "";
BA_ "sigSecLevel" SG_ 1313 BoostCurOverFlt "";
BA_ "sigSecLevel" SG_ 1313 DCDC_T "";
BA_ "GenSigStartValue" SG_ 1313 DCDC_T 40;
BA_ "sigSecLevel" SG_ 1638 PDU_SwVersS "";
BA_ "sigSecLevel" SG_ 1638 PDU_PartVers "";
BA_ "GenSigStartValue" SG_ 1638 PDU_PartVers 1;
BA_ "sigSecLevel" SG_ 1638 PDU_HwVers "";
BA_ "sigSecLevel" SG_ 1638 PDU_SwVersM "";
BA_ "sigSecLevel" SG_ 1746 OBC_HVDCOutpOverCrtHwFlt "";
BA_ "sigSecLevel" SG_ 1746 OBC_HVDCOutpShortFlt "";
BA_ "sigSecLevel" SG_ 1746 PFC_PowFreMOSOverTFlt "";
BA_ "sigSecLevel" SG_ 1746 OBC_ACVoltOverVoltFlt "";
BA_ "sigSecLevel" SG_ 1746 OBC_ACVoltUnderVoltFlt "";
BA_ "sigSecLevel" SG_ 1746 OBC_HVDCOutpOverVoltSwFlt "";
BA_ "sigSecLevel" SG_ 1746 OBC_HVDCOutpUnderVoltFlt "";
BA_ "sigSecLevel" SG_ 1746 OBC_InpCrtOverCrtHwSwFlt "";
BA_ "sigSecLevel" SG_ 1746 PFC_MOSOverTFlt "";
BA_ "sigSecLevel" SG_ 1746 LLC_OriSideMOSOverTFlt "";
BA_ "sigSecLevel" SG_ 1746 OBC_ACPoweroff "";
BA_ "sigSecLevel" SG_ 1746 DiscCPSIGErr "";
BA_ "sigSecLevel" SG_ 1746 OBC_LVOutpOverVoltFlt "";
BA_ "sigSecLevel" SG_ 1746 OBC_LiquidOverTShutDwnFlt "";
BA_ "sigSecLevel" SG_ 1746 OBC_LiquidOverTDwnPwrFlt "";
BA_ "sigSecLevel" SG_ 1746 LLC_SenSideMOSOverTFlt "";
BA_ "sigSecLevel" SG_ 1746 OBC_HVDCOutpOverVoltHwFlt "";
BA_ "sigSecLevel" SG_ 1746 OBC_INVOutpShortFlt "";
BA_ "sigSecLevel" SG_ 1746 OBC_INVOutpOverLoadFlt "";
BA_ "sigSecLevel" SG_ 1746 OBC_PfcCllcSciLost "";
BA_ "sigSecLevel" SG_ 1746 OBC_IntOverTFlt "";
BA_ "sigSecLevel" SG_ 1746 OBC_IntFlt "";
BA_ "sigSecLevel" SG_ 1746 BOBC_OverTFlt "";
BA_ "sigSecLevel" SG_ 1746 PFCBusOverVoltFlt "";
BA_ "sigSecLevel" SG_ 1746 OBC_HVDCOutpOverCrtSwFlt "";
BA_ "sigSecLevel" SG_ 1746 OBC_ACCrtChkCircFlt "";
BA_ "sigSecLevel" SG_ 1746 PFCBusUnderVoltFlt "";
BA_ "sigSecLevel" SG_ 1746 OBC_INVOutpOverVoltFlt "";
BA_ "sigSecLevel" SG_ 1746 OBC_INVOutpUnderVoltFlt "";
BA_ "sigSecLevel" SG_ 1746 OBC_INVInpOverVoltFlt "";
BA_ "sigSecLevel" SG_ 1746 OBC_INVInpUnderVoltFlt "";
BA_ "sigSecLevel" SG_ 1746 OBC_INVOutpOverCurrSlowFlt "";
BA_ "sigSecLevel" SG_ 1746 ACInputPhaTypeFlt "";
BA_ "sigSecLevel" SG_ 1746 CLLCChaStsInpUnderVoltFlt "";
BA_ "sigSecLevel" SG_ 1746 BOBC_CCSIG_ERR "";
BA_ "sigSecLevel" SG_ 1746 BOBC_CPSIG_ERR "";
BA_ "sigSecLevel" SG_ 1746 OBC_LVOutpUnderVoltFlt "";
BA_ "sigSecLevel" SG_ 1746 BOBC_PowOverVoltHwFlt "";
BA_ "sigSecLevel" SG_ 1746 ACFreLowFlt "";
BA_ "sigSecLevel" SG_ 1746 ACFreHighFlt "";
BA_ "sigSecLevel" SG_ 1746 BOBC_BatOverCurrHwFlt "";
BA_ "sigSecLevel" SG_ 1746 OBC_InpCrtOverCrtHwFlt "";
BA_ "sigSecLevel" SG_ 1746 OBC_ACVoltFreqFlt "";
BA_ "sigSecLevel" SG_ 1746 BUSMidVoltFlt "";
BA_ "sigSecLevel" SG_ 1746 OBC_ACSCIntlkSigChkCircFlt "";
BA_ "sigSecLevel" SG_ 1746 OBC_PTCIntlkSigChkCircFlt "";
BA_ "sigSecLevel" SG_ 1746 OBC_PwrBattIntlkSigChkCircFlt "";
BA_ "sigSecLevel" SG_ 1746 OBC_INVCllcBusOverVoltFlt "";
BA_ "sigSecLevel" SG_ 1747 OBC_ACVolt_L1 "";
BA_ "sigSecLevel" SG_ 1747 OBC_T "";
BA_ "GenSigStartValue" SG_ 1747 OBC_T 48;
BA_ "sigSecLevel" SG_ 1747 OBC_ACCrt_L1 "";
BA_ "sigSecLevel" SG_ 1747 OBC_CrtSts "";
BA_ "sigSecLevel" SG_ 1747 PFC_OpenStatus "";
BA_ "sigSecLevel" SG_ 1747 LLC_OpenStatus "";
BA_ "sigSecLevel" SG_ 1748 OBC_VCU_AWAK_POW_STA "";
BA_ "sigSecLevel" SG_ 1748 OBC_ExtDchaSts_Sokt "";
BA_ "sigSecLevel" SG_ 1748 OBC_ExtDchaOutpMaxPwr "";
BA_ "sigSecLevel" SG_ 1748 OBC_MinOutpVolt "";
BA_ "sigSecLevel" SG_ 1748 OBC_MaxOutpVolt "";
BA_ "sigSecLevel" SG_ 1748 OBC_InpVoltRng "";
BA_ "sigSecLevel" SG_ 1748 OBC_Splr "";
BA_ "sigSecLevel" SG_ 1748 OBC_Pwr "";
BA_ "sigSecLevel" SG_ 1748 ObcMilReq "";
BA_ "sigSecLevel" SG_ 1750 OBC_OperMod "";
BA_ "sigSecLevel" SG_ 1750 IPU_TMP_H "";
BA_ "GenSigStartValue" SG_ 1750 IPU_TMP_H 48;
BA_ "sigSecLevel" SG_ 1750 PFC_St_TMP "";
BA_ "GenSigStartValue" SG_ 1750 PFC_St_TMP 48;
BA_ "sigSecLevel" SG_ 1750 LLC_St_TMP "";
BA_ "GenSigStartValue" SG_ 1750 LLC_St_TMP 48;
BA_ "sigSecLevel" SG_ 1750 IPU_OBC_PFC_VBUS "";
BA_ "sigSecLevel" SG_ 1751 OBC_SoktCrtPwr "";
BA_ "sigSecLevel" SG_ 1751 OBC_SoktCrtPwrFlg "";
BA_ "sigSecLevel" SG_ 1751 IPUS2SwtSts "";
BA_ "sigSecLevel" SG_ 1751 IPUS1SwtSts "";
BA_ "sigSecLevel" SG_ 1751 OBC_OutpMaxPwr "";
BA_ "sigSecLevel" SG_ 1324 EWP_FD_Sts "";
BA_ "sigSecLevel" SG_ 1010 OutdT "";
BA_ "sigDespEng" SG_ 1010 OutdT "outside temperature";
BA_ "GenSigStartValue" SG_ 1010 OutdT 120;
BA_ "sigSecLevel" SG_ 1010 OutdTVld "";
BA_ "sigDespEng" SG_ 1010 OutdTVld "Validaty of the outside temperature";
BA_ "GenSigStartValue" SG_ 1010 OutdTVld 1;
BA_ "sigSecLevel" SG_ 1153 VCU_DCDCOutPVoltCmd "";
BA_ "sigSecLevel" SG_ 1153 VCU_DC_EN_CMD "";
BA_ "sigSecLevel" SG_ 1153 VCU_Batt_VOLT "";
BA_ "sigDespEng" SG_ 1153 VCU_Batt_VOLT "混动PDCU不发送";
BA_ "sigSecLevel" SG_ 1156 VCU_SOCKET_PERM_POW_MAX "";
BA_ "sigSecLevel" SG_ 1156 VCU_OBC_CHG_POW_MAX "";
BA_ "sigSecLevel" SG_ 1156 VCU_SOCKET_ENA_CMD "";
BA_ "sigSecLevel" SG_ 1157 VCU_SYS_CONSUME_PWR_MAX "";
BA_ "sigDespEng" SG_ 1157 VCU_SYS_CONSUME_PWR_MAX "混动PDCU不发送";
BA_ "sigSecLevel" SG_ 1157 VCU_ActvDchaEnaFlg "";
BA_ "sigSecLevel" SG_ 1157 CPDirReq "";
BA_ "sigSecLevel" SG_ 1157 DiscCPDutyRatReq "";
BA_ "sigSecLevel" SG_ 1157 VCU_SYS_FEED_PWR_MAX "";
BA_ "sigDespEng" SG_ 1157 VCU_SYS_FEED_PWR_MAX "混动PDCU不发送";
BA_ "sigSecLevel" SG_ 1161 MCU_F_DrvrMot1CrtSts "";
BA_ "GenSigStartValue" SG_ 1161 MCU_F_DrvrMot1CrtSts 1;
BA_ "sigSecLevel" SG_ 1161 FroMcuWorkSta "";
BA_ "sigSecLevel" SG_ 1161 MCU_F_UIGBTTemp0 "";
BA_ "sigSecLevel" SG_ 1161 MCU_EEPROM_STS "";
BA_ "sigSecLevel" SG_ 1161 MCU_F_UIGBTTemp1 "";
BA_ "sigSecLevel" SG_ 1161 MCU_F_VIGBTTemp0 "";
BA_ "sigSecLevel" SG_ 1161 MCU_F_VIGBTTemp1 "";
BA_ "sigSecLevel" SG_ 1161 MCU_F_WIGBTTemp0 "";
BA_ "sigSecLevel" SG_ 1161 MCU_F_WIGBTTemp1 "";
BA_ "sigSecLevel" SG_ 1161 MCU_I2TEnable "";
BA_ "sigSecLevel" SG_ 1162 MotAssHeaSta "";
BA_ "sigSecLevel" SG_ 1162 MCU_BRAKE_TOR_MAX "";
BA_ "sigSecLevel" SG_ 1162 MCU_DRIVE_TOR_MAX "";
BA_ "sigSecLevel" SG_ 1162 MotAssHeaPowAbiVal "";
BA_ "sigSecLevel" SG_ 1162 MotAssHeaPow "";
BA_ "sigSecLevel" SG_ 1163 VCU_BRAKE_ENGERY_RECOV_STA "";
BA_ "sigSecLevel" SG_ 1297 VCU_VehRemRefrshModReq "";
BA_ "sigSecLevel" SG_ 1397 VCU_ExhibitionMode "";
BA_ "sigSecLevel" SG_ 1558 VCU_DRIVE_RANGE "";
BA_ "sigSecLevel" SG_ 1559 VCU_VEH_SPD "";
BA_ "sigSecLevel" SG_ 1574 VCU_ComLostFlt_ESP "";
BA_ "sigDespEng" SG_ 1574 VCU_ComLostFlt_ESP "混动PDCU不发送";
BA_ "sigSecLevel" SG_ 1576 RemSpdTarCmdVld "";
BA_ "sigDespEng" SG_ 1576 RemSpdTarCmdVld "遥控驾驶开启转速环控后，发送目标转速有效位给MCU混动PDCU不发送";
BA_ "sigSecLevel" SG_ 1576 RemMotDampgFobd "";
BA_ "sigDespEng" SG_ 1576 RemMotDampgFobd "遥控驾驶开启转速环控后，发送主动阻尼禁止标志位给MCU混动PDCU不发送";
BA_ "sigSecLevel" SG_ 1576 VCU_VEH_MODE "";
BA_ "sigSecLevel" SG_ 1576 BattVoltAnormStopDiagFlg "";
BA_ "sigDespEng" SG_ 1576 BattVoltAnormStopDiagFlg "混动PDCU不发送";
BA_ "sigSecLevel" SG_ 1576 VCUZeroTorFlg "";
BA_ "sigDespEng" SG_ 1576 VCUZeroTorFlg "混动PDCU不发送";
BA_ "sigSecLevel" SG_ 1576 VCU_TEMOTE_POWER_ON_REQ "";
BA_ "sigDespEng" SG_ 1576 VCU_TEMOTE_POWER_ON_REQ "混动PDCU不发送";
BA_ "sigSecLevel" SG_ 1585 VCU_Socket_SWH_REQ_CMD "";
BA_ "sigSecLevel" SG_ 1588 VCU_ACChrgCrtUpprLmt "";
BA_ "sigSecLevel" SG_ 1599 MCU_CAL_VERS "";
BA_ "sigSecLevel" SG_ 1599 MCU_PART_VERS "";
BA_ "GenSigStartValue" SG_ 1599 MCU_PART_VERS 1;
BA_ "sigSecLevel" SG_ 1599 MCU_HW_VERS "";
BA_ "sigSecLevel" SG_ 1599 MCU_SW_VERS "";
BA_ "sigSecLevel" SG_ 1614 VCU_COLL_SIG_STA "";
BA_ "sigSecLevel" SG_ 1624 MotAssHeaCmd "";
BA_ "sigDespEng" SG_ 1624 MotAssHeaCmd "混动PDCU不发送";
BA_ "sigSecLevel" SG_ 1624 ParkAssHeaPowLimVal "";
BA_ "sigDespEng" SG_ 1624 ParkAssHeaPowLimVal "混动PDCU不发送";
BA_ "sigSecLevel" SG_ 1624 MotAssHeaPowCmd "";
BA_ "sigDespEng" SG_ 1624 MotAssHeaPowCmd "混动PDCU不发送";
BA_ "sigSecLevel" SG_ 1624 MotAssHeaEnaCmd "";
BA_ "sigDespEng" SG_ 1624 MotAssHeaEnaCmd "混动PDCU不发送";
BA_ "sigSecLevel" SG_ 1683 MCU_AngEIPosValue "";
BA_ "sigSecLevel" SG_ 1683 MCU_F_ReadZeroPointErr "";
BA_ "sigSecLevel" SG_ 1683 MCU_F_CheckPoint1Err "";
BA_ "sigSecLevel" SG_ 1683 MCU_F_CheckPoint2Err "";
BA_ "sigSecLevel" SG_ 1683 MCU_F_CheckOverRangeErr "";
BA_ "sigSecLevel" SG_ 1683 MCU_MCU_SUPPLIER "";
BA_ "sigSecLevel" SG_ 1683 MCU_CAL_SW_VER "";
BA_ "sigSecLevel" SG_ 1683 MCU_F_CheckDifferentErr "";
BA_ "sigSecLevel" SG_ 1683 MCU_F_CheckPointinvalidErr "";
BA_ "sigSecLevel" SG_ 1683 McuEgyFbLimSta "";
BA_ "sigSecLevel" SG_ 1683 dmc_dTCS_SWInfo "";
BA_ "sigSecLevel" SG_ 1728 VCU_READY_LAMP "";
BA_ "sigSecLevel" SG_ 1728 VCU_MEN_CHGR_MILG_THD "";
BA_ "sigSecLevel" SG_ 1739 MCU_Motor_SUM "";
BA_ "sigDespEng" SG_ 1739 MCU_Motor_SUM "混动MCUF不发送";
BA_ "sigSecLevel" SG_ 1739 McuMotorNum "";
BA_ "sigSecLevel" SG_ 1739 MCU_MCU_F_SUM "";
BA_ "sigSecLevel" SG_ 1739 McuIgbtTemp "";
BA_ "GenSigStartValue" SG_ 1739 McuIgbtTemp 40;
BA_ "sigSecLevel" SG_ 1739 McuMotSpd "";
BA_ "GenSigStartValue" SG_ 1739 McuMotSpd 20000;
BA_ "sigSecLevel" SG_ 1739 McuMotTemp "";
BA_ "GenSigStartValue" SG_ 1739 McuMotTemp 40;
BA_ "sigSecLevel" SG_ 1739 MCU_F_DrvrMot1CrtSts_GB "";
BA_ "GenSigStartValue" SG_ 1739 MCU_F_DrvrMot1CrtSts_GB 1;
BA_ "sigSecLevel" SG_ 1739 MCU_F_MCUTempAlarmLv1 "";
BA_ "sigDespEng" SG_ 1739 MCU_F_MCUTempAlarmLv1 "国标";
BA_ "sigSecLevel" SG_ 1739 MCU_F_MCUTempAlarmLv2 "";
BA_ "sigDespEng" SG_ 1739 MCU_F_MCUTempAlarmLv2 "国标";
BA_ "sigSecLevel" SG_ 1739 MCU_F_MotTempAlarmLv1 "";
BA_ "sigDespEng" SG_ 1739 MCU_F_MotTempAlarmLv1 "国标";
BA_ "sigSecLevel" SG_ 1739 MCU_F_MotTempAlarmLv2 "";
BA_ "sigDespEng" SG_ 1739 MCU_F_MotTempAlarmLv2 "国标";
BA_ "sigSecLevel" SG_ 1739 MCU_F_OverSpdAlarmLv1 "";
BA_ "sigDespEng" SG_ 1739 MCU_F_OverSpdAlarmLv1 "国标";
BA_ "sigSecLevel" SG_ 1739 MCU_F_OverSpdAlarmLv2 "";
BA_ "sigDespEng" SG_ 1739 MCU_F_OverSpdAlarmLv2 "国标";
BA_ "sigSecLevel" SG_ 1739 MCU_F_OverCurAlarmLv1 "";
BA_ "sigDespEng" SG_ 1739 MCU_F_OverCurAlarmLv1 "国标";
BA_ "sigSecLevel" SG_ 1739 MCU_F_OverCurAlarmLv2 "";
BA_ "sigDespEng" SG_ 1739 MCU_F_OverCurAlarmLv2 "国标";
BA_ "sigSecLevel" SG_ 1739 MCU_F_OverCurAlarmLv3 "";
BA_ "sigDespEng" SG_ 1739 MCU_F_OverCurAlarmLv3 "国标";
BA_ "sigSecLevel" SG_ 1739 McuMotTor "";
BA_ "GenSigStartValue" SG_ 1739 McuMotTor 20000;
BA_ "sigSecLevel" SG_ 1739 McuDcCur "";
BA_ "GenSigStartValue" SG_ 1739 McuDcCur 10000;
BA_ "sigSecLevel" SG_ 1739 McuDcVolt "";
BA_ "sigSecLevel" SG_ 1740 MCU_MotCode1 "";
BA_ "sigSecLevel" SG_ 1741 MCU_MotCode2 "";
BA_ "sigSecLevel" SG_ 1742 MCU_MotCode3 "";
BA_ "sigSecLevel" SG_ 1743 MCU_MotCode4 "";
BA_ "sigSecLevel" SG_ 512 VCUSpeedLimTypRq "";
BA_ "sigSecLevel" SG_ 534 MCU_216_CheckSum "";
BA_ "sigDespEng" SG_ 534 MCU_216_CheckSum "CRC checksum. DataID and the following 7 bytes are included in CRC checksum calculation. Refer to E2E Spec.（Profile：1A；DataID：0x0079）";
BA_ "sigSecLevel" SG_ 534 MCU_216_AliveCounter "";
BA_ "sigDespEng" SG_ 534 MCU_216_AliveCounter "Rolling counter. Refer to E2E Spec.";
BA_ "sigSecLevel" SG_ 534 MCU_MOT_ActiveDamping_Flg "";
BA_ "sigDespEng" SG_ 534 MCU_MOT_ActiveDamping_Flg "HDCU不发送";
BA_ "sigSecLevel" SG_ 534 MCU_MOT_DIR_CMD "";
BA_ "sigSecLevel" SG_ 534 MCU_MOT_SPD "";
BA_ "sigSecLevel" SG_ 534 MCU_MOT_TOR "";
BA_ "sigSecLevel" SG_ 534 MCU_TOR_QUA_AFC "";
BA_ "sigSecLevel" SG_ 534 MCU_MOT_INIT "";
BA_ "sigDespEng" SG_ 534 MCU_MOT_INIT "HDCU不发送";
BA_ "sigSecLevel" SG_ 534 MCU_SPD_QUA_AFC "";
BA_ "sigSecLevel" SG_ 534 MCU_HV_CHECK_FLAG "";
BA_ "sigDespEng" SG_ 534 MCU_HV_CHECK_FLAG "HDCU不发送";
BA_ "sigSecLevel" SG_ 534 MCU_HV_DISOBC_STA "";
BA_ "sigDespEng" SG_ 534 MCU_HV_DISOBC_STA "HDCU不发送";
BA_ "sigSecLevel" SG_ 534 MCU_LV_OFF_REQ_FLAG "";
BA_ "sigDespEng" SG_ 534 MCU_LV_OFF_REQ_FLAG "HDCU不发送";
BA_ "sigSecLevel" SG_ 534 MCU_MOT_STA "";
BA_ "sigSecLevel" SG_ 534 MCU_MOT_MODE "";
BA_ "sigDespEng" SG_ 534 MCU_MOT_MODE "HDCU不发送";
BA_ "sigSecLevel" SG_ 528 VCU_DRV_APS_PER_FLG "";
BA_ "sigSecLevel" SG_ 528 VCU_DRV_APS_PER "";
BA_ "sigDespEng" SG_ 528 VCU_DRV_APS_PER "A0项目MCU接收此信号";
BA_ "sigSecLevel" SG_ 528 VCU_BRAKE_STA "";
BA_ "sigSecLevel" SG_ 531 VCU_213_CheckSum "";
BA_ "sigDespEng" SG_ 531 VCU_213_CheckSum "CRC checksum. DataID and the following 7 bytes are included in CRC checksum calculation. Refer to E2E Spec.（Profile：1A；DataID：0x00D3）混动PDCU不发送";
BA_ "sigSecLevel" SG_ 531 VCU_213_AliveCounter "";
BA_ "sigDespEng" SG_ 531 VCU_213_AliveCounter "Rolling counter. Refer to E2E Spec.混动PDCU不发送";
BA_ "sigSecLevel" SG_ 531 VCU_MOT_SPD_CMD "";
BA_ "sigDespEng" SG_ 531 VCU_MOT_SPD_CMD "混动PDCU不发送";
BA_ "sigSecLevel" SG_ 531 VCU_MOT_MODE_CMD "";
BA_ "sigDespEng" SG_ 531 VCU_MOT_MODE_CMD "混动PDCU不发送";
BA_ "sigSecLevel" SG_ 531 VCU_DTCRecoverRequest_BE12 "";
BA_ "sigDespEng" SG_ 531 VCU_DTCRecoverRequest_BE12 "混动PDCU不发送";
BA_ "sigSecLevel" SG_ 531 VCU_MCU_ENABLE_CMD "";
BA_ "sigDespEng" SG_ 531 VCU_MCU_ENABLE_CMD "混动PDCU不发送";
BA_ "sigSecLevel" SG_ 532 VCU_214_CheckSum "";
BA_ "sigDespEng" SG_ 532 VCU_214_CheckSum "CRC checksum. DataID and the following 7 bytes are included in CRC checksum calculation. Refer to E2E Spec.（Profile：1A；DataID：0x00D4）";
BA_ "sigSecLevel" SG_ 532 VCU_214_AliveCounter "";
BA_ "sigDespEng" SG_ 532 VCU_214_AliveCounter "Rolling counter. Refer to E2E Spec.";
BA_ "sigSecLevel" SG_ 532 VCU_ON_WAKEUP "";
BA_ "sigSecLevel" SG_ 532 VCU_VEH_STATE "";
BA_ "sigSecLevel" SG_ 560 VCU_230_CheckSum "";
BA_ "sigDespEng" SG_ 560 VCU_230_CheckSum "CRC checksum. DataID and the following 7 bytes are included in CRC checksum calculation. Refer to E2E Spec.（Profile：1A；DataID：0x0055）";
BA_ "sigSecLevel" SG_ 560 VCU_230_AliveCounter "";
BA_ "sigDespEng" SG_ 560 VCU_230_AliveCounter "Rolling counter. Refer to E2E Spec.";
BA_ "sigSecLevel" SG_ 560 VCU_STRATEGY_SHIFT_POSITION "";
BA_ "sigSecLevel" SG_ 560 VCU_GearShiftInternal "";
BA_ "sigSecLevel" SG_ 560 VCU_STRATEGY_SHIFT_POSN_FLAG "";
BA_ "sigSecLevel" SG_ 566 VCU_ChrgDchaGunCnctnSts "";
BA_ "sigSecLevel" SG_ 566 VCU_S2SwtSts "";
BA_ "sigSecLevel" SG_ 619 MCU_STS_MNGT_STS "";
BA_ "sigSecLevel" SG_ 619 MCU_STS_MNGT_OUPT_TRQ "";
BA_ "sigSecLevel" SG_ 619 MCU_TRQ_MNGT_OUPT_TRQ "";
BA_ "sigSecLevel" SG_ 834 VCU_ADA_SLIDE_REQ_FLG "";
BA_ "sigSecLevel" SG_ 834 VCU_ENERY_CONSUM_AVE "";
BA_ "sigSecLevel" SG_ 835 MCU_F_KL15ON_flg "";
BA_ "sigSecLevel" SG_ 835 MCU_REQ_VCU_FLG "";
BA_ "sigSecLevel" SG_ 835 MCU_MOT_TEMP "";
BA_ "GenSigStartValue" SG_ 835 MCU_MOT_TEMP 48;
BA_ "sigSecLevel" SG_ 835 MCUFLaultLevel "";
BA_ "sigSecLevel" SG_ 835 MCU_IGBT_TEMP "";
BA_ "GenSigStartValue" SG_ 835 MCU_IGBT_TEMP 48;
BA_ "sigSecLevel" SG_ 835 MCU_CLOSE_ENA_FKG "";
BA_ "sigSecLevel" SG_ 835 MCU_ZERO_TOQ_FLG "";
BA_ "sigSecLevel" SG_ 835 MCU_MOT_FAULT_LAMP "";
BA_ "sigSecLevel" SG_ 835 MCU_ALARM_LEVEL_MAX "";
BA_ "sigSecLevel" SG_ 837 MCU_DC_SEN_DRIFT "";
BA_ "sigSecLevel" SG_ 837 MCU_CUR_SAMP_CIR_U "";
BA_ "sigSecLevel" SG_ 837 MCU_CUR_SAMP_CIR_V "";
BA_ "sigSecLevel" SG_ 837 MCU_CUR_SAMP_CIR_W "";
BA_ "sigSecLevel" SG_ 837 MCU_DC_SAMP_CUR "";
BA_ "sigSecLevel" SG_ 837 MCU_3PHASE_CUR_CHE_FAULT "";
BA_ "sigSecLevel" SG_ 837 MCU_BUSBAR_VOLT_LOW "";
BA_ "sigSecLevel" SG_ 837 MCU_BUSBAR_VOLT_HIGH "";
BA_ "sigSecLevel" SG_ 837 MCU_BUS_VOLIT_SAMP_FAULT "";
BA_ "sigSecLevel" SG_ 837 MCU_OVER_SPD_FAULT "";
BA_ "sigSecLevel" SG_ 837 MCU_IGBT_TEMP_OVER_U "";
BA_ "sigSecLevel" SG_ 837 MCU_IGBT_TEMP_OVER_V "";
BA_ "sigSecLevel" SG_ 837 MCU_IGBT_TEMP_OVER_W "";
BA_ "sigSecLevel" SG_ 837 MCU_IGBT_TEMP_CHECK_CUR_U "";
BA_ "sigSecLevel" SG_ 837 MCU_IGBT_TEMP_CHECK_CUR_V "";
BA_ "sigSecLevel" SG_ 837 MCU_IGBT_TEMP_CHECK_CUR_W "";
BA_ "sigSecLevel" SG_ 837 MCU_MOTOR_TEMP_OVER "";
BA_ "sigSecLevel" SG_ 837 MCU_MOT_TEMP_CHECK_CUR "";
BA_ "sigSecLevel" SG_ 837 MCU_MCU_TEMP_OVER "";
BA_ "sigSecLevel" SG_ 837 MCUPowOnIniFlt "";
BA_ "sigSecLevel" SG_ 837 MCU_BATT_VOLT_LOW "";
BA_ "sigSecLevel" SG_ 837 MCU_BATT_VOLT_HIGH "";
BA_ "sigSecLevel" SG_ 837 MCU_F_PosZeroErr "";
BA_ "sigSecLevel" SG_ 837 MCU_HW_CUR_HIGH_W "";
BA_ "sigSecLevel" SG_ 837 MCU_FEED_TOR_ORDER_CHE_FAULT "";
BA_ "sigSecLevel" SG_ 837 MCU_HL_VOLT_INTERLOCK_FAULT "";
BA_ "sigSecLevel" SG_ 837 MCU_SW_CUR_HIGH "";
BA_ "sigSecLevel" SG_ 837 MCU_HW_CUR_HIGH_U "";
BA_ "sigSecLevel" SG_ 837 MCU_HW_CUR_HIGH_V "";
BA_ "sigSecLevel" SG_ 837 MCU_EAS_HL_INTERLOCK_FAULT "";
BA_ "sigSecLevel" SG_ 837 MCU_PTC_HL_INTERLOCK_FAULT "";
BA_ "sigSecLevel" SG_ 837 MCU_BATT_HL_INTERLOCK_FAULT "";
BA_ "sigSecLevel" SG_ 837 MCU_MC_HL_INTERLOCK_FAULT "";
BA_ "sigSecLevel" SG_ 837 MCU_QC_HL_INTERLOCK_FAULT "";
BA_ "sigSecLevel" SG_ 838 MCU_COM_VCU_LOSE "";
BA_ "sigSecLevel" SG_ 838 McuActDchFlt "";
BA_ "sigSecLevel" SG_ 838 McuSafStaCheFlt "";
BA_ "sigSecLevel" SG_ 838 McuDcCurHighFlt "";
BA_ "sigSecLevel" SG_ 838 Mot3PhaLoseFlt "";
BA_ "sigSecLevel" SG_ 838 McuMstChipFlt "";
BA_ "sigSecLevel" SG_ 838 IGBT3PhaseTChecFlt "";
BA_ "sigSecLevel" SG_ 838 McuIntComFlt "";
BA_ "sigSecLevel" SG_ 838 IntTorChecFlt "";
BA_ "sigSecLevel" SG_ 838 RunModFlt "";
BA_ "sigSecLevel" SG_ 838 MCU_IGBI_UPPR_BRDG_FLT_U "";
BA_ "sigSecLevel" SG_ 838 MCU_IGBI_LOWR_BRDG_FLT_U "";
BA_ "sigSecLevel" SG_ 838 MCU_IGBI_UPPR_BRDG_FLT_V "";
BA_ "sigSecLevel" SG_ 838 MCU_IGBI_LOWR_BRDG_FLT_V "";
BA_ "sigSecLevel" SG_ 838 MCU_IGBI_UPPR_BRDG_FLT_W "";
BA_ "sigSecLevel" SG_ 838 MCU_IGBI_LOWR_BRDG_FLT_W "";
BA_ "sigSecLevel" SG_ 838 MCU_WAKE_SIG_FLT "";
BA_ "sigSecLevel" SG_ 838 McuSwCurHighU "";
BA_ "sigSecLevel" SG_ 838 McuSwCurHighV "";
BA_ "sigSecLevel" SG_ 838 McuSwCurHighW "";
BA_ "sigSecLevel" SG_ 838 McuBattModFlt "";
BA_ "sigSecLevel" SG_ 838 McuConTempCheckCurFlt "";
BA_ "sigSecLevel" SG_ 838 McuPosCheckCurFlt "";
BA_ "sigSecLevel" SG_ 838 MCU_E2E_ERR "";
BA_ "sigSecLevel" SG_ 855 VCU_OTAClsChrgCmd "";
BA_ "sigSecLevel" SG_ 295 McuApsPer "";
BA_ "sigDespEng" SG_ 295 McuApsPer "A0项目中MCU接收此信号";
BA_ "sigSecLevel" SG_ 295 McuApsPerFlag "";
BA_ "sigDespEng" SG_ 295 McuApsPerFlag "A0项目中MCU接收此信号";
BA_ "sigSecLevel" SG_ 295 McuMotDampgFobdFlg "";
BA_ "sigDespEng" SG_ 295 McuMotDampgFobdFlg "A0项目中MCU接收此信号混动PDCU不发送";
BA_ "sigSecLevel" SG_ 295 McuMotTorCmd "";
BA_ "sigDespEng" SG_ 295 McuMotTorCmd "A0项目中MCU接收此信号";
BA_ "sigSecLevel" SG_ 295 DrvTorReq "";
BA_ "sigDespEng" SG_ 295 DrvTorReq "A0项目中MCU接收此信号";
BA_ "sigSecLevel" SG_ 295 DrvTorReqFlg "";
BA_ "sigDespEng" SG_ 295 DrvTorReqFlg "A0项目中MCU接收此信号";
BA_ "sigSecLevel" SG_ 1387 BMS_CELL_TEMP_MIN "";
BA_ "GenSigStartValue" SG_ 1387 BMS_CELL_TEMP_MIN 48;
BA_ "sigSecLevel" SG_ 513 BMS_OBC_VOLT_OUT_CMD "";
BA_ "sigSecLevel" SG_ 513 BMS_OBC_CUR_RQ "";
BA_ "sigSecLevel" SG_ 513 BMS_OBC_CMD "";
BA_ "sigSecLevel" SG_ 513 BMS_S2_SW_CMD "";
BA_ "sigSecLevel" SG_ 513 BMS_S1_SWT_CMD "";
BA_ "sigSecLevel" SG_ 513 BMS_VEH_MODE "";
BA_ "sigSecLevel" SG_ 535 BMS_DISOBC_MAX_PWR "";
BA_ "sigSecLevel" SG_ 535 BMS_BATT_SOC "";
BA_ "sigSecLevel" SG_ 535 BMS_SELF_CHECK_COUNTER "";
BA_ "sigSecLevel" SG_ 535 BMS_BATTSocReal "";
BA_ "sigSecLevel" SG_ 535 BMS_PwrBattRmngCpSOCHiAccuracy "";
BA_ "sigSecLevel" SG_ 536 BMS_BATT_CUR "";
BA_ "GenSigStartValue" SG_ 536 BMS_BATT_CUR 25000;
BA_ "sigSecLevel" SG_ 276 VCUVehFaultLevel "";
BA_ "sigSecLevel" SG_ 276 AccelModCoeDex "";
BA_ "sigSecLevel" SG_ 276 WheelPreTor "";
BA_ "sigSecLevel" SG_ 276 BrakTorDex "";
BA_ "sigSecLevel" SG_ 276 WormEnaFlg "";
BA_ "sigSecLevel" SG_ 276 DrivSysActFlg "";
BA_ "sigSecLevel" SG_ 276 ABSActFlg "";
BA_ "sigSecLevel" SG_ 276 CRBSActFlg "";
BA_ "sigSecLevel" SG_ 276 WormTorDex "";
BA_ "sigSecLevel" SG_ 276 TorFilSta "";
BA_ "sigSecLevel" SG_ 276 ACCActFlg "";
BA_ "sigSecLevel" SG_ 276 TorEnaFlg "";
BA_ "sigSecLevel" SG_ 276 BmsEngRecForbFlg "";
BA_ "sigSecLevel" SG_ 276 WheelHubMod "";
BA_ "sigSecLevel" SG_ 276 EneRecGraDex "";
BA_ "sigSecLevel" SG_ 276 FronWheTorRq "";
BA_ "sigSecLevel" SG_ 276 TransRat "";
BA_ "sigSecLevel" SG_ 276 TransEffic "";
BA_ "sigSecLevel" SG_ 276 BrakPedTra "";
BA_ "sigSecLevel" SG_ 276 SpeedLimFlg "";
BA_ "sigSecLevel" SG_ 276 DrivAntiSliSwt "";
BA_ "sigSecLevel" SG_ 276 RecAntiSliSwt "";
BA_ "sigSecLevel" SG_ 276 AbsArbSwt "";
BA_ "sigSecLevel" SG_ 276 TcsArbSwt "";
BA_ "sigSecLevel" SG_ 276 DtcArbSwt "";
BA_ "sigSecLevel" SG_ 277 FroMotTorRisGrad "";
BA_ "sigDespEng" SG_ 277 FroMotTorRisGrad "混动PDCU不发送";
BA_ "sigSecLevel" SG_ 277 McuAlrmLampFS "";
BA_ "sigDespEng" SG_ 277 McuAlrmLampFS "混动PDCU不发送";
BA_ "sigSecLevel" SG_ 277 McuMotArbTor "";
BA_ "sigDespEng" SG_ 277 McuMotArbTor "混动PDCU不发送";
BA_ "GenSigStartValue" SG_ 277 McuMotArbTor 65535;
BA_ "sigSecLevel" SG_ 277 FrOnEspTorArbSta "";
BA_ "sigDespEng" SG_ 277 FrOnEspTorArbSta "混动PDCU不发送";
BA_ "sigSecLevel" SG_ 277 McuMotWheelTor "";
BA_ "sigSecLevel" SG_ 277 McuMotWheelTorValid "";
BA_ "sigSecLevel" SG_ 277 RatRedDex "";
BA_ "sigDespEng" SG_ 277 RatRedDex "混动PDCU不发送";
BA_ "sigSecLevel" SG_ 533 MCU_F_DCurrent_Cmd "";
BA_ "sigSecLevel" SG_ 533 MCU_F_DCurrent_Fb "";
BA_ "sigSecLevel" SG_ 533 MCU_F_QCurrent_Cmd "";
BA_ "sigSecLevel" SG_ 533 MCU_F_QCurrent_Fb "";
BA_ "sigSecLevel" SG_ 533 MCU_F_Volt_Percent "";
BA_ "sigSecLevel" SG_ 533 MCU_F_Ang_Delta "";
BA_ "sigSecLevel" SG_ 533 MCU_F_MotSpdFilteredLow "";
BA_ "sigSecLevel" SG_ 533 MCU_F_F_CrtTq_act "";
BA_ "sigSecLevel" SG_ 1404 VCU_FactryCod1 "";
BA_ "GenSigSendType" SG_ 1404 VCU_FactryCod1 4;
BA_ "sigSecLevel" SG_ 1404 VCU_FactryCod2 "";
BA_ "GenSigSendType" SG_ 1404 VCU_FactryCod2 4;
BA_ "sigSecLevel" SG_ 1404 VCU_VehPileRndCod1 "";
BA_ "GenSigSendType" SG_ 1404 VCU_VehPileRndCod1 4;
BA_ "sigSecLevel" SG_ 1404 VCU_VehPileRndCod2 "";
BA_ "GenSigSendType" SG_ 1404 VCU_VehPileRndCod2 4;
BA_ "sigSecLevel" SG_ 1404 VCU_VehPileRndCod3 "";
BA_ "GenSigSendType" SG_ 1404 VCU_VehPileRndCod3 4;
BA_ "sigSecLevel" SG_ 1404 VCU_VehPileRndCod4 "";
BA_ "GenSigSendType" SG_ 1404 VCU_VehPileRndCod4 4;
BA_ "sigSecLevel" SG_ 1404 VCU_VehPileRndCod5 "";
BA_ "GenSigSendType" SG_ 1404 VCU_VehPileRndCod5 4;
BA_ "sigSecLevel" SG_ 1268 OTAHVPwrMod "";
BA_ "sigSecLevel" SG_ 753 TrOpenStsSwt "";
BA_ "sigDespEng" SG_ 753 TrOpenStsSwt "Status of trunk open switch";
BA_ "sigSecLevel" SG_ 753 DrvrDoorOpenStsSwt "";
BA_ "sigDespEng" SG_ 753 DrvrDoorOpenStsSwt "Status of driver door open switch";
BA_ "sigSecLevel" SG_ 753 PassDoorOpenStsSwt "";
BA_ "sigDespEng" SG_ 753 PassDoorOpenStsSwt "Status of passenger door open switch";
BA_ "sigSecLevel" SG_ 753 ReLeDoorOpenStsSwt "";
BA_ "sigDespEng" SG_ 753 ReLeDoorOpenStsSwt "Status of rear left door open switch";
BA_ "sigSecLevel" SG_ 753 ReRiDoorOpenStsSwt "";
BA_ "sigDespEng" SG_ 753 ReRiDoorOpenStsSwt "Status of rear right door open switch";
BA_ "sigSecLevel" SG_ 753 HoodLidOpenStsSwt "";
BA_ "sigDespEng" SG_ 753 HoodLidOpenStsSwt "Status of hood lid open switch";
BA_ "sigSecLevel" SG_ 753 BdcVehMod "";
BA_ "sigDespEng" SG_ 753 BdcVehMod "BDC Vehicle mode";
BA_ "sigSecLevel" SG_ 1361 TBOX_CrtTi_Day "";
BA_ "sigSecLevel" SG_ 1361 TBOX_CrtTi_Hr "";
BA_ "sigSecLevel" SG_ 1361 TBOX_CrtTi_Mins "";
BA_ "sigSecLevel" SG_ 1361 TBOX_CrtTi_Yr "";
BA_ "sigSecLevel" SG_ 1361 TBOX_CrtTi_Mth "";
BA_ "sigSecLevel" SG_ 1361 TBOX_CrtTi_Sec "";
BA_ "sigSecLevel" SG_ 389 FrntRiWhlSpd "";
BA_ "sigDespEng" SG_ 389 FrntRiWhlSpd "Front right wheel speed. Wheel speed of the front right wheel.";
BA_ "sigSecLevel" SG_ 389 FrntRiWhlSpdVld "";
BA_ "sigDespEng" SG_ 389 FrntRiWhlSpdVld "Front right wheel speed valid. Validty of front right wheel speed'.轮速由invalid恢复valid前，需一段车辆动态校验的过程或者故障码被清除。";
BA_ "sigSecLevel" SG_ 389 FrntLeWhlSpd "";
BA_ "sigDespEng" SG_ 389 FrntLeWhlSpd "Front left wheel speed. Wheel speed of the front left wheel.";
BA_ "sigSecLevel" SG_ 389 FrntLeWhlSpdVld "";
BA_ "sigDespEng" SG_ 389 FrntLeWhlSpdVld "Front left wheel speed valid. Validty of front left wheel speed.轮速由invalid恢复valid前，需一段车辆动态校验的过程或者故障码被清除。";
BA_ "sigSecLevel" SG_ 389 ReRiWhlSpd "";
BA_ "sigDespEng" SG_ 389 ReRiWhlSpd "Rear right sheel speed. Wheel speed of the rear right wheel.";
BA_ "sigSecLevel" SG_ 389 ReRiWhlSpdVld "";
BA_ "sigDespEng" SG_ 389 ReRiWhlSpdVld "Rear right wheel speed valid. Validty of rear right wheel speed.轮速由invalid恢复valid前，需一段车辆动态校验的过程或者故障码被清除。";
BA_ "sigSecLevel" SG_ 389 ReLeWhlSpd "";
BA_ "sigDespEng" SG_ 389 ReLeWhlSpd "Rear left wheel speed. Wheel speed of the rear left wheel.";
BA_ "sigSecLevel" SG_ 389 ReLeWhlSpdVld "";
BA_ "sigDespEng" SG_ 389 ReLeWhlSpdVld "Rear left wheel speed valid. Validty of rear left wheel speed.轮速由invalid恢复valid前，需一段车辆动态校验的过程或者故障码被清除。";
BA_ "sigSecLevel" SG_ 389 VehStop "";
BA_ "sigDespEng" SG_ 389 VehStop "Vehicle stop. Indicating whether the vehicle is standstill or not,must not be set until standstill is surely reached.0x2:invalid (short unavailability, max 3s)";
BA_ "sigSecLevel" SG_ 389 VehSpdVld "";
BA_ "sigDespEng" SG_ 389 VehSpdVld "Vehicle speed valid. Validty of the vehicle speed.";
BA_ "sigSecLevel" SG_ 389 VehSpd "";
BA_ "sigDespEng" SG_ 389 VehSpd "不考虑车轮方向，采用两驱动轮算术平均值计算，在车轮腾空、打滑等工况，车速不准确，接收节点需评估后接收。";
BA_ "sigSecLevel" SG_ 433 PwrMod "";
BA_ "sigDespEng" SG_ 433 PwrMod "Vehicle power mode collected by BDC";
BA_ "sigSecLevel" SG_ 433 PwrModVld "";
BA_ "sigDespEng" SG_ 433 PwrModVld "Vehicle power mdoe validityThis signal indicates if power mode signal is valid or not";
BA_ "sigSecLevel" SG_ 281 EGSMFltSts "";
BA_ "sigDespEng" SG_ 281 EGSMFltSts "EGSM_FAULT_STATUS电子档把故障状态EGSM Fault Status.";
BA_ "sigSecLevel" SG_ 281 EGSMGearLvrCrtPosnInfo "";
BA_ "sigDespEng" SG_ 304 ActEngSpdUnfil "Actual engine speed unfiltered.Updated every combustion. The engine speed is cleared after the engine is stopped.";
BA_ "sigSecLevel" SG_ 304 EmsAbsltAccrPedlPosn "";
BA_ "sigSecLevel" SG_ 822 BleStopEng "";
BA_ "sigDespEng" SG_ 822 BleStopEng "Bluetooth stop engine Send this command 6 times to BDC for Bluetooth stopping";
BA_ "GenSigSendType" SG_ 822 BleStopEng 4;
BA_ "sigSecLevel" SG_ 822 BleStrtEng "";
BA_ "sigDespEng" SG_ 822 BleStrtEng "Bluetooth start engineSend this command 6 times to BDC for remote starting";
BA_ "GenSigSendType" SG_ 822 BleStrtEng 4;
BA_ "sigSecLevel" SG_ 822 RemCtrlDrvgReq "";
BA_ "sigSecLevel" SG_ 822 BleCarCtrlAPPHertbtSig "";
BA_ "sigSecLevel" SG_ 822 BleChildTeasSouSta "";
BA_ "sigSecLevel" SG_ 305 EmsEngWrmUpAch "";
BA_ "sigSecLevel" SG_ 305 EmsCooltT "";
BA_ "sigDespEng" SG_ 305 EmsCooltT "Coolant temperature.Engine coolant temperature";
BA_ "sigSecLevel" SG_ 998 EmsDrvgCyc "";
VAL_ 1025 BMSFlPni 1 "NM PDU contains PNI request" 0 "NM PDU contains no PNI request" ;
VAL_ 1025 BMSFlAwb 1 "Active Wakeup" 0 "Passive Wakeup" ;
VAL_ 1025 BMSFlRmr 1 "RMS requested" 0 "RMS not requested" ;
VAL_ 1025 BMSFlWus 255 "Reserved" 254 "Reserved" 253 "Reserved" 252 "Reserved" 251 "Reserved" 250 "Reserved" 249 "Reserved" 248 "Reserved" 247 "Reserved" 246 "Reserved" 245 "Reserved" 244 "Reserved" 243 "Reserved" 242 "Reserved" 241 "Reserved" 240 "Reserved" 239 "Reserved" 238 "Reserved" 237 "Reserved" 236 "Reserved" 235 "Reserved" 234 "Reserved" 233 "Reserved" 232 "Reserved" 231 "Reserved" 230 "Reserved" 229 "Reserved" 228 "Reserved" 227 "Reserved" 226 "Reserved" 225 "Reserved" 224 "Reserved" 223 "Reserved" 222 "Reserved" 221 "Reserved" 220 "Reserved" 219 "Reserved" 218 "Reserved" 217 "Reserved" 216 "Reserved" 215 "Reserved" 214 "Reserved" 213 "Reserved" 212 "Reserved" 211 "Reserved" 210 "Reserved" 209 "Reserved" 208 "Reserved" 207 "Reserved" 206 "Reserved" 205 "Reserved" 204 "Reserved" 203 "Reserved" 202 "Reserved" 201 "Reserved" 200 "Reserved" 199 "Reserved" 198 "Reserved" 197 "Reserved" 196 "Reserved" 195 "Reserved" 194 "Reserved" 193 "Reserved" 192 "Reserved" 191 "Reserved" 190 "Reserved" 189 "Reserved" 188 "Reserved" 187 "Reserved" 186 "Reserved" 185 "Reserved" 184 "Reserved" 183 "Reserved" 182 "Reserved" 181 "Reserved" 180 "Reserved" 179 "Reserved" 178 "Reserved" 177 "Reserved" 176 "Reserved" 175 "Reserved" 174 "Reserved" 173 "Reserved" 172 "Reserved" 171 "Reserved" 170 "Reserved" 169 "Reserved" 168 "Reserved" 167 "Reserved" 166 "Reserved" 165 "Reserved" 164 "Reserved" 163 "Reserved" 162 "Reserved" 161 "Reserved" 160 "Reserved" 159 "Reserved" 158 "Reserved" 157 "Reserved" 156 "Reserved" 155 "Reserved" 154 "Reserved" 153 "Reserved" 152 "Reserved" 151 "Reserved" 150 "Reserved" 149 "Reserved" 148 "Reserved" 147 "Reserved" 146 "Reserved" 145 "Reserved" 144 "Reserved" 143 "Reserved" 142 "Reserved" 141 "Reserved" 140 "Reserved" 139 "Reserved" 138 "Reserved" 137 "Reserved" 136 "Reserved" 135 "Reserved" 134 "Reserved" 133 "Reserved" 132 "Reserved" 131 "Reserved" 130 "Reserved" 129 "Reserved" 128 "Reserved" 127 "Reserved" 126 "Reserved" 125 "Reserved" 124 "Reserved" 123 "Reserved" 122 "Reserved" 121 "Reserved" 120 "Reserved" 119 "Reserved" 118 "Reserved" 117 "Reserved" 116 "Reserved" 115 "Reserved" 114 "Reserved" 113 "Reserved" 112 "Reserved" 111 "Reserved" 110 "Reserved" 109 "Reserved" 108 "Reserved" 107 "Reserved" 106 "Reserved" 105 "Reserved" 104 "Reserved" 103 "Reserved" 102 "Reserved" 101 "Reserved" 100 "Reserved" 99 "Reserved" 98 "Reserved" 97 "Reserved" 96 "Reserved" 95 "Reserved" 94 "Reserved" 93 "Reserved" 92 "Reserved" 91 "Reserved" 90 "Reserved" 89 "Reserved" 88 "Reserved" 87 "Reserved" 86 "Reserved" 85 "Reserved" 84 "Reserved" 83 "Reserved" 82 "Reserved" 81 "Reserved" 80 "Reserved" 79 "Reserved" 78 "Reserved" 77 "Reserved" 76 "Reserved" 75 "Reserved" 74 "Reserved" 73 "Reserved" 72 "Reserved" 71 "Reserved" 70 "Reserved" 69 "Reserved" 68 "Reserved" 67 "Reserved" 66 "Reserved" 65 "Reserved" 64 "Reserved" 63 "Reserved" 62 "Reserved" 61 "Reserved" 60 "Reserved" 59 "Reserved" 58 "Reserved" 57 "Reserved" 56 "Reserved" 55 "Reserved" 54 "Reserved" 53 "Reserved" 52 "Reserved" 51 "Reserved" 50 "Reserved" 49 "Reserved" 48 "Reserved" 47 "Reserved" 46 "Reserved" 45 "Reserved" 44 "Reserved" 43 "Reserved" 42 "Reserved" 41 "Reserved" 40 "Reserved" 39 "Reserved" 38 "Reserved" 37 "Reserved" 36 "Reserved" 35 "Reserved" 34 "Reserved" 33 "Reserved" 32 "Reserved" 31 "Reserved" 30 "Reserved" 29 "Reserved" 28 "Reserved" 27 "Reserved" 26 "Reserved" 25 "Reserved" 24 "Reserved" 23 "Reserved" 22 "Reserved" 21 "Reserved" 20 "Reserved" 19 "Reserved" 18 "Reserved" 17 "Reserved" 16 "Reserved" 15 "Reserved" 14 "Reserved" 13 "Reserved" 12 "Reserved" 11 "Reserved" 10 "Reserved" 9 "Reserved" 8 "Reserved" 7 "RTC唤醒" 6 "板内大气压力传感器唤醒" 5 "板外大气压力传感器唤醒" 4 "KL15唤醒" 3 "KL30唤醒" 2 "AFE唤醒" 1 "网络唤醒" 0 "无唤醒源" ;
VAL_ 1025 BMSFlNmSts 1 "NotInRepMsgSt" 0 "InRepMsgSt" ;
VAL_ 1046 GWEvbusFlPni 1 "NM PDU contains PNI request" 0 "NM PDU contains no PNI request" ;
VAL_ 1046 GWEvbusFlAwb 1 "Active Wakeup" 0 "Passive Wakeup" ;
VAL_ 1046 GWEvbusFlRmr 1 "RMS requested" 0 "RMS not requested" ;
VAL_ 1046 GWEvbusFlWus 255 "Reserved" 254 "Reserved" 253 "Reserved" 252 "Reserved" 251 "Reserved" 250 "Reserved" 249 "Reserved" 248 "Reserved" 247 "Reserved" 246 "Reserved" 245 "Reserved" 244 "Reserved" 243 "Reserved" 242 "Reserved" 241 "Reserved" 240 "Reserved" 239 "Reserved" 238 "Reserved" 237 "Reserved" 236 "Reserved" 235 "Reserved" 234 "Reserved" 233 "Reserved" 232 "Reserved" 231 "Reserved" 230 "Reserved" 229 "Reserved" 228 "Reserved" 227 "Reserved" 226 "Reserved" 225 "Reserved" 224 "Reserved" 223 "Reserved" 222 "Reserved" 221 "Reserved" 220 "Reserved" 219 "Reserved" 218 "Reserved" 217 "Reserved" 216 "Reserved" 215 "Reserved" 214 "Reserved" 213 "Reserved" 212 "Reserved" 211 "Reserved" 210 "Reserved" 209 "Reserved" 208 "Reserved" 207 "Reserved" 206 "Reserved" 205 "Reserved" 204 "Reserved" 203 "Reserved" 202 "Reserved" 201 "Reserved" 200 "Reserved" 199 "Reserved" 198 "Reserved" 197 "Reserved" 196 "Reserved" 195 "Reserved" 194 "Reserved" 193 "Reserved" 192 "Reserved" 191 "Reserved" 190 "Reserved" 189 "Reserved" 188 "Reserved" 187 "Reserved" 186 "Reserved" 185 "Reserved" 184 "Reserved" 183 "Reserved" 182 "Reserved" 181 "Reserved" 180 "Reserved" 179 "Reserved" 178 "Reserved" 177 "Reserved" 176 "Reserved" 175 "Reserved" 174 "Reserved" 173 "Reserved" 172 "Reserved" 171 "Reserved" 170 "Reserved" 169 "Reserved" 168 "Reserved" 167 "Reserved" 166 "Reserved" 165 "Reserved" 164 "Reserved" 163 "Reserved" 162 "Reserved" 161 "Reserved" 160 "Reserved" 159 "Reserved" 158 "Reserved" 157 "Reserved" 156 "Reserved" 155 "Reserved" 154 "Reserved" 153 "Reserved" 152 "Reserved" 151 "Reserved" 150 "Reserved" 149 "Reserved" 148 "Reserved" 147 "Reserved" 146 "Reserved" 145 "Reserved" 144 "Reserved" 143 "Reserved" 142 "Reserved" 141 "Reserved" 140 "Reserved" 139 "Reserved" 138 "Reserved" 137 "Reserved" 136 "Reserved" 135 "Reserved" 134 "Reserved" 133 "Reserved" 132 "Reserved" 131 "Reserved" 130 "Reserved" 129 "Reserved" 128 "Reserved" 127 "Reserved" 126 "Reserved" 125 "Reserved" 124 "Reserved" 123 "Reserved" 122 "Reserved" 121 "Reserved" 120 "Reserved" 119 "Reserved" 118 "Reserved" 117 "Reserved" 116 "Reserved" 115 "Reserved" 114 "Reserved" 113 "Reserved" 112 "Reserved" 111 "Reserved" 110 "Reserved" 109 "Reserved" 108 "Reserved" 107 "Reserved" 106 "Reserved" 105 "Reserved" 104 "Reserved" 103 "Reserved" 102 "Reserved" 101 "Reserved" 100 "Reserved" 99 "Reserved" 98 "Reserved" 97 "Reserved" 96 "Reserved" 95 "Reserved" 94 "Reserved" 93 "Reserved" 92 "Reserved" 91 "Reserved" 90 "Reserved" 89 "Reserved" 88 "Reserved" 87 "Reserved" 86 "Reserved" 85 "Reserved" 84 "Reserved" 83 "Reserved" 82 "Reserved" 81 "Reserved" 80 "Reserved" 79 "Reserved" 78 "Reserved" 77 "Reserved" 76 "Reserved" 75 "Reserved" 74 "Reserved" 73 "Reserved" 72 "Reserved" 71 "Reserved" 70 "Reserved" 69 "Reserved" 68 "Reserved" 67 "Reserved" 66 "Reserved" 65 "Reserved" 64 "Reserved" 63 "Reserved" 62 "Reserved" 61 "Reserved" 60 "Reserved" 59 "Reserved" 58 "Reserved" 57 "Reserved" 56 "Reserved" 55 "Reserved" 54 "Reserved" 53 "Reserved" 52 "Reserved" 51 "Reserved" 50 "Reserved" 49 "Reserved" 48 "Reserved" 47 "Reserved" 46 "Reserved" 45 "Reserved" 44 "Reserved" 43 "Reserved" 42 "Reserved" 41 "Reserved" 40 "Reserved" 39 "Reserved" 38 "Reserved" 37 "Reserved" 36 "Reserved" 35 "Reserved" 34 "Reserved" 33 "Reserved" 32 "Reserved" 31 "Reserved" 30 "Reserved" 29 "Reserved" 28 "Reserved" 27 "Reserved" 26 "Reserved" 25 "Reserved" 24 "Reserved" 23 "Reserved" 22 "Reserved" 21 "Reserved" 20 "Reserved" 19 "Reserved" 18 "Reserved" 17 "Reserved" 16 "Reserved" 15 "Reserved" 14 "Reserved" 13 "Reserved" 12 "Reserved" 11 "Reserved" 10 "Reserved" 9 "Reserved" 8 "Reserved" 7 "Reserved" 6 "Reserved" 5 "Reserved" 4 "Reserved" 3 "WakeUpByTR" 2 "KL 15On" 1 "WakedUpByNetwork" 0 "NoWakeUpSource" ;
VAL_ 1046 GWEvbusFlNmSts 1 "NotInRepMsgSt" 0 "InRepMsgSt" ;
VAL_ 1026 MCUFlPni 1 "NM PDU contains PNI request" 0 "NM PDU contains no PNI request" ;
VAL_ 1026 MCUFlAwb 1 "Active Wakeup" 0 "Passive Wakeup" ;
VAL_ 1026 MCUFlRmr 1 "RMS requested" 0 "RMS not requested" ;
VAL_ 1026 MCUFlWus 255 "Reserved" 254 "Reserved" 253 "Reserved" 252 "Reserved" 251 "Reserved" 250 "Reserved" 249 "Reserved" 248 "Reserved" 247 "Reserved" 246 "Reserved" 245 "Reserved" 244 "Reserved" 243 "Reserved" 242 "Reserved" 241 "Reserved" 240 "Reserved" 239 "Reserved" 238 "Reserved" 237 "Reserved" 236 "Reserved" 235 "Reserved" 234 "Reserved" 233 "Reserved" 232 "Reserved" 231 "Reserved" 230 "Reserved" 229 "Reserved" 228 "Reserved" 227 "Reserved" 226 "Reserved" 225 "Reserved" 224 "Reserved" 223 "Reserved" 222 "Reserved" 221 "Reserved" 220 "Reserved" 219 "Reserved" 218 "Reserved" 217 "Reserved" 216 "Reserved" 215 "Reserved" 214 "Reserved" 213 "Reserved" 212 "Reserved" 211 "Reserved" 210 "Reserved" 209 "Reserved" 208 "Reserved" 207 "Reserved" 206 "Reserved" 205 "Reserved" 204 "Reserved" 203 "Reserved" 202 "Reserved" 201 "Reserved" 200 "Reserved" 199 "Reserved" 198 "Reserved" 197 "Reserved" 196 "Reserved" 195 "Reserved" 194 "Reserved" 193 "Reserved" 192 "Reserved" 191 "Reserved" 190 "Reserved" 189 "Reserved" 188 "Reserved" 187 "Reserved" 186 "Reserved" 185 "Reserved" 184 "Reserved" 183 "Reserved" 182 "Reserved" 181 "Reserved" 180 "Reserved" 179 "Reserved" 178 "Reserved" 177 "Reserved" 176 "Reserved" 175 "Reserved" 174 "Reserved" 173 "Reserved" 172 "Reserved" 171 "Reserved" 170 "Reserved" 169 "Reserved" 168 "Reserved" 167 "Reserved" 166 "Reserved" 165 "Reserved" 164 "Reserved" 163 "Reserved" 162 "Reserved" 161 "Reserved" 160 "Reserved" 159 "Reserved" 158 "Reserved" 157 "Reserved" 156 "Reserved" 155 "Reserved" 154 "Reserved" 153 "Reserved" 152 "Reserved" 151 "Reserved" 150 "Reserved" 149 "Reserved" 148 "Reserved" 147 "Reserved" 146 "Reserved" 145 "Reserved" 144 "Reserved" 143 "Reserved" 142 "Reserved" 141 "Reserved" 140 "Reserved" 139 "Reserved" 138 "Reserved" 137 "Reserved" 136 "Reserved" 135 "Reserved" 134 "Reserved" 133 "Reserved" 132 "Reserved" 131 "Reserved" 130 "Reserved" 129 "Reserved" 128 "Reserved" 127 "Reserved" 126 "Reserved" 125 "Reserved" 124 "Reserved" 123 "Reserved" 122 "Reserved" 121 "Reserved" 120 "Reserved" 119 "Reserved" 118 "Reserved" 117 "Reserved" 116 "Reserved" 115 "Reserved" 114 "Reserved" 113 "Reserved" 112 "Reserved" 111 "Reserved" 110 "Reserved" 109 "Reserved" 108 "Reserved" 107 "Reserved" 106 "Reserved" 105 "Reserved" 104 "Reserved" 103 "Reserved" 102 "Reserved" 101 "Reserved" 100 "Reserved" 99 "Reserved" 98 "Reserved" 97 "Reserved" 96 "Reserved" 95 "Reserved" 94 "Reserved" 93 "Reserved" 92 "Reserved" 91 "Reserved" 90 "Reserved" 89 "Reserved" 88 "Reserved" 87 "Reserved" 86 "Reserved" 85 "Reserved" 84 "Reserved" 83 "Reserved" 82 "Reserved" 81 "Reserved" 80 "Reserved" 79 "Reserved" 78 "Reserved" 77 "Reserved" 76 "Reserved" 75 "Reserved" 74 "Reserved" 73 "Reserved" 72 "Reserved" 71 "Reserved" 70 "Reserved" 69 "Reserved" 68 "Reserved" 67 "Reserved" 66 "Reserved" 65 "Reserved" 64 "Reserved" 63 "Reserved" 62 "Reserved" 61 "Reserved" 60 "Reserved" 59 "Reserved" 58 "Reserved" 57 "Reserved" 56 "Reserved" 55 "Reserved" 54 "Reserved" 53 "Reserved" 52 "Reserved" 51 "Reserved" 50 "Reserved" 49 "Reserved" 48 "Reserved" 47 "Reserved" 46 "Reserved" 45 "Reserved" 44 "Reserved" 43 "Reserved" 42 "Reserved" 41 "Reserved" 40 "Reserved" 39 "Reserved" 38 "Reserved" 37 "Reserved" 36 "Reserved" 35 "Reserved" 34 "Reserved" 33 "Reserved" 32 "Reserved" 31 "Reserved" 30 "Reserved" 29 "Reserved" 28 "Reserved" 27 "Reserved" 26 "Reserved" 25 "Reserved" 24 "Reserved" 23 "Reserved" 22 "Reserved" 21 "Reserved" 20 "Reserved" 19 "Reserved" 18 "Reserved" 17 "Reserved" 16 "Reserved" 15 "Reserved" 14 "Reserved" 13 "Reserved" 12 "Reserved" 11 "Reserved" 10 "Reserved" 9 "Reserved" 8 "Reserved" 7 "Reserved" 6 "Reserved" 5 "Reserved" 4 "Reserved" 3 "WakeUpByTR" 2 "KL 15On" 1 "WakedUpByNetwork" 0 "NoWakeUpSource" ;
VAL_ 1026 MCUFlNmSts 1 "NotInRepMsgSt" 0 "InRepMsgSt" ;
VAL_ 1059 ACFlPni 1 "NM PDU contains PNI request" 0 "NM PDU contains no PNI request" ;
VAL_ 1059 ACFlAwb 1 "Active Wakeup" 0 "Passive Wakeup" ;
VAL_ 1059 ACFlRmr 1 "RMS requested" 0 "RMS not requested" ;
VAL_ 1059 ACFlWus 255 "Reserved" 254 "Reserved" 253 "Reserved" 252 "Reserved" 251 "Reserved" 250 "Reserved" 249 "Reserved" 248 "Reserved" 247 "Reserved" 246 "Reserved" 245 "Reserved" 244 "Reserved" 243 "Reserved" 242 "Reserved" 241 "Reserved" 240 "Reserved" 239 "Reserved" 238 "Reserved" 237 "Reserved" 236 "Reserved" 235 "Reserved" 234 "Reserved" 233 "Reserved" 232 "Reserved" 231 "Reserved" 230 "Reserved" 229 "Reserved" 228 "Reserved" 227 "Reserved" 226 "Reserved" 225 "Reserved" 224 "Reserved" 223 "Reserved" 222 "Reserved" 221 "Reserved" 220 "Reserved" 219 "Reserved" 218 "Reserved" 217 "Reserved" 216 "Reserved" 215 "Reserved" 214 "Reserved" 213 "Reserved" 212 "Reserved" 211 "Reserved" 210 "Reserved" 209 "Reserved" 208 "Reserved" 207 "Reserved" 206 "Reserved" 205 "Reserved" 204 "Reserved" 203 "Reserved" 202 "Reserved" 201 "Reserved" 200 "Reserved" 199 "Reserved" 198 "Reserved" 197 "Reserved" 196 "Reserved" 195 "Reserved" 194 "Reserved" 193 "Reserved" 192 "Reserved" 191 "Reserved" 190 "Reserved" 189 "Reserved" 188 "Reserved" 187 "Reserved" 186 "Reserved" 185 "Reserved" 184 "Reserved" 183 "Reserved" 182 "Reserved" 181 "Reserved" 180 "Reserved" 179 "Reserved" 178 "Reserved" 177 "Reserved" 176 "Reserved" 175 "Reserved" 174 "Reserved" 173 "Reserved" 172 "Reserved" 171 "Reserved" 170 "Reserved" 169 "Reserved" 168 "Reserved" 167 "Reserved" 166 "Reserved" 165 "Reserved" 164 "Reserved" 163 "Reserved" 162 "Reserved" 161 "Reserved" 160 "Reserved" 159 "Reserved" 158 "Reserved" 157 "Reserved" 156 "Reserved" 155 "Reserved" 154 "Reserved" 153 "Reserved" 152 "Reserved" 151 "Reserved" 150 "Reserved" 149 "Reserved" 148 "Reserved" 147 "Reserved" 146 "Reserved" 145 "Reserved" 144 "Reserved" 143 "Reserved" 142 "Reserved" 141 "Reserved" 140 "Reserved" 139 "Reserved" 138 "Reserved" 137 "Reserved" 136 "Reserved" 135 "Reserved" 134 "Reserved" 133 "Reserved" 132 "Reserved" 131 "Reserved" 130 "Reserved" 129 "Reserved" 128 "Reserved" 127 "Reserved" 126 "Reserved" 125 "Reserved" 124 "Reserved" 123 "Reserved" 122 "Reserved" 121 "Reserved" 120 "Reserved" 119 "Reserved" 118 "Reserved" 117 "Reserved" 116 "Reserved" 115 "Reserved" 114 "Reserved" 113 "Reserved" 112 "Reserved" 111 "Reserved" 110 "Reserved" 109 "Reserved" 108 "Reserved" 107 "Reserved" 106 "Reserved" 105 "Reserved" 104 "Reserved" 103 "Reserved" 102 "Reserved" 101 "Reserved" 100 "Reserved" 99 "Reserved" 98 "Reserved" 97 "Reserved" 96 "Reserved" 95 "Reserved" 94 "Reserved" 93 "Reserved" 92 "Reserved" 91 "Reserved" 90 "Reserved" 89 "Reserved" 88 "Reserved" 87 "Reserved" 86 "Reserved" 85 "Reserved" 84 "Reserved" 83 "Reserved" 82 "Reserved" 81 "Reserved" 80 "Reserved" 79 "Reserved" 78 "Reserved" 77 "Reserved" 76 "Reserved" 75 "Reserved" 74 "Reserved" 73 "Reserved" 72 "Reserved" 71 "Reserved" 70 "Reserved" 69 "Reserved" 68 "Reserved" 67 "Reserved" 66 "Reserved" 65 "Reserved" 64 "Reserved" 63 "Reserved" 62 "Reserved" 61 "Reserved" 60 "Reserved" 59 "Reserved" 58 "Reserved" 57 "Reserved" 56 "Reserved" 55 "Reserved" 54 "Reserved" 53 "Reserved" 52 "Reserved" 51 "Reserved" 50 "Reserved" 49 "Reserved" 48 "Reserved" 47 "Reserved" 46 "Reserved" 45 "Reserved" 44 "Reserved" 43 "Reserved" 42 "Reserved" 41 "Reserved" 40 "Reserved" 39 "Reserved" 38 "Reserved" 37 "Reserved" 36 "Reserved" 35 "Reserved" 34 "Reserved" 33 "Reserved" 32 "Reserved" 31 "Reserved" 30 "Reserved" 29 "Reserved" 28 "Reserved" 27 "Reserved" 26 "Reserved" 25 "Reserved" 24 "Reserved" 23 "Reserved" 22 "Reserved" 21 "Reserved" 20 "Reserved" 19 "Reserved" 18 "Reserved" 17 "Reserved" 16 "Reserved" 15 "Reserved" 14 "Reserved" 13 "Reserved" 12 "Reserved" 11 "Reserved" 10 "Reserved" 9 "Reserved" 8 "Reserved" 7 "Reserved" 6 "Reserved" 5 "Reserved" 4 "Reserved" 3 "Reserved" 2 "KL 15On" 1 "WakedUpByNetwork" 0 "NoWakeUpSource" ;
VAL_ 1059 ACFlNmSts 1 "NotInRepMsgSt" 0 "InRepMsgSt" ;
VAL_ 1141 LBMSFlPni 1 "NM PDU contains PNI request" 0 "NM PDU contains no PNI request" ;
VAL_ 1141 LBMSFlAwb 1 "Active Wakeup" 0 "Passive Wakeup" ;
VAL_ 1141 LBMSFlRmr 1 "RMS requested" 0 "RMS not requested" ;
VAL_ 1141 LBMSFlWus 255 "Reserved" 254 "Reserved" 253 "Reserved" 252 "Reserved" 251 "Reserved" 250 "Reserved" 249 "Reserved" 248 "Reserved" 247 "Reserved" 246 "Reserved" 245 "Reserved" 244 "Reserved" 243 "Reserved" 242 "Reserved" 241 "Reserved" 240 "Reserved" 239 "Reserved" 238 "Reserved" 237 "Reserved" 236 "Reserved" 235 "Reserved" 234 "Reserved" 233 "Reserved" 232 "Reserved" 231 "Reserved" 230 "Reserved" 229 "Reserved" 228 "Reserved" 227 "Reserved" 226 "Reserved" 225 "Reserved" 224 "Reserved" 223 "Reserved" 222 "Reserved" 221 "Reserved" 220 "Reserved" 219 "Reserved" 218 "Reserved" 217 "Reserved" 216 "Reserved" 215 "Reserved" 214 "Reserved" 213 "Reserved" 212 "Reserved" 211 "Reserved" 210 "Reserved" 209 "Reserved" 208 "Reserved" 207 "Reserved" 206 "Reserved" 205 "Reserved" 204 "Reserved" 203 "Reserved" 202 "Reserved" 201 "Reserved" 200 "Reserved" 199 "Reserved" 198 "Reserved" 197 "Reserved" 196 "Reserved" 195 "Reserved" 194 "Reserved" 193 "Reserved" 192 "Reserved" 191 "Reserved" 190 "Reserved" 189 "Reserved" 188 "Reserved" 187 "Reserved" 186 "Reserved" 185 "Reserved" 184 "Reserved" 183 "Reserved" 182 "Reserved" 181 "Reserved" 180 "Reserved" 179 "Reserved" 178 "Reserved" 177 "Reserved" 176 "Reserved" 175 "Reserved" 174 "Reserved" 173 "Reserved" 172 "Reserved" 171 "Reserved" 170 "Reserved" 169 "Reserved" 168 "Reserved" 167 "Reserved" 166 "Reserved" 165 "Reserved" 164 "Reserved" 163 "Reserved" 162 "Reserved" 161 "Reserved" 160 "Reserved" 159 "Reserved" 158 "Reserved" 157 "Reserved" 156 "Reserved" 155 "Reserved" 154 "Reserved" 153 "Reserved" 152 "Reserved" 151 "Reserved" 150 "Reserved" 149 "Reserved" 148 "Reserved" 147 "Reserved" 146 "Reserved" 145 "Reserved" 144 "Reserved" 143 "Reserved" 142 "Reserved" 141 "Reserved" 140 "Reserved" 139 "Reserved" 138 "Reserved" 137 "Reserved" 136 "Reserved" 135 "Reserved" 134 "Reserved" 133 "Reserved" 132 "Reserved" 131 "Reserved" 130 "Reserved" 129 "Reserved" 128 "Reserved" 127 "Reserved" 126 "Reserved" 125 "Reserved" 124 "Reserved" 123 "Reserved" 122 "Reserved" 121 "Reserved" 120 "Reserved" 119 "Reserved" 118 "Reserved" 117 "Reserved" 116 "Reserved" 115 "Reserved" 114 "Reserved" 113 "Reserved" 112 "Reserved" 111 "Reserved" 110 "Reserved" 109 "Reserved" 108 "Reserved" 107 "Reserved" 106 "Reserved" 105 "Reserved" 104 "Reserved" 103 "Reserved" 102 "Reserved" 101 "Reserved" 100 "Reserved" 99 "Reserved" 98 "Reserved" 97 "Reserved" 96 "Reserved" 95 "Reserved" 94 "Reserved" 93 "Reserved" 92 "Reserved" 91 "Reserved" 90 "Reserved" 89 "Reserved" 88 "Reserved" 87 "Reserved" 86 "Reserved" 85 "Reserved" 84 "Reserved" 83 "Reserved" 82 "Reserved" 81 "Reserved" 80 "Reserved" 79 "Reserved" 78 "Reserved" 77 "Reserved" 76 "Reserved" 75 "Reserved" 74 "Reserved" 73 "Reserved" 72 "Reserved" 71 "Reserved" 70 "Reserved" 69 "Reserved" 68 "Reserved" 67 "Reserved" 66 "Reserved" 65 "Reserved" 64 "Reserved" 63 "Reserved" 62 "Reserved" 61 "Reserved" 60 "Reserved" 59 "Reserved" 58 "Reserved" 57 "Reserved" 56 "Reserved" 55 "Reserved" 54 "Reserved" 53 "Reserved" 52 "Reserved" 51 "Reserved" 50 "Reserved" 49 "Reserved" 48 "Reserved" 47 "Reserved" 46 "Reserved" 45 "Reserved" 44 "Reserved" 43 "Reserved" 42 "Reserved" 41 "Reserved" 40 "Reserved" 39 "Reserved" 38 "Reserved" 37 "Reserved" 36 "Reserved" 35 "Reserved" 34 "Reserved" 33 "Reserved" 32 "Reserved" 31 "Reserved" 30 "Reserved" 29 "Reserved" 28 "Reserved" 27 "Reserved" 26 "Reserved" 25 "Reserved" 24 "Reserved" 23 "Reserved" 22 "Reserved" 21 "Reserved" 20 "Reserved" 19 "Reserved" 18 "Reserved" 17 "Reserved" 16 "Reserved" 15 "Reserved" 14 "Reserved" 13 "Reserved" 12 "Reserved" 11 "Reserved" 10 "Reserved" 9 "Reserved" 8 "Reserved" 7 "Reserved" 6 "Reserved" 5 "Reserved" 4 "Reserved" 3 "WakedUpByHardwire" 2 "WakedUpByChrgReq" 1 "WakedUpByNetwork" 0 "NoWakeUpSource" ;
VAL_ 1141 LBMSFlNmSts 1 "NotInRepMsgSt" 0 "InRepMsgSt" ;
VAL_ 521 MCU_F_MCUPowerOffCmd 1 "有请求" 0 "无请求" ;
VAL_ 521 MCU_F_MCUInitComp_flg 1 "初始化已完成" 0 "初始化未完成" ;
VAL_ 521 MCU_DC_CUR 65535 "Invalid" ;
VAL_ 521 MCU_PHASE_CUR 65535 "Invalid" ;
VAL_ 521 MCU_DC_VOLT 65535 "Invalid" ;
VAL_ 296 dmc_dTcsDbgSignal1_M1 1 "dmc_active" 0 "dmc_not activel" ;
VAL_ 296 dmc_dTcsDbgSignal4_M1 4 "DMC_STATE_MAX" 3 "DMC_RAMPOUT" 2 "DMC_NORMAL" 1 "DMC_INITIAL" 0 "DMC_EXIT" ;
VAL_ 296 dmc_dTcsDbgSignal5_M1 3 "SLIP_STATE_MAX" 2 "SLIP_SPLIT" 1 "SLIP_HOMO" 0 "SLIP_STABLE" ;
VAL_ 296 DmcFrtDTCSOperaMode 7 "Reserved" 6 "Reserved" 5 "Reserved" 4 "DMC_CONTROL_MAX" 3 "DMC_FAULT" 2 "DMC_OFF" 1 "DMC_ON" 0 "DMC_INIT" ;
VAL_ 1152 OBC_DCCrt 65535 "Invalid" ;
VAL_ 1152 OBC_DCVolt 65535 "Invalid" ;
VAL_ 1152 IPUCPDir 3 "预留" 2 "放电" 1 "充电" 0 "初始值" ;
VAL_ 1152 IPUHeatReqFlg 3 "Reserved" 2 "请求加热" 1 "未请求加热" 0 "初始值" ;
VAL_ 1304 DcdcMilReq 1 "Active" 0 "Inactive" ;
VAL_ 1304 DCDC_OutpCrt 65535 "Invalid" ;
VAL_ 1304 DCDC_InpVolt 65535 "Invalid" ;
VAL_ 1304 DCDC_InpCrt 255 "Invalid" ;
VAL_ 1304 DCDC_OutpVolt 255 "Invalid" ;
VAL_ 1313 DCDC_InpOverVoltSwFlt 1 "异常" 0 "正常" ;
VAL_ 1313 DCDC_InpUnderVoltFlt 1 "异常" 0 "正常" ;
VAL_ 1313 DCDC_LVOutpOverVoltFlt 1 "异常" 0 "正常" ;
VAL_ 1313 DCDC_LVOutpUnderVoltFlt 1 "异常" 0 "正常" ;
VAL_ 1313 PDU_BusoffFlt 1 "异常" 0 "正常" ;
VAL_ 1313 DCDC_OverTTurnDwnLoadFlt 1 "异常" 0 "正常" ;
VAL_ 1313 IPU_ComCheckErr 1 "异常" 0 "正常" ;
VAL_ 1313 DCDC_InpCurOverSwFlt 1 "异常" 0 "正常" ;
VAL_ 1313 DCDC_OverTShutDwnFlt 1 "报警" 0 "正常" ;
VAL_ 1313 DCDC_StsAlrmFlt 1 "报警" 0 "正常" ;
VAL_ 1313 DCDC_CrtStsGB 2 "断开" 1 "工作" ;
VAL_ 1313 DCDC_LVOutpOverCurrFlt 1 "报警" 0 "正常" ;
VAL_ 1313 DCDC_St_TMP 255 "Invalid" ;
VAL_ 1313 DCDC_INPUT_VOLT_CHECK_FLT 1 "异常" 0 "正常" ;
VAL_ 1313 DCDC_OUTPUT_VOLT_CHECK_FLT 1 "异常" 0 "正常" ;
VAL_ 1313 DCDC_IntFlt 1 "异常" 0 "正常" ;
VAL_ 1313 DCDC_ComLostFlt_PDCU 1 "异常" 0 "正常" ;
VAL_ 1313 DCDC_OutpShoCircFlt 1 "异常" 0 "正常" ;
VAL_ 1313 DCDC_CrtSts 3 "故障状态" 2 "断开状态" 1 "工作状态" 0 "Void" ;
VAL_ 1313 BoostCurOverFlt 1 "异常" 0 "正常" ;
VAL_ 1746 OBC_HVDCOutpOverCrtHwFlt 1 "异常" 0 "正常" ;
VAL_ 1746 OBC_HVDCOutpShortFlt 1 "异常" 0 "正常" ;
VAL_ 1746 PFC_PowFreMOSOverTFlt 1 "异常" 0 "正常" ;
VAL_ 1746 OBC_ACVoltOverVoltFlt 1 "异常" 0 "正常" ;
VAL_ 1746 OBC_ACVoltUnderVoltFlt 1 "异常" 0 "正常" ;
VAL_ 1746 OBC_HVDCOutpOverVoltSwFlt 1 "异常" 0 "正常" ;
VAL_ 1746 OBC_HVDCOutpUnderVoltFlt 1 "异常" 0 "正常" ;
VAL_ 1746 OBC_InpCrtOverCrtHwSwFlt 1 "异常" 0 "正常" ;
VAL_ 1746 PFC_MOSOverTFlt 1 "异常" 0 "正常" ;
VAL_ 1746 LLC_OriSideMOSOverTFlt 1 "异常" 0 "正常" ;
VAL_ 1746 OBC_ACPoweroff 1 "异常" 0 "正常" ;
VAL_ 1746 DiscCPSIGErr 1 "异常" 0 "正常" ;
VAL_ 1746 OBC_LVOutpOverVoltFlt 1 "异常" 0 "正常" ;
VAL_ 1746 OBC_LiquidOverTShutDwnFlt 1 "异常" 0 "正常" ;
VAL_ 1746 OBC_LiquidOverTDwnPwrFlt 1 "异常" 0 "正常" ;
VAL_ 1746 LLC_SenSideMOSOverTFlt 1 "异常" 0 "正常" ;
VAL_ 1746 OBC_HVDCOutpOverVoltHwFlt 1 "异常" 0 "正常" ;
VAL_ 1746 OBC_INVOutpShortFlt 1 "异常" 0 "正常" ;
VAL_ 1746 OBC_INVOutpOverLoadFlt 1 "异常" 0 "正常" ;
VAL_ 1746 OBC_PfcCllcSciLost 1 "异常" 0 "正常" ;
VAL_ 1746 OBC_IntOverTFlt 1 "异常" 0 "正常" ;
VAL_ 1746 OBC_IntFlt 1 "异常" 0 "正常" ;
VAL_ 1746 BOBC_OverTFlt 1 "异常" 0 "正常" ;
VAL_ 1746 PFCBusOverVoltFlt 1 "异常" 0 "正常" ;
VAL_ 1746 OBC_HVDCOutpOverCrtSwFlt 1 "异常" 0 "正常" ;
VAL_ 1746 OBC_ACCrtChkCircFlt 1 "异常" 0 "正常" ;
VAL_ 1746 PFCBusUnderVoltFlt 1 "异常" 0 "正常" ;
VAL_ 1746 OBC_INVOutpOverVoltFlt 1 "异常" 0 "正常" ;
VAL_ 1746 OBC_INVOutpUnderVoltFlt 1 "异常" 0 "正常" ;
VAL_ 1746 OBC_INVInpOverVoltFlt 1 "异常" 0 "正常" ;
VAL_ 1746 OBC_INVInpUnderVoltFlt 1 "异常" 0 "正常" ;
VAL_ 1746 OBC_INVOutpOverCurrSlowFlt 1 "异常" 0 "正常" ;
VAL_ 1746 ACInputPhaTypeFlt 1 "异常" 0 "正常" ;
VAL_ 1746 CLLCChaStsInpUnderVoltFlt 1 "异常" 0 "正常" ;
VAL_ 1746 BOBC_CCSIG_ERR 1 "异常" 0 "正常" ;
VAL_ 1746 BOBC_CPSIG_ERR 1 "异常" 0 "正常" ;
VAL_ 1746 OBC_LVOutpUnderVoltFlt 1 "异常" 0 "正常" ;
VAL_ 1746 BOBC_PowOverVoltHwFlt 1 "异常" 0 "正常" ;
VAL_ 1746 ACFreLowFlt 1 "异常" 0 "正常" ;
VAL_ 1746 ACFreHighFlt 1 "异常" 0 "正常" ;
VAL_ 1746 BOBC_BatOverCurrHwFlt 1 "异常" 0 "正常" ;
VAL_ 1746 OBC_InpCrtOverCrtHwFlt 1 "异常" 0 "正常" ;
VAL_ 1746 OBC_ACVoltFreqFlt 1 "异常" 0 "正常" ;
VAL_ 1746 BUSMidVoltFlt 1 "异常" 0 "正常" ;
VAL_ 1746 OBC_ACSCIntlkSigChkCircFlt 1 "异常" 0 "正常" ;
VAL_ 1746 OBC_PTCIntlkSigChkCircFlt 1 "异常" 0 "正常" ;
VAL_ 1746 OBC_PwrBattIntlkSigChkCircFlt 1 "异常" 0 "正常" ;
VAL_ 1746 OBC_INVCllcBusOverVoltFlt 1 "异常" 0 "正常" ;
VAL_ 1747 OBC_ACVolt_L1 65535 "Invalid" ;
VAL_ 1747 OBC_T 255 "Invalid" ;
VAL_ 1747 OBC_CrtSts 7 "无效值" 6 "Void" 5 "休眠状态" 4 "故障状态" 3 "诊断服务状态" 2 "工作状态" 1 "待机状态" 0 "初始化状态" ;
VAL_ 1747 PFC_OpenStatus 1 "工作状态" 0 "待机状态" ;
VAL_ 1747 LLC_OpenStatus 1 "工作状态" 0 "待机状态" ;
VAL_ 1748 OBC_VCU_AWAK_POW_STA 1 "已唤醒" 0 "未唤醒" ;
VAL_ 1748 OBC_ExtDchaSts_Sokt 7 "Reserved" 6 "Reserved" 5 "Reserved" 4 "故障状态" 3 "碰撞状态" 2 "工作状态" 1 "待机状态" 0 "初始值" ;
VAL_ 1748 OBC_MinOutpVolt 65535 "Invalid" ;
VAL_ 1748 OBC_MaxOutpVolt 65535 "Invalid" ;
VAL_ 1748 OBC_InpVoltRng 3 "110V~220V" 2 "110V" 1 "220V" 0 "其它" ;
VAL_ 1748 OBC_Splr 12 "麦格米特" 11 "法雷奥" 10 "LEAR" 9 "台达" 8 "海晨" 7 "嘉昌" 6 "舜唐" 5 "中港电力" 4 "富特" 3 "威迈斯" 2 "核达" 1 "欣锐" 0 "其它" ;
VAL_ 1748 OBC_Pwr 3 "6.6kw" 2 "3.3kw" 1 "2kw" 0 "其它" ;
VAL_ 1748 ObcMilReq 1 "Active" 0 "Inactive" ;
VAL_ 1750 OBC_OperMod 3 "VTOV放电模式" 2 "VTOL放电模式" 1 "充电状态" 0 "初始状态" ;
VAL_ 1750 IPU_TMP_H 255 "Invalid" ;
VAL_ 1750 PFC_St_TMP 255 "Invalid" ;
VAL_ 1750 LLC_St_TMP 255 "Invalid" ;
VAL_ 1750 IPU_OBC_PFC_VBUS 65535 "Invalid" ;
VAL_ 1751 OBC_SoktCrtPwrFlg 1 "Invalid" 0 "Valid" ;
VAL_ 1751 IPUS2SwtSts 3 "Invalid" 2 "闭合" 1 "断开" 0 "初始值" ;
VAL_ 1751 IPUS1SwtSts 3 "Invalid" 2 "PWM" 1 "电平" 0 "初始值" ;
VAL_ 1324 EWP_FD_Sts 3 "空转" 2 "故障" 1 "运行" 0 "停机" ;
VAL_ 1010 OutdT 120 "Invalid" ;
VAL_ 1010 OutdTVld 7 "Invalid" 6 "Reserved" 5 "Reserved" 4 "Reserved" 3 "Value above upper limit" 2 "Value below lower limit" 1 "Valid" 0 "Reserved" ;
VAL_ 1153 VCU_DC_EN_CMD 1 "Enable" 0 "Disable" ;
VAL_ 1156 VCU_SOCKET_ENA_CMD 1 "允许使能" 0 "禁止使能" ;
VAL_ 1157 VCU_ActvDchaEnaFlg 3 "Invalid" 2 "使能" 1 "不使能" 0 "初始值" ;
VAL_ 1157 CPDirReq 3 "Reserved" 2 "放电" 1 "充电" 0 "初始值" ;
VAL_ 1161 MCU_F_DrvrMot1CrtSts 4 "准备状态；" 3 "关闭状态；" 2 "发电；" 1 "耗电；" ;
VAL_ 1161 FroMcuWorkSta 31 "Reserved" 30 "Reserved" 29 "Reserved" 28 "Reserved" 27 "Reserved" 26 "Reserved" 25 "Reserved" 24 "Reserved" 23 "Reserved" 22 "Reserved" 21 "Reserved" 20 "Reserved" 19 "Reserved" 18 "Reserved" 17 "Reserved" 16 "Reserved" 15 "Sleep" 14 "DisCharge" 13 "Failure" 12 "PrePowerDown" 11 "ConsVBoost" 10 "ConsABoost" 9 "BoostPreChrg" 8 "TrqCtl" 7 "QHeat" 6 "SpdCtl" 5 "Reserved" 4 "Reserved" 3 "HVActive" 2 "Reserved" 1 "Standby" 0 "Initial" ;
VAL_ 1161 MCU_I2TEnable 1 "使能" 0 "未使能" ;
VAL_ 1162 MotAssHeaSta 7 "Reserved" 6 "Reserved" 5 "故障状态" 4 "驻车工况主动加热状态" 3 "驱动&回收工况主动加热状态" 2 "仅回收工况主动加热状态" 1 "待机状态" 0 "初始化" ;
VAL_ 1163 VCU_BRAKE_ENGERY_RECOV_STA 1 "禁止能量回收" 0 "允许能量回收" ;
VAL_ 1297 VCU_VehRemRefrshModReq 3 "远程高低压刷写切换模式" 2 "远程低压刷写模式" 1 "远程高压刷写模式" 0 "初始值" ;
VAL_ 1397 VCU_ExhibitionMode 3 "预留" 2 "展车模式关闭" 1 "展车模式开启" 0 "初始值；" ;
VAL_ 1574 VCU_ComLostFlt_ESP 1 "异常" 0 "正常" ;
VAL_ 1576 RemSpdTarCmdVld 1 "Valid" 0 "Invalid" ;
VAL_ 1576 RemMotDampgFobd 1 "禁止" 0 "未禁止" ;
VAL_ 1576 VCU_VEH_MODE 13 "Reserved" 12 "Reserved" 11 "运行异常" 10 "低功耗模式" 9 "Reserved" 8 "智能充电模式" 7 "远程慢充模式" 6 "程序刷新模式" 5 "快充模式" 4 "慢充模式" 3 "远程运行模式" 2 "运行模式" 1 "停车模式" 0 "掉电模式" ;
VAL_ 1576 BattVoltAnormStopDiagFlg 1 "异常" 0 "正常" ;
VAL_ 1576 VCUZeroTorFlg 1 "置位" 0 "未置位" ;
VAL_ 1576 VCU_TEMOTE_POWER_ON_REQ 3 "void；" 2 "有需求；" 1 "无需求；" 0 "初始化；" ;
VAL_ 1585 VCU_Socket_SWH_REQ_CMD 3 "Reserved" 2 "关闭" 1 "开启" 0 "初始值" ;
VAL_ 1614 VCU_COLL_SIG_STA 1 "碰撞" 0 "未碰撞" ;
VAL_ 1624 MotAssHeaCmd 7 "Reserved" 6 "Reserved" 5 "Reserved" 4 "驻车工况主动加热指令" 3 "驱动&回收工况主动加热指令" 2 "仅回收工况主动加热指令" 1 "非主动加热指令" 0 "初始化" ;
VAL_ 1624 MotAssHeaEnaCmd 1 "Enable" 0 "Disable" ;
VAL_ 1683 MCU_F_ReadZeroPointErr 1 "故障" 0 "无故障" ;
VAL_ 1683 MCU_F_CheckPoint1Err 1 "故障" 0 "无故障" ;
VAL_ 1683 MCU_F_CheckPoint2Err 1 "故障" 0 "无故障" ;
VAL_ 1683 MCU_F_CheckOverRangeErr 1 "故障" 0 "无故障" ;
VAL_ 1683 MCU_MCU_SUPPLIER 11 "麦格米特" 10 "英博尔" 9 "巨一电机" 8 "和鑫电机" 7 "Void" 6 "BJEV" 5 "西门子电机" 4 "上海电驱动" 3 "大连电机" 2 "大郡电机" 1 "大洋电机" 0 "其他" ;
VAL_ 1683 MCU_CAL_SW_VER 29 "G3-9；" 28 "G3-8；" 27 "G3-7；" 26 "G3-6；" 25 "G3-5；" 24 "G3-4；" 23 "G3-3；" 22 "G3-2；" 21 "G3-1；" 20 "预留；" 19 "G4-9；" 18 "G4-8；" 17 "G4-7；" 16 "G4-6；" 15 "G4-5；" 14 "G4-4；" 13 "G4-3；" 12 "G4-2；" 11 "G4-1；" 10 "预留；" 9 "G6-9；" 8 "G6-8；" 7 "G6-7；" 6 "G6-6；" 5 "G6-5；" 4 "G6-4；" 3 "G6-3；" 2 "G6-2；" 1 "G6-1；" 0 "预留；" ;
VAL_ 1683 MCU_F_CheckDifferentErr 1 "故障" 0 "无故障" ;
VAL_ 1683 MCU_F_CheckPointinvalidErr 1 "故障" 0 "无故障" ;
VAL_ 1683 McuEgyFbLimSta 255 "预留" 254 "预留" 253 "预留" 252 "预留" 251 "预留" 250 "预留" 249 "预留" 248 "预留" 247 "预留" 246 "预留" 245 "预留" 244 "预留" 243 "预留" 242 "预留" 241 "预留" 240 "预留" 239 "预留" 238 "预留" 237 "预留" 236 "预留" 235 "预留" 234 "预留" 233 "预留" 232 "预留" 231 "预留" 230 "预留" 229 "预留" 228 "预留" 227 "预留" 226 "预留" 225 "预留" 224 "预留" 223 "预留" 222 "预留" 221 "预留" 220 "预留" 219 "预留" 218 "预留" 217 "预留" 216 "预留" 215 "预留" 214 "预留" 213 "预留" 212 "预留" 211 "预留" 210 "预留" 209 "预留" 208 "预留" 207 "预留" 206 "预留" 205 "预留" 204 "预留" 203 "预留" 202 "预留" 201 "预留" 200 "预留" 199 "预留" 198 "预留" 197 "预留" 196 "预留" 195 "预留" 194 "预留" 193 "预留" 192 "预留" 191 "预留" 190 "预留" 189 "预留" 188 "预留" 187 "预留" 186 "预留" 185 "预留" 184 "预留" 183 "预留" 182 "预留" 181 "预留" 180 "预留" 179 "预留" 178 "预留" 177 "预留" 176 "预留" 175 "预留" 174 "预留" 173 "预留" 172 "预留" 171 "预留" 170 "预留" 169 "预留" 168 "预留" 167 "预留" 166 "预留" 165 "预留" 164 "预留" 163 "预留" 162 "预留" 161 "预留" 160 "预留" 159 "预留" 158 "预留" 157 "预留" 156 "预留" 155 "预留" 154 "预留" 153 "预留" 152 "预留" 151 "预留" 150 "预留" 149 "预留" 148 "预留" 147 "预留" 146 "预留" 145 "预留" 144 "预留" 143 "预留" 142 "预留" 141 "预留" 140 "预留" 139 "预留" 138 "预留" 137 "预留" 136 "预留" 135 "预留" 134 "预留" 133 "预留" 132 "预留" 131 "预留" 130 "预留" 129 "预留" 128 "ABS激活" 64 "轮速无效" 32 "电池回馈功率限制" 16 "BMS禁止充电" 8 "ABS通讯丢失" 4 "ABS故障" 2 "后母线电压过压" 1 "前母线电压过压" 0 "无限制" ;
VAL_ 1728 VCU_READY_LAMP 1 "已准备好" 0 "未准备好" ;
VAL_ 1739 MCU_MCU_F_SUM 255 "Invalid" ;
VAL_ 1739 McuIgbtTemp 255 "Invalid" ;
VAL_ 1739 McuMotSpd 65535 "Invalid" ;
VAL_ 1739 McuMotTemp 255 "Invalid" ;
VAL_ 1739 MCU_F_DrvrMot1CrtSts_GB 4 "准备状态；" 3 "关闭状态；" 2 "发电；" 1 "耗电；" ;
VAL_ 1739 MCU_F_MCUTempAlarmLv1 1 "故障" 0 "无故障" ;
VAL_ 1739 MCU_F_MCUTempAlarmLv2 1 "故障" 0 "无故障" ;
VAL_ 1739 MCU_F_MotTempAlarmLv1 1 "故障" 0 "无故障" ;
VAL_ 1739 MCU_F_MotTempAlarmLv2 1 "故障" 0 "无故障" ;
VAL_ 1739 MCU_F_OverSpdAlarmLv1 1 "故障" 0 "无故障" ;
VAL_ 1739 MCU_F_OverSpdAlarmLv2 1 "故障" 0 "无故障" ;
VAL_ 1739 MCU_F_OverCurAlarmLv1 1 "故障" 0 "无故障" ;
VAL_ 1739 MCU_F_OverCurAlarmLv2 1 "故障" 0 "无故障" ;
VAL_ 1739 MCU_F_OverCurAlarmLv3 1 "故障" 0 "无故障" ;
VAL_ 1739 McuMotTor 65535 "Invalid" ;
VAL_ 1739 McuDcCur 65535 "Invalid" ;
VAL_ 1739 McuDcVolt 65535 "Invalid" ;
VAL_ 512 VCUSpeedLimTypRq 15 "Reserved" 14 "Reserved" 13 "Reserved" 12 "Reserved" 11 "Reserved" 10 "Reserved" 9 "Reserved" 8 "Reserved" 7 "Reserved" 6 "Reserved" 5 "Reserved" 4 "Reserved" 3 "限速60" 2 "限速30" 1 "限速15" 0 "无限速" ;
VAL_ 534 MCU_MOT_ActiveDamping_Flg 1 "使能" 0 "未使能" ;
VAL_ 534 MCU_MOT_DIR_CMD 3 "Void" 2 "反转（倒车模式）" 1 "正转（前进模式）" 0 "待机状态" ;
VAL_ 534 MCU_MOT_SPD 65535 "Invalid" ;
VAL_ 534 MCU_MOT_TOR 65535 "Invalid" ;
VAL_ 534 MCU_TOR_QUA_AFC 3 "Reserved" 2 "Invalid" 1 "Valid" 0 "Initializing" ;
VAL_ 534 MCU_MOT_INIT 1 "初始化已完成" 0 "初始化未完成" ;
VAL_ 534 MCU_SPD_QUA_AFC 3 "Reserved" 2 "Invalid" 1 "Valid" 0 "Initializing" ;
VAL_ 534 MCU_HV_CHECK_FLAG 1 "已完成" 0 "未完成" ;
VAL_ 534 MCU_HV_DISOBC_STA 3 "放电失败" 2 "放电完成" 1 "放电中" 0 "未放电" ;
VAL_ 534 MCU_LV_OFF_REQ_FLAG 1 "有请求" 0 "无请求" ;
VAL_ 534 MCU_MOT_STA 3 "Void" 2 "发电状态" 1 "电动状态" 0 "待机状态" ;
VAL_ 534 MCU_MOT_MODE 3 "Void" 2 "转速模式" 1 "转矩模式" 0 "待机状态" ;
VAL_ 528 VCU_DRV_APS_PER_FLG 3 "Reserved" 2 "Invalid" 1 "Vaild" 0 "Initializing" ;
VAL_ 528 VCU_DRV_APS_PER 255 "Invalid" ;
VAL_ 528 VCU_BRAKE_STA 1 "已踩制动踏板" 0 "未踩制动踏板" ;
VAL_ 531 VCU_MOT_MODE_CMD 3 "Void" 2 "转速模式" 1 "转矩模式" 0 "待机状态" ;
VAL_ 531 VCU_DTCRecoverRequest_BE12 1 "有请求" 0 "无请求" ;
VAL_ 531 VCU_MCU_ENABLE_CMD 1 "Enable" 0 "Disable" ;
VAL_ 532 VCU_ON_WAKEUP 1 "已唤醒" 0 "未唤醒" ;
VAL_ 560 VCU_STRATEGY_SHIFT_POSITION 7 "S挡" 6 "E挡" 5 "Void" 4 "D挡" 3 "R挡" 2 "N挡" 1 "P挡" 0 "Void" ;
VAL_ 560 VCU_GearShiftInternal 15 "Reserved" 14 "Reserved" 13 "Reserved" 12 "Reserved" 11 "Reserved" 10 "Reserved" 9 "Reserved" 8 "Reserved" 7 "S挡" 6 "E挡" 5 "Reserved" 4 "D挡" 3 "R挡" 2 "N挡" 1 "P挡" 0 "Undefined" ;
VAL_ 560 VCU_STRATEGY_SHIFT_POSN_FLAG 3 "Value unreliable" 2 "Not used" 1 "Not used" 0 "Value OK" ;
VAL_ 566 VCU_ChrgDchaGunCnctnSts 7 "Invalid" 6 "Reserved" 5 "Reserved" 4 "VTOL放电枪完全连接" 3 "充放电枪完全连接" 2 "半连接状态" 1 "未连接状态" 0 "初始值" ;
VAL_ 566 VCU_S2SwtSts 3 "Invalid" 2 "闭合" 1 "断开" 0 "初始值" ;
VAL_ 619 MCU_STS_MNGT_STS 10 "关管状态" 9 "主动放电状态" 8 "防溜车过渡状态" 6 "防溜车状态" 3 "零扭矩状态" 1 "驱动扭矩状态" ;
VAL_ 619 MCU_STS_MNGT_OUPT_TRQ 65535 "Invalid" ;
VAL_ 619 MCU_TRQ_MNGT_OUPT_TRQ 65535 "Invalid" ;
VAL_ 834 VCU_ADA_SLIDE_REQ_FLG 1 "请求；" 0 "未请求；" ;
VAL_ 835 MCU_F_KL15ON_flg 1 "KL15 ON唤醒" 0 "非KL15 ON唤醒" ;
VAL_ 835 MCU_REQ_VCU_FLG 5 "降功率" 4 "零转矩" 3 "Void" 2 "不使能" 1 "断高压" 0 "Void" ;
VAL_ 835 MCU_MOT_TEMP 255 "Invalid" ;
VAL_ 835 MCUFLaultLevel 15 "Reserved" 14 "Reserved" 13 "Reserved" 12 "Reserved" 11 "Reserved" 10 "Reserved" 9 "Reserved" 8 "Reserved" 7 "Reserved" 6 "无限制(不处理)" 5 "限功率" 4 "跛行" 3 "零扭矩" 2 "延迟断高压" 1 "立即下高压(禁止高压上电)" 0 "初始值" ;
VAL_ 835 MCU_IGBT_TEMP 255 "Invalid" ;
VAL_ 835 MCU_CLOSE_ENA_FKG 1 "有请求" 0 "无请求" ;
VAL_ 835 MCU_ZERO_TOQ_FLG 1 "有请求" 0 "无请求" ;
VAL_ 835 MCU_MOT_FAULT_LAMP 3 "Void" 2 "Void" 1 "异常" 0 "正常" ;
VAL_ 835 MCU_ALARM_LEVEL_MAX 3 "三级故障" 2 "二级故障" 1 "一级故障" 0 "无故障" ;
VAL_ 837 MCU_DC_SEN_DRIFT 1 "异常" 0 "正常" ;
VAL_ 837 MCU_CUR_SAMP_CIR_U 1 "异常" 0 "正常" ;
VAL_ 837 MCU_CUR_SAMP_CIR_V 1 "异常" 0 "正常" ;
VAL_ 837 MCU_CUR_SAMP_CIR_W 1 "异常" 0 "正常" ;
VAL_ 837 MCU_DC_SAMP_CUR 1 "异常" 0 "正常" ;
VAL_ 837 MCU_3PHASE_CUR_CHE_FAULT 1 "异常" 0 "正常" ;
VAL_ 837 MCU_BUSBAR_VOLT_LOW 1 "异常" 0 "正常" ;
VAL_ 837 MCU_BUSBAR_VOLT_HIGH 1 "异常" 0 "正常" ;
VAL_ 837 MCU_BUS_VOLIT_SAMP_FAULT 1 "异常" 0 "正常" ;
VAL_ 837 MCU_OVER_SPD_FAULT 1 "异常" 0 "正常" ;
VAL_ 837 MCU_IGBT_TEMP_OVER_U 1 "异常" 0 "正常" ;
VAL_ 837 MCU_IGBT_TEMP_OVER_V 1 "异常" 0 "正常" ;
VAL_ 837 MCU_IGBT_TEMP_OVER_W 1 "异常" 0 "正常" ;
VAL_ 837 MCU_IGBT_TEMP_CHECK_CUR_U 1 "异常" 0 "正常" ;
VAL_ 837 MCU_IGBT_TEMP_CHECK_CUR_V 1 "异常" 0 "正常" ;
VAL_ 837 MCU_IGBT_TEMP_CHECK_CUR_W 1 "异常" 0 "正常" ;
VAL_ 837 MCU_MOTOR_TEMP_OVER 1 "异常" 0 "正常" ;
VAL_ 837 MCU_MOT_TEMP_CHECK_CUR 1 "异常" 0 "正常" ;
VAL_ 837 MCU_MCU_TEMP_OVER 1 "异常" 0 "正常" ;
VAL_ 837 MCUPowOnIniFlt 1 "异常" 0 "正常" ;
VAL_ 837 MCU_BATT_VOLT_LOW 1 "异常" 0 "正常" ;
VAL_ 837 MCU_BATT_VOLT_HIGH 1 "异常" 0 "正常" ;
VAL_ 837 MCU_F_PosZeroErr 1 "故障" 0 "无故障" ;
VAL_ 837 MCU_HW_CUR_HIGH_W 1 "异常" 0 "正常" ;
VAL_ 837 MCU_FEED_TOR_ORDER_CHE_FAULT 1 "异常" 0 "正常" ;
VAL_ 837 MCU_HL_VOLT_INTERLOCK_FAULT 1 "异常" 0 "正常" ;
VAL_ 837 MCU_SW_CUR_HIGH 1 "异常" 0 "正常" ;
VAL_ 837 MCU_HW_CUR_HIGH_U 1 "异常" 0 "正常" ;
VAL_ 837 MCU_HW_CUR_HIGH_V 1 "异常" 0 "正常" ;
VAL_ 837 MCU_EAS_HL_INTERLOCK_FAULT 1 "异常" 0 "正常" ;
VAL_ 837 MCU_PTC_HL_INTERLOCK_FAULT 1 "异常" 0 "正常" ;
VAL_ 837 MCU_BATT_HL_INTERLOCK_FAULT 1 "异常" 0 "正常" ;
VAL_ 837 MCU_MC_HL_INTERLOCK_FAULT 1 "异常" 0 "正常" ;
VAL_ 837 MCU_QC_HL_INTERLOCK_FAULT 1 "异常" 0 "正常" ;
VAL_ 838 MCU_COM_VCU_LOSE 1 "异常" 0 "正常" ;
VAL_ 838 McuActDchFlt 1 "异常" 0 "正常" ;
VAL_ 838 McuSafStaCheFlt 1 "异常" 0 "正常" ;
VAL_ 838 McuDcCurHighFlt 1 "异常" 0 "正常" ;
VAL_ 838 Mot3PhaLoseFlt 1 "异常" 0 "正常" ;
VAL_ 838 McuMstChipFlt 1 "异常" 0 "正常" ;
VAL_ 838 IGBT3PhaseTChecFlt 1 "异常" 0 "正常" ;
VAL_ 838 McuIntComFlt 1 "异常" 0 "正常" ;
VAL_ 838 IntTorChecFlt 1 "异常" 0 "正常" ;
VAL_ 838 RunModFlt 1 "异常" 0 "正常" ;
VAL_ 838 MCU_IGBI_UPPR_BRDG_FLT_U 1 "异常" 0 "正常" ;
VAL_ 838 MCU_IGBI_LOWR_BRDG_FLT_U 1 "异常" 0 "正常" ;
VAL_ 838 MCU_IGBI_UPPR_BRDG_FLT_V 1 "异常" 0 "正常" ;
VAL_ 838 MCU_IGBI_LOWR_BRDG_FLT_V 1 "异常" 0 "正常" ;
VAL_ 838 MCU_IGBI_UPPR_BRDG_FLT_W 1 "异常" 0 "正常" ;
VAL_ 838 MCU_IGBI_LOWR_BRDG_FLT_W 1 "异常" 0 "正常" ;
VAL_ 838 MCU_WAKE_SIG_FLT 1 "异常" 0 "正常" ;
VAL_ 838 McuSwCurHighU 1 "异常" 0 "正常" ;
VAL_ 838 McuSwCurHighV 1 "异常" 0 "正常" ;
VAL_ 838 McuSwCurHighW 1 "异常" 0 "正常" ;
VAL_ 838 McuBattModFlt 1 "异常" 0 "正常" ;
VAL_ 838 McuConTempCheckCurFlt 1 "异常" 0 "正常" ;
VAL_ 838 McuPosCheckCurFlt 1 "异常" 0 "正常" ;
VAL_ 838 MCU_E2E_ERR 1 "异常" 0 "正常" ;
VAL_ 855 VCU_OTAClsChrgCmd 1 "关闭" 0 "初始值" ;
VAL_ 295 McuApsPer 255 "Invalid" ;
VAL_ 295 McuApsPerFlag 3 "Reserved" 2 "Invalid" 1 "Valid" 0 "Initializing" ;
VAL_ 295 McuMotDampgFobdFlg 1 "禁止" 0 "未禁止" ;
VAL_ 295 DrvTorReqFlg 3 "Reserved" 2 "Invalid" 1 "Vaild" 0 "Initializing" ;
VAL_ 1387 BMS_CELL_TEMP_MIN 255 "Invalid" ;
VAL_ 513 BMS_OBC_CMD 7 "无效值" 6 "void" 5 "休眠指令" 4 "停机指令" 3 "电源指令" 2 "工作指令" 1 "待机指令" 0 "初始值" ;
VAL_ 513 BMS_S2_SW_CMD 3 "无效值" 2 "断开指令" 1 "闭合指令" 0 "初始值" ;
VAL_ 513 BMS_S1_SWT_CMD 3 "无效值" 2 "PWM指令" 1 "电平指令" 0 "初始值" ;
VAL_ 513 BMS_VEH_MODE 7 "无效值" 6 "void" 5 "void" 4 "直流充电模式" 3 "VTOV放电模式" 2 "VTOL放电模式" 1 "交流充电模式" 0 "初始值" ;
VAL_ 535 BMS_SELF_CHECK_COUNTER 3 "检测3" 2 "检测2" 1 "检测1" 0 "检测0" ;
VAL_ 536 BMS_BATT_CUR 65535 "Invalid" ;
VAL_ 276 VCUVehFaultLevel 15 "Reserved" 14 "Reserved" 13 "Reserved" 12 "Reserved" 11 "Reserved" 10 "Reserved" 9 "Reserved" 8 "Reserved" 7 "Reserved" 6 "无限制（不处理）" 5 "限功率" 4 "跛行" 3 "零扭矩" 2 "延迟断高压" 1 "立即下高压（禁止高压上电）" 0 "初始值" ;
VAL_ 276 WormEnaFlg 1 "Enable" 0 "Disable" ;
VAL_ 276 DrivSysActFlg 1 "Enable" 0 "Disable" ;
VAL_ 276 ABSActFlg 1 "Enable" 0 "Disable" ;
VAL_ 276 CRBSActFlg 1 "Enable" 0 "Disable" ;
VAL_ 276 ACCActFlg 1 "Enable" 0 "Disable" ;
VAL_ 276 TorEnaFlg 1 "Enable" 0 "Disable" ;
VAL_ 276 BmsEngRecForbFlg 1 "Enable" 0 "Disable" ;
VAL_ 276 WheelHubMod 1 "Enable" 0 "Disable" ;
VAL_ 276 SpeedLimFlg 10 "预留" 9 "预留" 8 "预留" 7 "预留" 6 "预留" 5 "预留" 4 "预留" 3 "限速60km/h" 2 "限速30km/h" 1 "限速15km/h" 0 "原车速" ;
VAL_ 276 DrivAntiSliSwt 1 "功能打开" 0 "功能关闭" ;
VAL_ 276 RecAntiSliSwt 1 "功能打开" 0 "功能关闭" ;
VAL_ 276 AbsArbSwt 1 "功能打开" 0 "功能关闭" ;
VAL_ 276 TcsArbSwt 1 "功能打开" 0 "功能关闭" ;
VAL_ 276 DtcArbSwt 1 "功能打开" 0 "功能关闭" ;
VAL_ 277 McuAlrmLampFS 1 "Enable(灯亮)" 0 "Disable(灯灭)" ;
VAL_ 277 FrOnEspTorArbSta 10 "Reserve" 9 "Reserve" 8 "Reserve" 7 "DTC&Regen ASR Active" 6 "ASR Acctive" 5 "Regen ASR Active" 4 "TCS Active" 3 "DTC Active" 2 "ABS Active" 1 "Default" 0 "Initial" ;
VAL_ 277 McuMotWheelTorValid 3 "Reserved" 2 "Invalid" 1 "Valid" 0 "Initializing" ;
VAL_ 1268 OTAHVPwrMod 7 "Void" 6 "Reserved" 5 "非OTA模式" 4 "高压2（禁言）刷写模式" 3 "高压1刷写模式" 2 "低压刷写模式" 1 "下载高压模式" 0 "初始值" ;
VAL_ 753 TrOpenStsSwt 7 "Reserved" 6 "Reserved" 5 "Reserved" 4 "Closing" 3 "opening" 2 "close" 1 "Open" 0 "Stop" ;
VAL_ 753 DrvrDoorOpenStsSwt 3 "Invalid(Reserved)" 2 "Open" 1 "Closed" 0 "Reserved" ;
VAL_ 753 PassDoorOpenStsSwt 3 "Invalid(Reserved)" 2 "Open" 1 "Closed" 0 "Reserved" ;
VAL_ 753 ReLeDoorOpenStsSwt 3 "Invalid(Reserved)" 2 "Open" 1 "Closed" 0 "Reserved" ;
VAL_ 753 ReRiDoorOpenStsSwt 3 "Invalid(Reserved)" 2 "Open" 1 "Closed" 0 "Reserved" ;
VAL_ 753 HoodLidOpenStsSwt 3 "Invalid(Reserved)" 2 "Open" 1 "Closed" 0 "Reserved" ;
VAL_ 753 BdcVehMod 7 "Rerserved" 6 "Gallery Mode（预留）" 5 "Test Mode（预留）" 4 "Crash Mode（预留）" 3 "Transport Mode" 2 "Factory Mode（default）" 1 "Normal Mode" 0 "initialization" ;
VAL_ 1361 TBOX_CrtTi_Day 30 "Day31" 0 "Day1" ;
VAL_ 1361 TBOX_CrtTi_Hr 23 "Hour 23" 0 "Hour 0" ;
VAL_ 1361 TBOX_CrtTi_Mins 59 "Mintue 59" 0 "Mintue 0" ;
VAL_ 1361 TBOX_CrtTi_Yr 255 "Year2270" 0 "Year 2015" ;
VAL_ 1361 TBOX_CrtTi_Mth 11 "December" 0 "January" ;
VAL_ 1361 TBOX_CrtTi_Sec 59 "Second 59" 0 "Second 0" ;
VAL_ 389 FrntRiWhlSpd 32767 "Invalid" ;
VAL_ 389 FrntRiWhlSpdVld 3 "Reserved" 2 "Invalid" 1 "Valid" 0 "Initializing" ;
VAL_ 389 FrntLeWhlSpd 32767 "Invalid" ;
VAL_ 389 FrntLeWhlSpdVld 3 "Reserved" 2 "Invalid" 1 "Valid" 0 "Initializing" ;
VAL_ 389 ReRiWhlSpd 32767 "Invalid" ;
VAL_ 389 ReRiWhlSpdVld 3 "Reserved" 2 "Invalid" 1 "Valid" 0 "Initializing" ;
VAL_ 389 ReLeWhlSpd 32767 "Invalid" ;
VAL_ 389 ReLeWhlSpdVld 3 "Reserved" 2 "Invalid" 1 "Valid" 0 "Initializing" ;
VAL_ 389 VehStop 3 "Reserved" 2 "Invalid" 1 "Standstill" 0 "Not standstill" ;
VAL_ 389 VehSpdVld 3 "Reserved" 2 "Invalid" 1 "Valid" 0 "Initializing" ;
VAL_ 389 VehSpd 65535 "Invalid" ;
VAL_ 433 PwrMod 3 "CRANK" 2 "IGN ON" 1 "ACC(Reserved)" 0 "OFF" ;
VAL_ 433 PwrModVld 3 "reserved" 2 "Vaild" 1 "Invalid" 0 "Reserved" ;
VAL_ 281 EGSMFltSts 15 "Invalid" 14 "控制器故障" 13 "Unknow Error" 12 "Missing CAN Messages(s)" 11 "CAN Bus Off" 10 "Reserved" 9 "P button fault" 8 "System Voltage Out of Range (Undervoltage or Overvoltage )" 7 "Reserved" 6 "Reserved" 5 "Reserved" 4 "Reserved" 3 "Shift position sensor 2 fail" 2 "Shift position sensor 1 fail" 1 "Shift position sensor all fail" 0 "No Fault" ;
VAL_ 281 EGSMGearLvrCrtPosnInfo 7 "Sensors fault 传感器故障" 6 "Reseved 预留" 5 "Reseved 预留" 4 "The Gear Lever Clockwise To The 2nd Dynamic Point 怀挡手柄顺时针旋到第二段行程" 3 "The Gear Lever Clockwise To The First Dynamic Point 怀挡手柄顺时针旋到第一段行程" 2 "The Gear Lever Counter Clockwise To The 2nd Dynamic Point 怀挡手柄逆时针旋到第二段行程" 1 "The Gear Lever Counter Clockwise To The First Dynamic Point 怀挡手柄逆时针旋到第1段行程" 0 "The Gear Lever Is At The Origin Position 怀挡手柄处于原点位置" ;
VAL_ 304 ActTqVld 3 "Reserved" 2 "Invalid" 1 "Vaild" 0 "Initializing" ;
VAL_ 822 BleStopEng 1 "Acitve" 0 "Inactive" ;
VAL_ 822 BleStrtEng 1 "Acitve" 0 "Inactive" ;
VAL_ 822 RemCtrlDrvgReq 3 "Reserved" 2 "退出遥控驾驶" 1 "进入遥控驾驶" 0 "初始值" ;
VAL_ 822 BleCarCtrlAPPHertbtSig 7 "预留" 6 "预留" 5 "预留" 4 "预留" 3 "预留" 2 "驾驶界面" 1 "逗娃界面" 0 "初始值" ;
VAL_ 822 BleChildTeasSouSta 3 "预留" 2 "关闭" 1 "开启" 0 "初始值" ;
VAL_ 305 EmsEngWrmUpAch 1 "True" 0 "False" ;
VAL_ 998 EmsDrvgCyc 1 "in driving cycle" 0 "not in driving cycle" ;
